// *************************************************************************** *
// *                                                                           *
// * Description:         CANDB File                                           *
// * Generated at:        2025-01-24 12:56                                     *
// * System:              SDB22436                                             *
// * Variant:             L946_ADCU9_ZCUDM                                     *
// * Network:             BodyExposedCAN                                       *
// *                                                                           *
// *************************************************************************** *
VERSION "BodyExposedCAN"

NS_ :

BS_ :

BU_ :  ETC HCML HCMR ZCUD

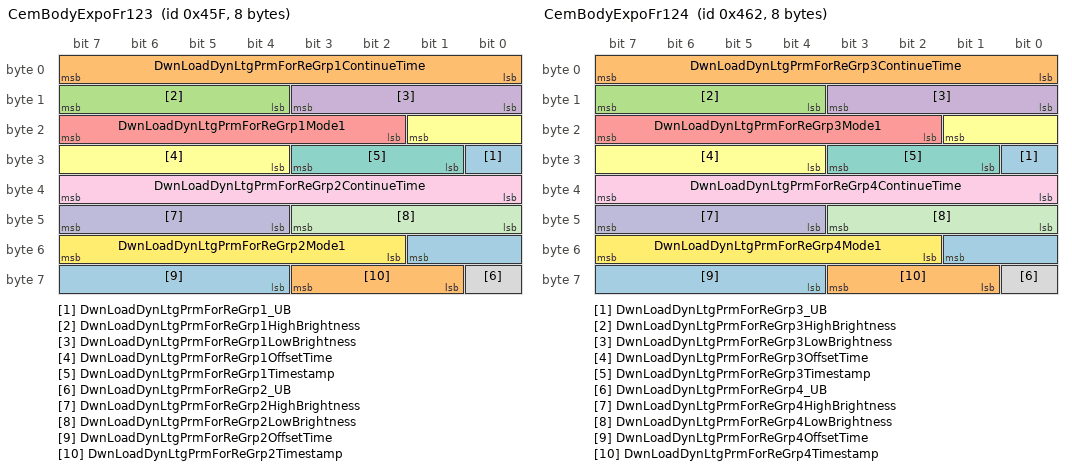
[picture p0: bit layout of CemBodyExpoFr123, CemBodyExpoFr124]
BO_ 1119 CemBodyExpoFr123 : 8 ZCUD
 SG_ DwnLoadDynLtgPrmForReGrp1_UB : 24|1@0+ (1,0) [0|1] "" Vector__XXX
 SG_ DwnLoadDynLtgPrmForReGrp1ContinueTime : 7|8@0+ (1.0,0.0) [0.0|255.0] "Unitless" Vector__XXX
 SG_ DwnLoadDynLtgPrmForReGrp1HighBrightness : 15|4@0+ (1.0,0.0) [0.0|10.0] "Unitless" Vector__XXX
 SG_ DwnLoadDynLtgPrmForReGrp1LowBrightness : 11|4@0+ (1.0,0.0) [0.0|10.0] "Unitless" Vector__XXX
 SG_ DwnLoadDynLtgPrmForReGrp1Mode1 : 23|6@0+ (1,0) [0|63] "" Vector__XXX
 SG_ DwnLoadDynLtgPrmForReGrp1OffsetTime : 17|6@0+ (1.0,0.0) [0.0|63.0] "Unitless" Vector__XXX
 SG_ DwnLoadDynLtgPrmForReGrp1Timestamp : 27|3@0+ (1.0,0.0) [0.0|7.0] "Unitless" Vector__XXX
 SG_ DwnLoadDynLtgPrmForReGrp2_UB : 56|1@0+ (1,0) [0|1] "" Vector__XXX
 SG_ DwnLoadDynLtgPrmForReGrp2ContinueTime : 39|8@0+ (1.0,0.0) [0.0|255.0] "Unitless" Vector__XXX
 SG_ DwnLoadDynLtgPrmForReGrp2HighBrightness : 47|4@0+ (1.0,0.0) [0.0|10.0] "Unitless" Vector__XXX
 SG_ DwnLoadDynLtgPrmForReGrp2LowBrightness : 43|4@0+ (1.0,0.0) [0.0|10.0] "Unitless" Vector__XXX
 SG_ DwnLoadDynLtgPrmForReGrp2Mode1 : 55|6@0+ (1,0) [0|63] "" Vector__XXX
 SG_ DwnLoadDynLtgPrmForReGrp2OffsetTime : 49|6@0+ (1.0,0.0) [0.0|63.0] "Unitless" Vector__XXX
 SG_ DwnLoadDynLtgPrmForReGrp2Timestamp : 59|3@0+ (1.0,0.0) [0.0|7.0] "Unitless" Vector__XXX

BO_ 1122 CemBodyExpoFr124 : 8 ZCUD
 SG_ DwnLoadDynLtgPrmForReGrp3_UB : 24|1@0+ (1,0) [0|1] "" Vector__XXX
 SG_ DwnLoadDynLtgPrmForReGrp3ContinueTime : 7|8@0+ (1.0,0.0) [0.0|255.0] "Unitless" Vector__XXX
 SG_ DwnLoadDynLtgPrmForReGrp3HighBrightness : 15|4@0+ (1.0,0.0) [0.0|10.0] "Unitless" Vector__XXX
 SG_ DwnLoadDynLtgPrmForReGrp3LowBrightness : 11|4@0+ (1.0,0.0) [0.0|10.0] "Unitless" Vector__XXX
 SG_ DwnLoadDynLtgPrmForReGrp3Mode1 : 23|6@0+ (1,0) [0|63] "" Vector__XXX
 SG_ DwnLoadDynLtgPrmForReGrp3OffsetTime : 17|6@0+ (1.0,0.0) [0.0|63.0] "Unitless" Vector__XXX
 SG_ DwnLoadDynLtgPrmForReGrp3Timestamp : 27|3@0+ (1.0,0.0) [0.0|7.0] "Unitless" Vector__XXX
 SG_ DwnLoadDynLtgPrmForReGrp4_UB : 56|1@0+ (1,0) [0|1] "" Vector__XXX
 SG_ DwnLoadDynLtgPrmForReGrp4ContinueTime : 39|8@0+ (1.0,0.0) [0.0|255.0] "Unitless" Vector__XXX
 SG_ DwnLoadDynLtgPrmForReGrp4HighBrightness : 47|4@0+ (1.0,0.0) [0.0|10.0] "Unitless" Vector__XXX
 SG_ DwnLoadDynLtgPrmForReGrp4LowBrightness : 43|4@0+ (1.0,0.0) [0.0|10.0] "Unitless" Vector__XXX
 SG_ DwnLoadDynLtgPrmForReGrp4Mode1 : 55|6@0+ (1,0) [0|63] "" Vector__XXX
 SG_ DwnLoadDynLtgPrmForReGrp4OffsetTime : 49|6@0+ (1.0,0.0) [0.0|63.0] "Unitless" Vector__XXX
 SG_ DwnLoadDynLtgPrmForReGrp4Timestamp : 59|3@0+ (1.0,0.0) [0.0|7.0] "Unitless" Vector__XXX

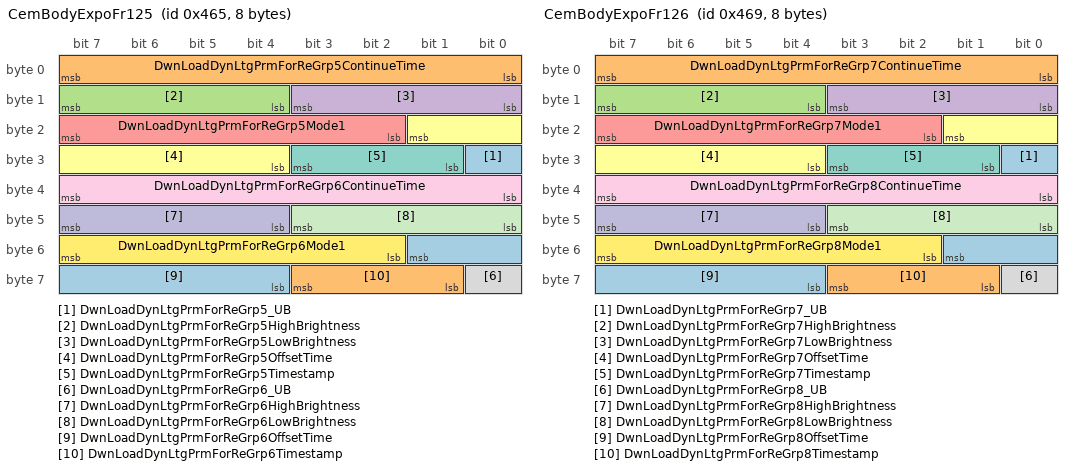
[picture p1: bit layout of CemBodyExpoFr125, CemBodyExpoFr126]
BO_ 1125 CemBodyExpoFr125 : 8 ZCUD
 SG_ DwnLoadDynLtgPrmForReGrp5_UB : 24|1@0+ (1,0) [0|1] "" Vector__XXX
 SG_ DwnLoadDynLtgPrmForReGrp5ContinueTime : 7|8@0+ (1.0,0.0) [0.0|255.0] "Unitless" Vector__XXX
 SG_ DwnLoadDynLtgPrmForReGrp5HighBrightness : 15|4@0+ (1.0,0.0) [0.0|10.0] "Unitless" Vector__XXX
 SG_ DwnLoadDynLtgPrmForReGrp5LowBrightness : 11|4@0+ (1.0,0.0) [0.0|10.0] "Unitless" Vector__XXX
 SG_ DwnLoadDynLtgPrmForReGrp5Mode1 : 23|6@0+ (1,0) [0|63] "" Vector__XXX
 SG_ DwnLoadDynLtgPrmForReGrp5OffsetTime : 17|6@0+ (1.0,0.0) [0.0|63.0] "Unitless" Vector__XXX
 SG_ DwnLoadDynLtgPrmForReGrp5Timestamp : 27|3@0+ (1.0,0.0) [0.0|7.0] "Unitless" Vector__XXX
 SG_ DwnLoadDynLtgPrmForReGrp6_UB : 56|1@0+ (1,0) [0|1] "" Vector__XXX
 SG_ DwnLoadDynLtgPrmForReGrp6ContinueTime : 39|8@0+ (1.0,0.0) [0.0|255.0] "Unitless" Vector__XXX
 SG_ DwnLoadDynLtgPrmForReGrp6HighBrightness : 47|4@0+ (1.0,0.0) [0.0|10.0] "Unitless" Vector__XXX
 SG_ DwnLoadDynLtgPrmForReGrp6LowBrightness : 43|4@0+ (1.0,0.0) [0.0|10.0] "Unitless" Vector__XXX
 SG_ DwnLoadDynLtgPrmForReGrp6Mode1 : 55|6@0+ (1,0) [0|63] "" Vector__XXX
 SG_ DwnLoadDynLtgPrmForReGrp6OffsetTime : 49|6@0+ (1.0,0.0) [0.0|63.0] "Unitless" Vector__XXX
 SG_ DwnLoadDynLtgPrmForReGrp6Timestamp : 59|3@0+ (1.0,0.0) [0.0|7.0] "Unitless" Vector__XXX

BO_ 1129 CemBodyExpoFr126 : 8 ZCUD
 SG_ DwnLoadDynLtgPrmForReGrp7_UB : 24|1@0+ (1,0) [0|1] "" Vector__XXX
 SG_ DwnLoadDynLtgPrmForReGrp7ContinueTime : 7|8@0+ (1.0,0.0) [0.0|255.0] "Unitless" Vector__XXX
 SG_ DwnLoadDynLtgPrmForReGrp7HighBrightness : 15|4@0+ (1.0,0.0) [0.0|10.0] "Unitless" Vector__XXX
 SG_ DwnLoadDynLtgPrmForReGrp7LowBrightness : 11|4@0+ (1.0,0.0) [0.0|10.0] "Unitless" Vector__XXX
 SG_ DwnLoadDynLtgPrmForReGrp7Mode1 : 23|6@0+ (1,0) [0|63] "" Vector__XXX
 SG_ DwnLoadDynLtgPrmForReGrp7OffsetTime : 17|6@0+ (1.0,0.0) [0.0|63.0] "Unitless" Vector__XXX
 SG_ DwnLoadDynLtgPrmForReGrp7Timestamp : 27|3@0+ (1.0,0.0) [0.0|7.0] "Unitless" Vector__XXX
 SG_ DwnLoadDynLtgPrmForReGrp8_UB : 56|1@0+ (1,0) [0|1] "" Vector__XXX
 SG_ DwnLoadDynLtgPrmForReGrp8ContinueTime : 39|8@0+ (1.0,0.0) [0.0|255.0] "Unitless" Vector__XXX
 SG_ DwnLoadDynLtgPrmForReGrp8HighBrightness : 47|4@0+ (1.0,0.0) [0.0|10.0] "Unitless" Vector__XXX
 SG_ DwnLoadDynLtgPrmForReGrp8LowBrightness : 43|4@0+ (1.0,0.0) [0.0|10.0] "Unitless" Vector__XXX
 SG_ DwnLoadDynLtgPrmForReGrp8Mode1 : 55|6@0+ (1,0) [0|63] "" Vector__XXX
 SG_ DwnLoadDynLtgPrmForReGrp8OffsetTime : 49|6@0+ (1.0,0.0) [0.0|63.0] "Unitless" Vector__XXX
 SG_ DwnLoadDynLtgPrmForReGrp8Timestamp : 59|3@0+ (1.0,0.0) [0.0|7.0] "Unitless" Vector__XXX

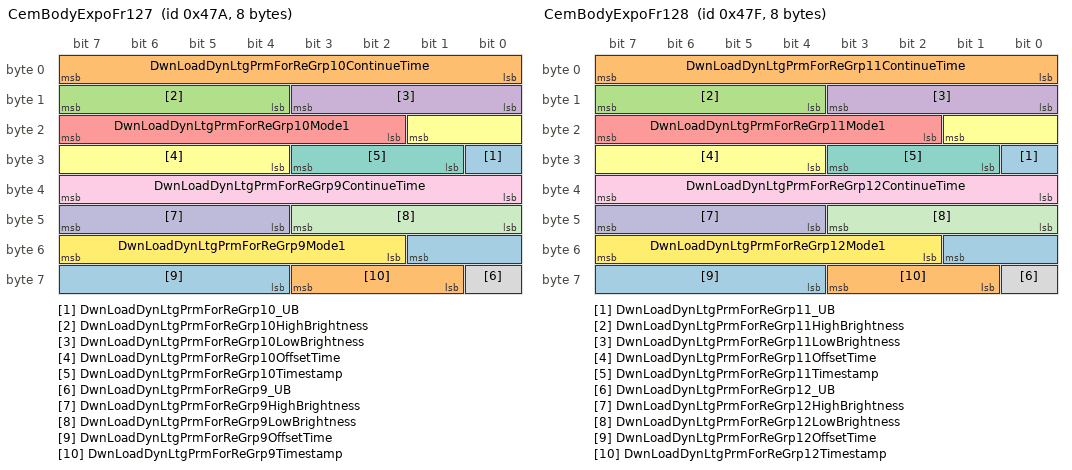
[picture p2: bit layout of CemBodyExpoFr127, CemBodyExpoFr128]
BO_ 1146 CemBodyExpoFr127 : 8 ZCUD
 SG_ DwnLoadDynLtgPrmForReGrp10_UB : 24|1@0+ (1,0) [0|1] "" Vector__XXX
 SG_ DwnLoadDynLtgPrmForReGrp10ContinueTime : 7|8@0+ (1.0,0.0) [0.0|255.0] "Unitless" Vector__XXX
 SG_ DwnLoadDynLtgPrmForReGrp10HighBrightness : 15|4@0+ (1.0,0.0) [0.0|10.0] "Unitless" Vector__XXX
 SG_ DwnLoadDynLtgPrmForReGrp10LowBrightness : 11|4@0+ (1.0,0.0) [0.0|10.0] "Unitless" Vector__XXX
 SG_ DwnLoadDynLtgPrmForReGrp10Mode1 : 23|6@0+ (1,0) [0|63] "" Vector__XXX
 SG_ DwnLoadDynLtgPrmForReGrp10OffsetTime : 17|6@0+ (1.0,0.0) [0.0|63.0] "Unitless" Vector__XXX
 SG_ DwnLoadDynLtgPrmForReGrp10Timestamp : 27|3@0+ (1.0,0.0) [0.0|7.0] "Unitless" Vector__XXX
 SG_ DwnLoadDynLtgPrmForReGrp9_UB : 56|1@0+ (1,0) [0|1] "" Vector__XXX
 SG_ DwnLoadDynLtgPrmForReGrp9ContinueTime : 39|8@0+ (1.0,0.0) [0.0|255.0] "Unitless" Vector__XXX
 SG_ DwnLoadDynLtgPrmForReGrp9HighBrightness : 47|4@0+ (1.0,0.0) [0.0|10.0] "Unitless" Vector__XXX
 SG_ DwnLoadDynLtgPrmForReGrp9LowBrightness : 43|4@0+ (1.0,0.0) [0.0|10.0] "Unitless" Vector__XXX
 SG_ DwnLoadDynLtgPrmForReGrp9Mode1 : 55|6@0+ (1,0) [0|63] "" Vector__XXX
 SG_ DwnLoadDynLtgPrmForReGrp9OffsetTime : 49|6@0+ (1.0,0.0) [0.0|63.0] "Unitless" Vector__XXX
 SG_ DwnLoadDynLtgPrmForReGrp9Timestamp : 59|3@0+ (1.0,0.0) [0.0|7.0] "Unitless" Vector__XXX

BO_ 1151 CemBodyExpoFr128 : 8 ZCUD
 SG_ DwnLoadDynLtgPrmForReGrp11_UB : 24|1@0+ (1,0) [0|1] "" Vector__XXX
 SG_ DwnLoadDynLtgPrmForReGrp11ContinueTime : 7|8@0+ (1.0,0.0) [0.0|255.0] "Unitless" Vector__XXX
 SG_ DwnLoadDynLtgPrmForReGrp11HighBrightness : 15|4@0+ (1.0,0.0) [0.0|10.0] "Unitless" Vector__XXX
 SG_ DwnLoadDynLtgPrmForReGrp11LowBrightness : 11|4@0+ (1.0,0.0) [0.0|10.0] "Unitless" Vector__XXX
 SG_ DwnLoadDynLtgPrmForReGrp11Mode1 : 23|6@0+ (1,0) [0|63] "" Vector__XXX
 SG_ DwnLoadDynLtgPrmForReGrp11OffsetTime : 17|6@0+ (1.0,0.0) [0.0|63.0] "Unitless" Vector__XXX
 SG_ DwnLoadDynLtgPrmForReGrp11Timestamp : 27|3@0+ (1.0,0.0) [0.0|7.0] "Unitless" Vector__XXX
 SG_ DwnLoadDynLtgPrmForReGrp12_UB : 56|1@0+ (1,0) [0|1] "" Vector__XXX
 SG_ DwnLoadDynLtgPrmForReGrp12ContinueTime : 39|8@0+ (1.0,0.0) [0.0|255.0] "Unitless" Vector__XXX
 SG_ DwnLoadDynLtgPrmForReGrp12HighBrightness : 47|4@0+ (1.0,0.0) [0.0|10.0] "Unitless" Vector__XXX
 SG_ DwnLoadDynLtgPrmForReGrp12LowBrightness : 43|4@0+ (1.0,0.0) [0.0|10.0] "Unitless" Vector__XXX
 SG_ DwnLoadDynLtgPrmForReGrp12Mode1 : 55|6@0+ (1,0) [0|63] "" Vector__XXX
 SG_ DwnLoadDynLtgPrmForReGrp12OffsetTime : 49|6@0+ (1.0,0.0) [0.0|63.0] "Unitless" Vector__XXX
 SG_ DwnLoadDynLtgPrmForReGrp12Timestamp : 59|3@0+ (1.0,0.0) [0.0|7.0] "Unitless" Vector__XXX

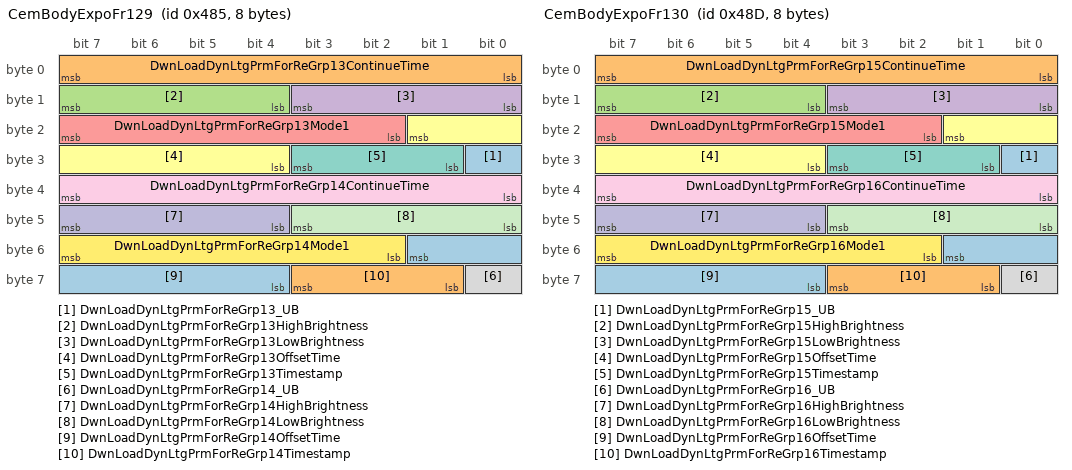
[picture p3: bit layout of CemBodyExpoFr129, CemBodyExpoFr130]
BO_ 1157 CemBodyExpoFr129 : 8 ZCUD
 SG_ DwnLoadDynLtgPrmForReGrp13_UB : 24|1@0+ (1,0) [0|1] "" Vector__XXX
 SG_ DwnLoadDynLtgPrmForReGrp13ContinueTime : 7|8@0+ (1.0,0.0) [0.0|255.0] "Unitless" Vector__XXX
 SG_ DwnLoadDynLtgPrmForReGrp13HighBrightness : 15|4@0+ (1.0,0.0) [0.0|10.0] "Unitless" Vector__XXX
 SG_ DwnLoadDynLtgPrmForReGrp13LowBrightness : 11|4@0+ (1.0,0.0) [0.0|10.0] "Unitless" Vector__XXX
 SG_ DwnLoadDynLtgPrmForReGrp13Mode1 : 23|6@0+ (1,0) [0|63] "" Vector__XXX
 SG_ DwnLoadDynLtgPrmForReGrp13OffsetTime : 17|6@0+ (1.0,0.0) [0.0|63.0] "Unitless" Vector__XXX
 SG_ DwnLoadDynLtgPrmForReGrp13Timestamp : 27|3@0+ (1.0,0.0) [0.0|7.0] "Unitless" Vector__XXX
 SG_ DwnLoadDynLtgPrmForReGrp14_UB : 56|1@0+ (1,0) [0|1] "" Vector__XXX
 SG_ DwnLoadDynLtgPrmForReGrp14ContinueTime : 39|8@0+ (1.0,0.0) [0.0|255.0] "Unitless" Vector__XXX
 SG_ DwnLoadDynLtgPrmForReGrp14HighBrightness : 47|4@0+ (1.0,0.0) [0.0|10.0] "Unitless" Vector__XXX
 SG_ DwnLoadDynLtgPrmForReGrp14LowBrightness : 43|4@0+ (1.0,0.0) [0.0|10.0] "Unitless" Vector__XXX
 SG_ DwnLoadDynLtgPrmForReGrp14Mode1 : 55|6@0+ (1,0) [0|63] "" Vector__XXX
 SG_ DwnLoadDynLtgPrmForReGrp14OffsetTime : 49|6@0+ (1.0,0.0) [0.0|63.0] "Unitless" Vector__XXX
 SG_ DwnLoadDynLtgPrmForReGrp14Timestamp : 59|3@0+ (1.0,0.0) [0.0|7.0] "Unitless" Vector__XXX

BO_ 1165 CemBodyExpoFr130 : 8 ZCUD
 SG_ DwnLoadDynLtgPrmForReGrp15_UB : 24|1@0+ (1,0) [0|1] "" Vector__XXX
 SG_ DwnLoadDynLtgPrmForReGrp15ContinueTime : 7|8@0+ (1.0,0.0) [0.0|255.0] "Unitless" Vector__XXX
 SG_ DwnLoadDynLtgPrmForReGrp15HighBrightness : 15|4@0+ (1.0,0.0) [0.0|10.0] "Unitless" Vector__XXX
 SG_ DwnLoadDynLtgPrmForReGrp15LowBrightness : 11|4@0+ (1.0,0.0) [0.0|10.0] "Unitless" Vector__XXX
 SG_ DwnLoadDynLtgPrmForReGrp15Mode1 : 23|6@0+ (1,0) [0|63] "" Vector__XXX
 SG_ DwnLoadDynLtgPrmForReGrp15OffsetTime : 17|6@0+ (1.0,0.0) [0.0|63.0] "Unitless" Vector__XXX
 SG_ DwnLoadDynLtgPrmForReGrp15Timestamp : 27|3@0+ (1.0,0.0) [0.0|7.0] "Unitless" Vector__XXX
 SG_ DwnLoadDynLtgPrmForReGrp16_UB : 56|1@0+ (1,0) [0|1] "" Vector__XXX
 SG_ DwnLoadDynLtgPrmForReGrp16ContinueTime : 39|8@0+ (1.0,0.0) [0.0|255.0] "Unitless" Vector__XXX
 SG_ DwnLoadDynLtgPrmForReGrp16HighBrightness : 47|4@0+ (1.0,0.0) [0.0|10.0] "Unitless" Vector__XXX
 SG_ DwnLoadDynLtgPrmForReGrp16LowBrightness : 43|4@0+ (1.0,0.0) [0.0|10.0] "Unitless" Vector__XXX
 SG_ DwnLoadDynLtgPrmForReGrp16Mode1 : 55|6@0+ (1,0) [0|63] "" Vector__XXX
 SG_ DwnLoadDynLtgPrmForReGrp16OffsetTime : 49|6@0+ (1.0,0.0) [0.0|63.0] "Unitless" Vector__XXX
 SG_ DwnLoadDynLtgPrmForReGrp16Timestamp : 59|3@0+ (1.0,0.0) [0.0|7.0] "Unitless" Vector__XXX

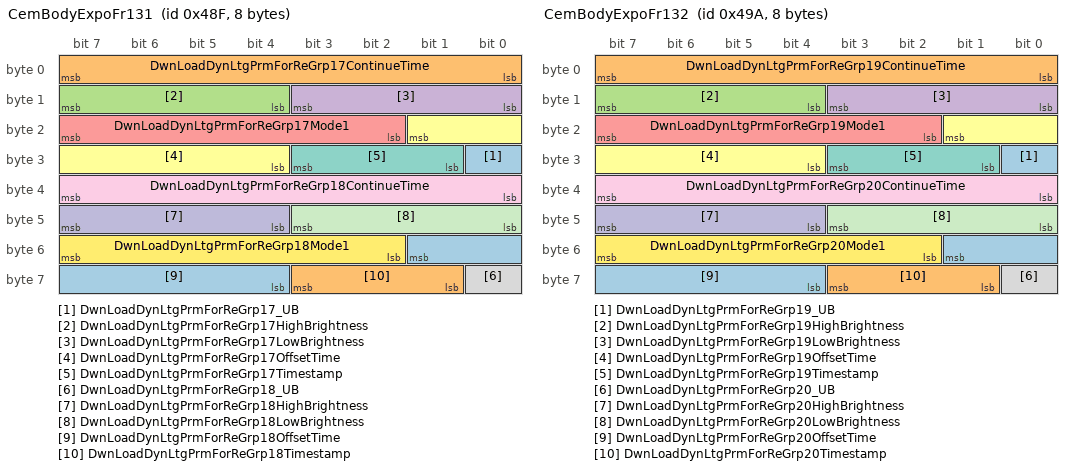
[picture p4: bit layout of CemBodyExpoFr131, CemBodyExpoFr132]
BO_ 1167 CemBodyExpoFr131 : 8 ZCUD
 SG_ DwnLoadDynLtgPrmForReGrp17_UB : 24|1@0+ (1,0) [0|1] "" Vector__XXX
 SG_ DwnLoadDynLtgPrmForReGrp17ContinueTime : 7|8@0+ (1.0,0.0) [0.0|255.0] "Unitless" Vector__XXX
 SG_ DwnLoadDynLtgPrmForReGrp17HighBrightness : 15|4@0+ (1.0,0.0) [0.0|10.0] "Unitless" Vector__XXX
 SG_ DwnLoadDynLtgPrmForReGrp17LowBrightness : 11|4@0+ (1.0,0.0) [0.0|10.0] "Unitless" Vector__XXX
 SG_ DwnLoadDynLtgPrmForReGrp17Mode1 : 23|6@0+ (1,0) [0|63] "" Vector__XXX
 SG_ DwnLoadDynLtgPrmForReGrp17OffsetTime : 17|6@0+ (1.0,0.0) [0.0|63.0] "Unitless" Vector__XXX
 SG_ DwnLoadDynLtgPrmForReGrp17Timestamp : 27|3@0+ (1.0,0.0) [0.0|7.0] "Unitless" Vector__XXX
 SG_ DwnLoadDynLtgPrmForReGrp18_UB : 56|1@0+ (1,0) [0|1] "" Vector__XXX
 SG_ DwnLoadDynLtgPrmForReGrp18ContinueTime : 39|8@0+ (1.0,0.0) [0.0|255.0] "Unitless" Vector__XXX
 SG_ DwnLoadDynLtgPrmForReGrp18HighBrightness : 47|4@0+ (1.0,0.0) [0.0|10.0] "Unitless" Vector__XXX
 SG_ DwnLoadDynLtgPrmForReGrp18LowBrightness : 43|4@0+ (1.0,0.0) [0.0|10.0] "Unitless" Vector__XXX
 SG_ DwnLoadDynLtgPrmForReGrp18Mode1 : 55|6@0+ (1,0) [0|63] "" Vector__XXX
 SG_ DwnLoadDynLtgPrmForReGrp18OffsetTime : 49|6@0+ (1.0,0.0) [0.0|63.0] "Unitless" Vector__XXX
 SG_ DwnLoadDynLtgPrmForReGrp18Timestamp : 59|3@0+ (1.0,0.0) [0.0|7.0] "Unitless" Vector__XXX

BO_ 1178 CemBodyExpoFr132 : 8 ZCUD
 SG_ DwnLoadDynLtgPrmForReGrp19_UB : 24|1@0+ (1,0) [0|1] "" Vector__XXX
 SG_ DwnLoadDynLtgPrmForReGrp19ContinueTime : 7|8@0+ (1.0,0.0) [0.0|255.0] "Unitless" Vector__XXX
 SG_ DwnLoadDynLtgPrmForReGrp19HighBrightness : 15|4@0+ (1.0,0.0) [0.0|10.0] "Unitless" Vector__XXX
 SG_ DwnLoadDynLtgPrmForReGrp19LowBrightness : 11|4@0+ (1.0,0.0) [0.0|10.0] "Unitless" Vector__XXX
 SG_ DwnLoadDynLtgPrmForReGrp19Mode1 : 23|6@0+ (1,0) [0|63] "" Vector__XXX
 SG_ DwnLoadDynLtgPrmForReGrp19OffsetTime : 17|6@0+ (1.0,0.0) [0.0|63.0] "Unitless" Vector__XXX
 SG_ DwnLoadDynLtgPrmForReGrp19Timestamp : 27|3@0+ (1.0,0.0) [0.0|7.0] "Unitless" Vector__XXX
 SG_ DwnLoadDynLtgPrmForReGrp20_UB : 56|1@0+ (1,0) [0|1] "" Vector__XXX
 SG_ DwnLoadDynLtgPrmForReGrp20ContinueTime : 39|8@0+ (1.0,0.0) [0.0|255.0] "Unitless" Vector__XXX
 SG_ DwnLoadDynLtgPrmForReGrp20HighBrightness : 47|4@0+ (1.0,0.0) [0.0|10.0] "Unitless" Vector__XXX
 SG_ DwnLoadDynLtgPrmForReGrp20LowBrightness : 43|4@0+ (1.0,0.0) [0.0|10.0] "Unitless" Vector__XXX
 SG_ DwnLoadDynLtgPrmForReGrp20Mode1 : 55|6@0+ (1,0) [0|63] "" Vector__XXX
 SG_ DwnLoadDynLtgPrmForReGrp20OffsetTime : 49|6@0+ (1.0,0.0) [0.0|63.0] "Unitless" Vector__XXX
 SG_ DwnLoadDynLtgPrmForReGrp20Timestamp : 59|3@0+ (1.0,0.0) [0.0|7.0] "Unitless" Vector__XXX

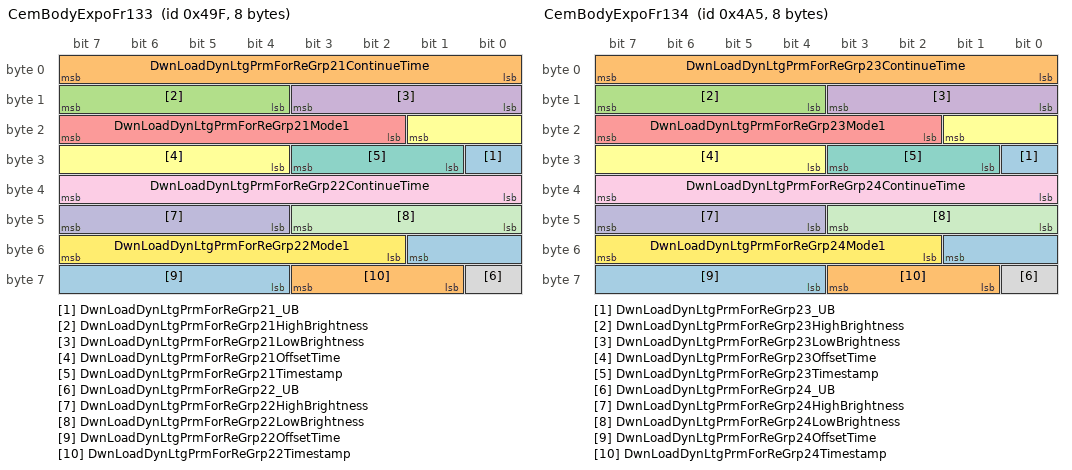
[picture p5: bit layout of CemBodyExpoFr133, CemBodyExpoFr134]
BO_ 1183 CemBodyExpoFr133 : 8 ZCUD
 SG_ DwnLoadDynLtgPrmForReGrp21_UB : 24|1@0+ (1,0) [0|1] "" Vector__XXX
 SG_ DwnLoadDynLtgPrmForReGrp21ContinueTime : 7|8@0+ (1.0,0.0) [0.0|255.0] "Unitless" Vector__XXX
 SG_ DwnLoadDynLtgPrmForReGrp21HighBrightness : 15|4@0+ (1.0,0.0) [0.0|10.0] "Unitless" Vector__XXX
 SG_ DwnLoadDynLtgPrmForReGrp21LowBrightness : 11|4@0+ (1.0,0.0) [0.0|10.0] "Unitless" Vector__XXX
 SG_ DwnLoadDynLtgPrmForReGrp21Mode1 : 23|6@0+ (1,0) [0|63] "" Vector__XXX
 SG_ DwnLoadDynLtgPrmForReGrp21OffsetTime : 17|6@0+ (1.0,0.0) [0.0|63.0] "Unitless" Vector__XXX
 SG_ DwnLoadDynLtgPrmForReGrp21Timestamp : 27|3@0+ (1.0,0.0) [0.0|7.0] "Unitless" Vector__XXX
 SG_ DwnLoadDynLtgPrmForReGrp22_UB : 56|1@0+ (1,0) [0|1] "" Vector__XXX
 SG_ DwnLoadDynLtgPrmForReGrp22ContinueTime : 39|8@0+ (1.0,0.0) [0.0|255.0] "Unitless" Vector__XXX
 SG_ DwnLoadDynLtgPrmForReGrp22HighBrightness : 47|4@0+ (1.0,0.0) [0.0|10.0] "Unitless" Vector__XXX
 SG_ DwnLoadDynLtgPrmForReGrp22LowBrightness : 43|4@0+ (1.0,0.0) [0.0|10.0] "Unitless" Vector__XXX
 SG_ DwnLoadDynLtgPrmForReGrp22Mode1 : 55|6@0+ (1,0) [0|63] "" Vector__XXX
 SG_ DwnLoadDynLtgPrmForReGrp22OffsetTime : 49|6@0+ (1.0,0.0) [0.0|63.0] "Unitless" Vector__XXX
 SG_ DwnLoadDynLtgPrmForReGrp22Timestamp : 59|3@0+ (1.0,0.0) [0.0|7.0] "Unitless" Vector__XXX

BO_ 1189 CemBodyExpoFr134 : 8 ZCUD
 SG_ DwnLoadDynLtgPrmForReGrp23_UB : 24|1@0+ (1,0) [0|1] "" Vector__XXX
 SG_ DwnLoadDynLtgPrmForReGrp23ContinueTime : 7|8@0+ (1.0,0.0) [0.0|255.0] "Unitless" Vector__XXX
 SG_ DwnLoadDynLtgPrmForReGrp23HighBrightness : 15|4@0+ (1.0,0.0) [0.0|10.0] "Unitless" Vector__XXX
 SG_ DwnLoadDynLtgPrmForReGrp23LowBrightness : 11|4@0+ (1.0,0.0) [0.0|10.0] "Unitless" Vector__XXX
 SG_ DwnLoadDynLtgPrmForReGrp23Mode1 : 23|6@0+ (1,0) [0|63] "" Vector__XXX
 SG_ DwnLoadDynLtgPrmForReGrp23OffsetTime : 17|6@0+ (1.0,0.0) [0.0|63.0] "Unitless" Vector__XXX
 SG_ DwnLoadDynLtgPrmForReGrp23Timestamp : 27|3@0+ (1.0,0.0) [0.0|7.0] "Unitless" Vector__XXX
 SG_ DwnLoadDynLtgPrmForReGrp24_UB : 56|1@0+ (1,0) [0|1] "" Vector__XXX
 SG_ DwnLoadDynLtgPrmForReGrp24ContinueTime : 39|8@0+ (1.0,0.0) [0.0|255.0] "Unitless" Vector__XXX
 SG_ DwnLoadDynLtgPrmForReGrp24HighBrightness : 47|4@0+ (1.0,0.0) [0.0|10.0] "Unitless" Vector__XXX
 SG_ DwnLoadDynLtgPrmForReGrp24LowBrightness : 43|4@0+ (1.0,0.0) [0.0|10.0] "Unitless" Vector__XXX
 SG_ DwnLoadDynLtgPrmForReGrp24Mode1 : 55|6@0+ (1,0) [0|63] "" Vector__XXX
 SG_ DwnLoadDynLtgPrmForReGrp24OffsetTime : 49|6@0+ (1.0,0.0) [0.0|63.0] "Unitless" Vector__XXX
 SG_ DwnLoadDynLtgPrmForReGrp24Timestamp : 59|3@0+ (1.0,0.0) [0.0|7.0] "Unitless" Vector__XXX

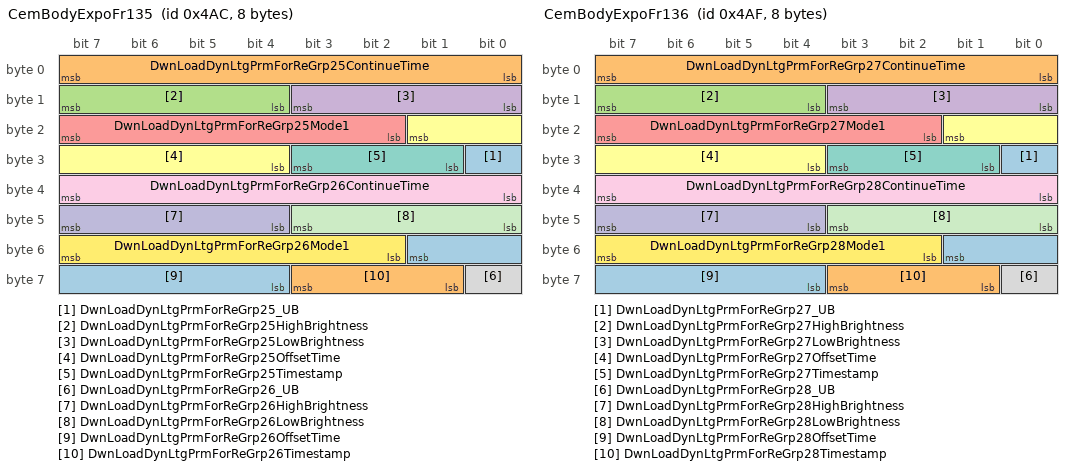
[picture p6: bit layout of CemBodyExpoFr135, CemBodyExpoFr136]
BO_ 1196 CemBodyExpoFr135 : 8 ZCUD
 SG_ DwnLoadDynLtgPrmForReGrp25_UB : 24|1@0+ (1,0) [0|1] "" Vector__XXX
 SG_ DwnLoadDynLtgPrmForReGrp25ContinueTime : 7|8@0+ (1.0,0.0) [0.0|255.0] "Unitless" Vector__XXX
 SG_ DwnLoadDynLtgPrmForReGrp25HighBrightness : 15|4@0+ (1.0,0.0) [0.0|10.0] "Unitless" Vector__XXX
 SG_ DwnLoadDynLtgPrmForReGrp25LowBrightness : 11|4@0+ (1.0,0.0) [0.0|10.0] "Unitless" Vector__XXX
 SG_ DwnLoadDynLtgPrmForReGrp25Mode1 : 23|6@0+ (1,0) [0|63] "" Vector__XXX
 SG_ DwnLoadDynLtgPrmForReGrp25OffsetTime : 17|6@0+ (1.0,0.0) [0.0|63.0] "Unitless" Vector__XXX
 SG_ DwnLoadDynLtgPrmForReGrp25Timestamp : 27|3@0+ (1.0,0.0) [0.0|7.0] "Unitless" Vector__XXX
 SG_ DwnLoadDynLtgPrmForReGrp26_UB : 56|1@0+ (1,0) [0|1] "" Vector__XXX
 SG_ DwnLoadDynLtgPrmForReGrp26ContinueTime : 39|8@0+ (1.0,0.0) [0.0|255.0] "Unitless" Vector__XXX
 SG_ DwnLoadDynLtgPrmForReGrp26HighBrightness : 47|4@0+ (1.0,0.0) [0.0|10.0] "Unitless" Vector__XXX
 SG_ DwnLoadDynLtgPrmForReGrp26LowBrightness : 43|4@0+ (1.0,0.0) [0.0|10.0] "Unitless" Vector__XXX
 SG_ DwnLoadDynLtgPrmForReGrp26Mode1 : 55|6@0+ (1,0) [0|63] "" Vector__XXX
 SG_ DwnLoadDynLtgPrmForReGrp26OffsetTime : 49|6@0+ (1.0,0.0) [0.0|63.0] "Unitless" Vector__XXX
 SG_ DwnLoadDynLtgPrmForReGrp26Timestamp : 59|3@0+ (1.0,0.0) [0.0|7.0] "Unitless" Vector__XXX

BO_ 1199 CemBodyExpoFr136 : 8 ZCUD
 SG_ DwnLoadDynLtgPrmForReGrp27_UB : 24|1@0+ (1,0) [0|1] "" Vector__XXX
 SG_ DwnLoadDynLtgPrmForReGrp27ContinueTime : 7|8@0+ (1.0,0.0) [0.0|255.0] "Unitless" Vector__XXX
 SG_ DwnLoadDynLtgPrmForReGrp27HighBrightness : 15|4@0+ (1.0,0.0) [0.0|10.0] "Unitless" Vector__XXX
 SG_ DwnLoadDynLtgPrmForReGrp27LowBrightness : 11|4@0+ (1.0,0.0) [0.0|10.0] "Unitless" Vector__XXX
 SG_ DwnLoadDynLtgPrmForReGrp27Mode1 : 23|6@0+ (1,0) [0|63] "" Vector__XXX
 SG_ DwnLoadDynLtgPrmForReGrp27OffsetTime : 17|6@0+ (1.0,0.0) [0.0|63.0] "Unitless" Vector__XXX
 SG_ DwnLoadDynLtgPrmForReGrp27Timestamp : 27|3@0+ (1.0,0.0) [0.0|7.0] "Unitless" Vector__XXX
 SG_ DwnLoadDynLtgPrmForReGrp28_UB : 56|1@0+ (1,0) [0|1] "" Vector__XXX
 SG_ DwnLoadDynLtgPrmForReGrp28ContinueTime : 39|8@0+ (1.0,0.0) [0.0|255.0] "Unitless" Vector__XXX
 SG_ DwnLoadDynLtgPrmForReGrp28HighBrightness : 47|4@0+ (1.0,0.0) [0.0|10.0] "Unitless" Vector__XXX
 SG_ DwnLoadDynLtgPrmForReGrp28LowBrightness : 43|4@0+ (1.0,0.0) [0.0|10.0] "Unitless" Vector__XXX
 SG_ DwnLoadDynLtgPrmForReGrp28Mode1 : 55|6@0+ (1,0) [0|63] "" Vector__XXX
 SG_ DwnLoadDynLtgPrmForReGrp28OffsetTime : 49|6@0+ (1.0,0.0) [0.0|63.0] "Unitless" Vector__XXX
 SG_ DwnLoadDynLtgPrmForReGrp28Timestamp : 59|3@0+ (1.0,0.0) [0.0|7.0] "Unitless" Vector__XXX

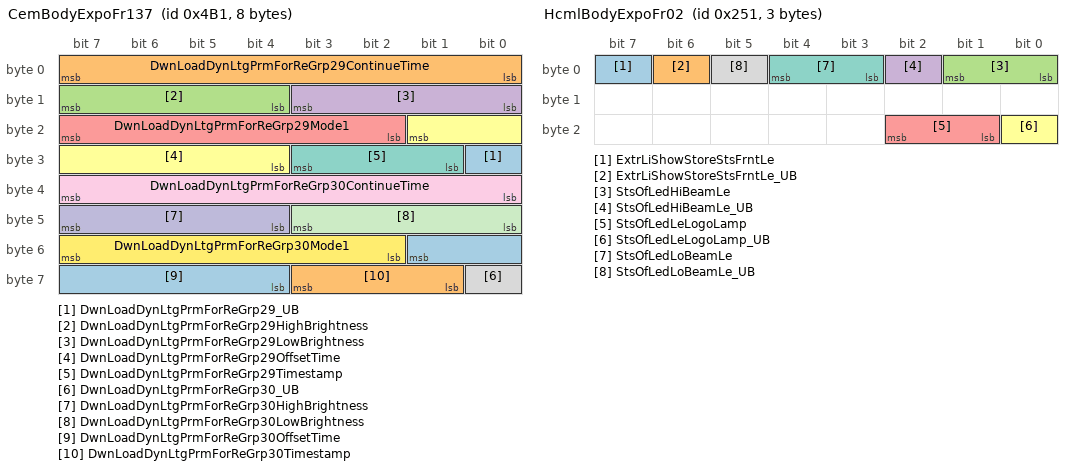
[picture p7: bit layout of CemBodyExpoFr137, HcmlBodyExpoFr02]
BO_ 1201 CemBodyExpoFr137 : 8 ZCUD
 SG_ DwnLoadDynLtgPrmForReGrp29_UB : 24|1@0+ (1,0) [0|1] "" Vector__XXX
 SG_ DwnLoadDynLtgPrmForReGrp29ContinueTime : 7|8@0+ (1.0,0.0) [0.0|255.0] "Unitless" Vector__XXX
 SG_ DwnLoadDynLtgPrmForReGrp29HighBrightness : 15|4@0+ (1.0,0.0) [0.0|10.0] "Unitless" Vector__XXX
 SG_ DwnLoadDynLtgPrmForReGrp29LowBrightness : 11|4@0+ (1.0,0.0) [0.0|10.0] "Unitless" Vector__XXX
 SG_ DwnLoadDynLtgPrmForReGrp29Mode1 : 23|6@0+ (1,0) [0|63] "" Vector__XXX
 SG_ DwnLoadDynLtgPrmForReGrp29OffsetTime : 17|6@0+ (1.0,0.0) [0.0|63.0] "Unitless" Vector__XXX
 SG_ DwnLoadDynLtgPrmForReGrp29Timestamp : 27|3@0+ (1.0,0.0) [0.0|7.0] "Unitless" Vector__XXX
 SG_ DwnLoadDynLtgPrmForReGrp30_UB : 56|1@0+ (1,0) [0|1] "" Vector__XXX
 SG_ DwnLoadDynLtgPrmForReGrp30ContinueTime : 39|8@0+ (1.0,0.0) [0.0|255.0] "Unitless" Vector__XXX
 SG_ DwnLoadDynLtgPrmForReGrp30HighBrightness : 47|4@0+ (1.0,0.0) [0.0|10.0] "Unitless" Vector__XXX
 SG_ DwnLoadDynLtgPrmForReGrp30LowBrightness : 43|4@0+ (1.0,0.0) [0.0|10.0] "Unitless" Vector__XXX
 SG_ DwnLoadDynLtgPrmForReGrp30Mode1 : 55|6@0+ (1,0) [0|63] "" Vector__XXX
 SG_ DwnLoadDynLtgPrmForReGrp30OffsetTime : 49|6@0+ (1.0,0.0) [0.0|63.0] "Unitless" Vector__XXX
 SG_ DwnLoadDynLtgPrmForReGrp30Timestamp : 59|3@0+ (1.0,0.0) [0.0|7.0] "Unitless" Vector__XXX

BO_ 1969 CemToDpod2BodyCanExposedDiagReqFrame : 8 ZCUD

BO_ 1968 CemToLpod2BodyCanExposedDiagReqFrame : 8 ZCUD

BO_ 1980 CemToPpod2BodyCanExposedDiagReqFrame : 8 ZCUD

BO_ 1979 CemToRpod2BodyCanExposedDiagReqFrame : 8 ZCUD

BO_ 1430 EtctoHcmlXCPFr01 : 8 ETC

BO_ 1428 EtctoHcmrXCPFr01 : 8 ETC

BO_ 593 HcmlBodyExpoFr02 : 3 HCML
 SG_ ExtrLiShowStoreStsFrntLe : 7|1@0+ (1,0) [0|1] "" ZCUD
 SG_ ExtrLiShowStoreStsFrntLe_UB : 6|1@0+ (1,0) [0|1] "" ZCUD
 SG_ StsOfLedHiBeamLe : 1|2@0+ (1,0) [0|3] "" ZCUD
 SG_ StsOfLedHiBeamLe_UB : 2|1@0+ (1,0) [0|1] "" ZCUD
 SG_ StsOfLedLeLogoLamp : 18|2@0+ (1,0) [0|3] "" ZCUD
 SG_ StsOfLedLeLogoLamp_UB : 16|1@0+ (1,0) [0|1] "" ZCUD
 SG_ StsOfLedLoBeamLe : 4|2@0+ (1,0) [0|3] "" ZCUD
 SG_ StsOfLedLoBeamLe_UB : 5|1@0+ (1,0) [0|1] "" ZCUD

BO_ 124 HcmlBodyExpoFr04 : 8 HCML
 SG_ DwnLoadStsFbOfHdlampLe : 5|2@0+ (1,0) [0|3] "" ZCUD
 SG_ DwnLoadStsFbOfHdlampLe_UB : 39|1@0+ (1,0) [0|1] "" ZCUD
 SG_ DwnLoadStsFbOfLogoLampLe : 57|2@0+ (1,0) [0|3] "" ZCUD
 SG_ DwnLoadStsFbOfLogoLampLe_UB : 21|1@0+ (1,0) [0|1] "" ZCUD
 SG_ ExtrLiShowActvnFrntLeFb : 28|2@0+ (1,0) [0|3] "" ZCUD
 SG_ ExtrLiShowActvnFrntLeFb_UB : 20|1@0+ (1,0) [0|1] "" ZCUD
 SG_ ExtrLiShowActvnLeLogoFb : 59|2@0+ (1,0) [0|3] "" ZCUD
 SG_ ExtrLiShowActvnLeLogoFb_UB : 22|1@0+ (1,0) [0|1] "" ZCUD
 SG_ HdlampLeInpSts1 : 49|1@0+ (1,0) [0|1] "" ZCUD
 SG_ HdlampLeInpSts1_UB : 48|1@0+ (1,0) [0|1] "" ZCUD
 SG_ HdlampLeInpSts2 : 63|1@0+ (1,0) [0|1] "" ZCUD
 SG_ HdlampLeInpSts2_UB : 62|1@0+ (1,0) [0|1] "" ZCUD
 SG_ StsOfAfsLe : 1|2@0+ (1,0) [0|3] "" ZCUD
 SG_ StsOfAfsLe_UB : 38|1@0+ (1,0) [0|1] "" ZCUD
 SG_ StsOfAhbcLe : 3|2@0+ (1,0) [0|3] "" ZCUD
 SG_ StsOfAhbcLe_UB : 37|1@0+ (1,0) [0|1] "" ZCUD
 SG_ StsOfFrntSideMkrLampLe2 : 9|2@0+ (1,0) [0|3] "" ZCUD
 SG_ StsOfFrntSideMkrLampLe2_UB : 34|1@0+ (1,0) [0|1] "" ZCUD
 SG_ StsOfLedCornrgLampLe : 11|2@0+ (1,0) [0|3] "" ZCUD
 SG_ StsOfLedCornrgLampLe_UB : 33|1@0+ (1,0) [0|1] "" ZCUD
 SG_ StsOfLedDaytiRunngLampLe : 13|2@0+ (1,0) [0|3] "" ZCUD
 SG_ StsOfLedDaytiRunngLampLe_UB : 32|1@0+ (1,0) [0|1] "" ZCUD
 SG_ StsOfLedFrntFogLampLe : 15|2@0+ (1,0) [0|3] "" ZCUD
 SG_ StsOfLedFrntFogLampLe_UB : 31|1@0+ (1,0) [0|1] "" ZCUD
 SG_ StsOfLedFrntPosnLampLe : 17|2@0+ (1,0) [0|3] "" ZCUD
 SG_ StsOfLedFrntPosnLampLe_UB : 30|1@0+ (1,0) [0|1] "" ZCUD
 SG_ StsOfLedFrntTurnIndcrLe : 19|2@0+ (1,0) [0|3] "" ZCUD
 SG_ StsOfLedFrntTurnIndcrLe_UB : 29|1@0+ (1,0) [0|1] "" ZCUD
 SG_ StsOfLvlgLe_UB : 36|1@0+ (1,0) [0|1] "" ZCUD
 SG_ StsOfLvlgLeChks : 47|8@0+ (1.0,0.0) [0.0|255.0] "Unitless" ZCUD
 SG_ StsOfLvlgLeCntr : 55|4@0+ (1.0,0.0) [0.0|15.0] "Unitless" ZCUD
 SG_ StsOfLvlgLeStsOfLvlgLe : 51|2@0+ (1,0) [0|3] "" ZCUD
 SG_ StsOfSwvlgLe : 7|2@0+ (1,0) [0|3] "" ZCUD
 SG_ StsOfSwvlgLe_UB : 35|1@0+ (1,0) [0|1] "" ZCUD
 SG_ StsOfTouristModLe : 25|2@0+ (1,0) [0|3] "" ZCUD
 SG_ StsOfTouristModLe_UB : 26|1@0+ (1,0) [0|1] "" ZCUD
 SG_ StsOfWelGbyFrntLe : 61|1@0+ (1,0) [0|1] "" ZCUD
 SG_ StsOfWelGbyFrntLe_UB : 60|1@0+ (1,0) [0|1] "" ZCUD

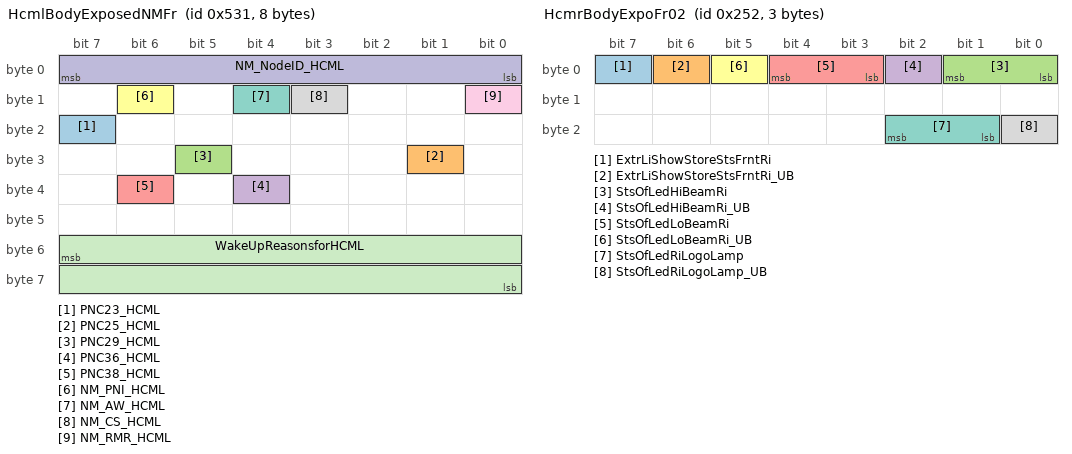
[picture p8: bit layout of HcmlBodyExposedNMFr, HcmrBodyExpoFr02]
BO_ 1329 HcmlBodyExposedNMFr : 8 HCML
 SG_ PNC23_HCML : 23|1@0+ (1,0) [0|0] "" Vector__XXX
 SG_ PNC25_HCML : 25|1@0+ (1,0) [0|0] "" Vector__XXX
 SG_ PNC29_HCML : 29|1@0+ (1,0) [0|0] "" Vector__XXX
 SG_ PNC36_HCML : 36|1@0+ (1,0) [0|0] "" Vector__XXX
 SG_ PNC38_HCML : 38|1@0+ (1,0) [0|0] "" Vector__XXX
 SG_ NM_PNI_HCML : 14|1@0+ (1,0) [0|0] "" Vector__XXX
 SG_ NM_AW_HCML : 12|1@0+ (1,0) [0|0] "" Vector__XXX
 SG_ NM_CS_HCML : 11|1@0+ (1,0) [0|0] "" Vector__XXX
 SG_ NM_RMR_HCML : 8|1@0+ (1,0) [0|0] "" Vector__XXX
 SG_ NM_NodeID_HCML : 7|8@0+ (1,0) [0|0] "" Vector__XXX

 SG_ WakeUpReasonsforHCML : 55|16@0+ (1,0) [0|65535] "" Vector__XXX

BO_ 1424 HcmltoEtcXCPFr01 : 8 HCML

BO_ 1715 HcmlToZcudBodyCanExposedDiagResFrame : 8 HCML

BO_ 594 HcmrBodyExpoFr02 : 3 HCMR
 SG_ ExtrLiShowStoreStsFrntRi : 7|1@0+ (1,0) [0|1] "" ZCUD
 SG_ ExtrLiShowStoreStsFrntRi_UB : 6|1@0+ (1,0) [0|1] "" ZCUD
 SG_ StsOfLedHiBeamRi : 1|2@0+ (1,0) [0|3] "" ZCUD
 SG_ StsOfLedHiBeamRi_UB : 2|1@0+ (1,0) [0|1] "" ZCUD
 SG_ StsOfLedLoBeamRi : 4|2@0+ (1,0) [0|3] "" ZCUD
 SG_ StsOfLedLoBeamRi_UB : 5|1@0+ (1,0) [0|1] "" ZCUD
 SG_ StsOfLedRiLogoLamp : 18|2@0+ (1,0) [0|3] "" ZCUD
 SG_ StsOfLedRiLogoLamp_UB : 16|1@0+ (1,0) [0|1] "" ZCUD

BO_ 127 HcmrBodyExpoFr04 : 8 HCMR
 SG_ DwnLoadStsFbOfHdlampRi : 5|2@0+ (1,0) [0|3] "" ZCUD
 SG_ DwnLoadStsFbOfHdlampRi_UB : 39|1@0+ (1,0) [0|1] "" ZCUD
 SG_ DwnLoadStsFbOfLogoLampRi : 57|2@0+ (1,0) [0|3] "" ZCUD
 SG_ DwnLoadStsFbOfLogoLampRi_UB : 21|1@0+ (1,0) [0|1] "" ZCUD
 SG_ ExtrLiShowActvnFrntRiFb : 28|2@0+ (1,0) [0|3] "" ZCUD
 SG_ ExtrLiShowActvnFrntRiFb_UB : 20|1@0+ (1,0) [0|1] "" ZCUD
 SG_ ExtrLiShowActvnRiLogoFb : 59|2@0+ (1,0) [0|3] "" ZCUD
 SG_ ExtrLiShowActvnRiLogoFb_UB : 22|1@0+ (1,0) [0|1] "" ZCUD
 SG_ HdlampRiInpSts1 : 49|1@0+ (1,0) [0|1] "" ZCUD
 SG_ HdlampRiInpSts1_UB : 48|1@0+ (1,0) [0|1] "" ZCUD
 SG_ HdlampRiInpSts2 : 63|1@0+ (1,0) [0|1] "" ZCUD
 SG_ HdlampRiInpSts2_UB : 62|1@0+ (1,0) [0|1] "" ZCUD
 SG_ StsOfAfsRi : 1|2@0+ (1,0) [0|3] "" ZCUD
 SG_ StsOfAfsRi_UB : 38|1@0+ (1,0) [0|1] "" ZCUD
 SG_ StsOfAhbcRi : 3|2@0+ (1,0) [0|3] "" ZCUD
 SG_ StsOfAhbcRi_UB : 37|1@0+ (1,0) [0|1] "" ZCUD
 SG_ StsOfFrntSideMkrLampRi2 : 9|2@0+ (1,0) [0|3] "" ZCUD
 SG_ StsOfFrntSideMkrLampRi2_UB : 34|1@0+ (1,0) [0|1] "" ZCUD
 SG_ StsOfLedCornrgLampRi : 11|2@0+ (1,0) [0|3] "" ZCUD
 SG_ StsOfLedCornrgLampRi_UB : 33|1@0+ (1,0) [0|1] "" ZCUD
 SG_ StsOfLedDaytiRunngLampRi : 13|2@0+ (1,0) [0|3] "" ZCUD
 SG_ StsOfLedDaytiRunngLampRi_UB : 32|1@0+ (1,0) [0|1] "" ZCUD
 SG_ StsOfLedFrntFogLampRi : 15|2@0+ (1,0) [0|3] "" ZCUD
 SG_ StsOfLedFrntFogLampRi_UB : 31|1@0+ (1,0) [0|1] "" ZCUD
 SG_ StsOfLedFrntPosnLampRi : 17|2@0+ (1,0) [0|3] "" ZCUD
 SG_ StsOfLedFrntPosnLampRi_UB : 30|1@0+ (1,0) [0|1] "" ZCUD
 SG_ StsOfLedFrntTurnIndcrRi : 19|2@0+ (1,0) [0|3] "" ZCUD
 SG_ StsOfLedFrntTurnIndcrRi_UB : 29|1@0+ (1,0) [0|1] "" ZCUD
 SG_ StsOfLvlgRi_UB : 36|1@0+ (1,0) [0|1] "" ZCUD
 SG_ StsOfLvlgRiChks : 47|8@0+ (1.0,0.0) [0.0|255.0] "Unitless" ZCUD
 SG_ StsOfLvlgRiCntr : 55|4@0+ (1.0,0.0) [0.0|15.0] "Unitless" ZCUD
 SG_ StsOfLvlgRiStsOfLvlgRi : 51|2@0+ (1,0) [0|3] "" ZCUD
 SG_ StsOfSwvlgRi : 7|2@0+ (1,0) [0|3] "" ZCUD
 SG_ StsOfSwvlgRi_UB : 35|1@0+ (1,0) [0|1] "" ZCUD
 SG_ StsOfTouristModRi : 25|2@0+ (1,0) [0|3] "" ZCUD
 SG_ StsOfTouristModRi_UB : 26|1@0+ (1,0) [0|1] "" ZCUD
 SG_ StsOfWelGbyFrntRi : 61|1@0+ (1,0) [0|1] "" ZCUD
 SG_ StsOfWelGbyFrntRi_UB : 60|1@0+ (1,0) [0|1] "" ZCUD

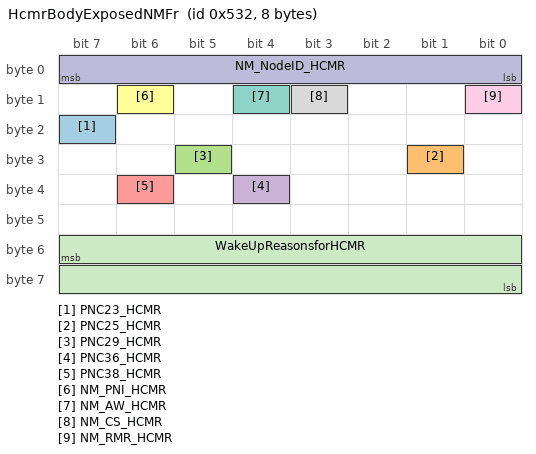
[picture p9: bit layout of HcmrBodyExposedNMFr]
BO_ 1330 HcmrBodyExposedNMFr : 8 HCMR
 SG_ PNC23_HCMR : 23|1@0+ (1,0) [0|0] "" Vector__XXX
 SG_ PNC25_HCMR : 25|1@0+ (1,0) [0|0] "" Vector__XXX
 SG_ PNC29_HCMR : 29|1@0+ (1,0) [0|0] "" Vector__XXX
 SG_ PNC36_HCMR : 36|1@0+ (1,0) [0|0] "" Vector__XXX
 SG_ PNC38_HCMR : 38|1@0+ (1,0) [0|0] "" Vector__XXX
 SG_ NM_PNI_HCMR : 14|1@0+ (1,0) [0|0] "" Vector__XXX
 SG_ NM_AW_HCMR : 12|1@0+ (1,0) [0|0] "" Vector__XXX
 SG_ NM_CS_HCMR : 11|1@0+ (1,0) [0|0] "" Vector__XXX
 SG_ NM_RMR_HCMR : 8|1@0+ (1,0) [0|0] "" Vector__XXX
 SG_ NM_NodeID_HCMR : 7|8@0+ (1,0) [0|0] "" Vector__XXX

 SG_ WakeUpReasonsforHCMR : 55|16@0+ (1,0) [0|65535] "" Vector__XXX

BO_ 1426 HcmrtoEtcXCPFr01 : 8 HCMR

BO_ 1716 HcmrToZcudBodyCanExposedDiagResFrame : 8 HCMR

BO_ 1346 ZCUDBodyExpoCANVFCVectorFr : 8 ZCUD
 SG_ VFCVectorZCUDMBlockID : 1|2@0+ (1.0,0.0) [0.0|3.0] "Unitless" Vector__XXX
 SG_ VFCVectorZCUDMVFCid0 : 2|1@0+ (1,0) [0|1] "" Vector__XXX
 SG_ VFCVectorZCUDMVFCid1 : 3|1@0+ (1,0) [0|1] "" Vector__XXX
 SG_ VFCVectorZCUDMVFCid10 : 12|1@0+ (1,0) [0|1] "" Vector__XXX
 SG_ VFCVectorZCUDMVFCid11 : 13|1@0+ (1,0) [0|1] "" Vector__XXX
 SG_ VFCVectorZCUDMVFCid12 : 14|1@0+ (1,0) [0|1] "" Vector__XXX
 SG_ VFCVectorZCUDMVFCid13 : 15|1@0+ (1,0) [0|1] "" Vector__XXX
 SG_ VFCVectorZCUDMVFCid14 : 16|1@0+ (1,0) [0|1] "" Vector__XXX
 SG_ VFCVectorZCUDMVFCid15 : 17|1@0+ (1,0) [0|1] "" Vector__XXX
 SG_ VFCVectorZCUDMVFCid16 : 18|1@0+ (1,0) [0|1] "" Vector__XXX
 SG_ VFCVectorZCUDMVFCid17 : 19|1@0+ (1,0) [0|1] "" Vector__XXX
 SG_ VFCVectorZCUDMVFCid18 : 20|1@0+ (1,0) [0|1] "" Vector__XXX
 SG_ VFCVectorZCUDMVFCid19 : 21|1@0+ (1,0) [0|1] "" Vector__XXX
 SG_ VFCVectorZCUDMVFCid2 : 4|1@0+ (1,0) [0|1] "" Vector__XXX
 SG_ VFCVectorZCUDMVFCid20 : 22|1@0+ (1,0) [0|1] "" Vector__XXX
 SG_ VFCVectorZCUDMVFCid21 : 23|1@0+ (1,0) [0|1] "" Vector__XXX
 SG_ VFCVectorZCUDMVFCid22 : 24|1@0+ (1,0) [0|1] "" Vector__XXX
 SG_ VFCVectorZCUDMVFCid23 : 25|1@0+ (1,0) [0|1] "" Vector__XXX
 SG_ VFCVectorZCUDMVFCid24 : 26|1@0+ (1,0) [0|1] "" Vector__XXX
 SG_ VFCVectorZCUDMVFCid25 : 27|1@0+ (1,0) [0|1] "" Vector__XXX
 SG_ VFCVectorZCUDMVFCid26 : 28|1@0+ (1,0) [0|1] "" Vector__XXX
 SG_ VFCVectorZCUDMVFCid27 : 29|1@0+ (1,0) [0|1] "" Vector__XXX
 SG_ VFCVectorZCUDMVFCid28 : 30|1@0+ (1,0) [0|1] "" Vector__XXX
 SG_ VFCVectorZCUDMVFCid29 : 31|1@0+ (1,0) [0|1] "" Vector__XXX
 SG_ VFCVectorZCUDMVFCid3 : 5|1@0+ (1,0) [0|1] "" Vector__XXX
 SG_ VFCVectorZCUDMVFCid30 : 32|1@0+ (1,0) [0|1] "" Vector__XXX
 SG_ VFCVectorZCUDMVFCid31 : 33|1@0+ (1,0) [0|1] "" Vector__XXX
 SG_ VFCVectorZCUDMVFCid32 : 34|1@0+ (1,0) [0|1] "" Vector__XXX
 SG_ VFCVectorZCUDMVFCid33 : 35|1@0+ (1,0) [0|1] "" Vector__XXX
 SG_ VFCVectorZCUDMVFCid34 : 36|1@0+ (1,0) [0|1] "" Vector__XXX
 SG_ VFCVectorZCUDMVFCid35 : 37|1@0+ (1,0) [0|1] "" Vector__XXX
 SG_ VFCVectorZCUDMVFCid36 : 38|1@0+ (1,0) [0|1] "" Vector__XXX
 SG_ VFCVectorZCUDMVFCid37 : 39|1@0+ (1,0) [0|1] "" Vector__XXX
 SG_ VFCVectorZCUDMVFCid38 : 40|1@0+ (1,0) [0|1] "" Vector__XXX
 SG_ VFCVectorZCUDMVFCid39 : 41|1@0+ (1,0) [0|1] "" Vector__XXX
 SG_ VFCVectorZCUDMVFCid4 : 6|1@0+ (1,0) [0|1] "" Vector__XXX
 SG_ VFCVectorZCUDMVFCid40 : 42|1@0+ (1,0) [0|1] "" Vector__XXX
 SG_ VFCVectorZCUDMVFCid41 : 43|1@0+ (1,0) [0|1] "" Vector__XXX
 SG_ VFCVectorZCUDMVFCid42 : 44|1@0+ (1,0) [0|1] "" Vector__XXX
 SG_ VFCVectorZCUDMVFCid43 : 45|1@0+ (1,0) [0|1] "" Vector__XXX
 SG_ VFCVectorZCUDMVFCid44 : 46|1@0+ (1,0) [0|1] "" Vector__XXX
 SG_ VFCVectorZCUDMVFCid45 : 47|1@0+ (1,0) [0|1] "" Vector__XXX
 SG_ VFCVectorZCUDMVFCid46 : 48|1@0+ (1,0) [0|1] "" Vector__XXX
 SG_ VFCVectorZCUDMVFCid47 : 49|1@0+ (1,0) [0|1] "" Vector__XXX
 SG_ VFCVectorZCUDMVFCid48 : 50|1@0+ (1,0) [0|1] "" Vector__XXX
 SG_ VFCVectorZCUDMVFCid49 : 51|1@0+ (1,0) [0|1] "" Vector__XXX
 SG_ VFCVectorZCUDMVFCid5 : 7|1@0+ (1,0) [0|1] "" Vector__XXX
 SG_ VFCVectorZCUDMVFCid50 : 52|1@0+ (1,0) [0|1] "" Vector__XXX
 SG_ VFCVectorZCUDMVFCid51 : 53|1@0+ (1,0) [0|1] "" Vector__XXX
 SG_ VFCVectorZCUDMVFCid52 : 54|1@0+ (1,0) [0|1] "" Vector__XXX
 SG_ VFCVectorZCUDMVFCid53 : 55|1@0+ (1,0) [0|1] "" Vector__XXX
 SG_ VFCVectorZCUDMVFCid54 : 56|1@0+ (1,0) [0|1] "" Vector__XXX
 SG_ VFCVectorZCUDMVFCid55 : 57|1@0+ (1,0) [0|1] "" Vector__XXX
 SG_ VFCVectorZCUDMVFCid56 : 58|1@0+ (1,0) [0|1] "" Vector__XXX
 SG_ VFCVectorZCUDMVFCid57 : 59|1@0+ (1,0) [0|1] "" Vector__XXX
 SG_ VFCVectorZCUDMVFCid58 : 60|1@0+ (1,0) [0|1] "" Vector__XXX
 SG_ VFCVectorZCUDMVFCid59 : 61|1@0+ (1,0) [0|1] "" Vector__XXX
 SG_ VFCVectorZCUDMVFCid6 : 8|1@0+ (1,0) [0|1] "" Vector__XXX
 SG_ VFCVectorZCUDMVFCid60 : 62|1@0+ (1,0) [0|1] "" Vector__XXX
 SG_ VFCVectorZCUDMVFCid61 : 63|1@0+ (1,0) [0|1] "" Vector__XXX
 SG_ VFCVectorZCUDMVFCid7 : 9|1@0+ (1,0) [0|1] "" Vector__XXX
 SG_ VFCVectorZCUDMVFCid8 : 10|1@0+ (1,0) [0|1] "" Vector__XXX
 SG_ VFCVectorZCUDMVFCid9 : 11|1@0+ (1,0) [0|1] "" Vector__XXX

// Node Comments
CM_ BU_ ETC "External Tester Connector";
CM_ BU_ HCML "Headlamp Control Module Left";
CM_ BU_ HCMR "Headlamp Control Module Right";

// Signal Comments
CM_ SG_ 1119 DwnLoadDynLtgPrmForReGrp1ContinueTime "Light Show Continue Time Parameter 3";
CM_ SG_ 1119 DwnLoadDynLtgPrmForReGrp1HighBrightness "Light Show Upper Brightness Parameter 3";
CM_ SG_ 1119 DwnLoadDynLtgPrmForReGrp1LowBrightness "Light Show Lower Brightness Parameter 3";
CM_ SG_ 1119 DwnLoadDynLtgPrmForReGrp1Mode1 "Light Show Mode Parameter 3";
CM_ SG_ 1119 DwnLoadDynLtgPrmForReGrp1OffsetTime "Light Show Offset Time Parameter 3";
CM_ SG_ 1119 DwnLoadDynLtgPrmForReGrp1Timestamp "Light Show time stamp 3";
CM_ SG_ 1119 DwnLoadDynLtgPrmForReGrp2ContinueTime "Light Show Continue Time Parameter 3";
CM_ SG_ 1119 DwnLoadDynLtgPrmForReGrp2HighBrightness "Light Show Upper Brightness Parameter 3";
CM_ SG_ 1119 DwnLoadDynLtgPrmForReGrp2LowBrightness "Light Show Lower Brightness Parameter 3";
CM_ SG_ 1119 DwnLoadDynLtgPrmForReGrp2Mode1 "Light Show Mode Parameter 3";
CM_ SG_ 1119 DwnLoadDynLtgPrmForReGrp2OffsetTime "Light Show Offset Time Parameter 3";
CM_ SG_ 1119 DwnLoadDynLtgPrmForReGrp2Timestamp "Light Show time stamp 3";
CM_ SG_ 1122 DwnLoadDynLtgPrmForReGrp3ContinueTime "Light Show Continue Time Parameter 3";
CM_ SG_ 1122 DwnLoadDynLtgPrmForReGrp3HighBrightness "Light Show Upper Brightness Parameter 3";
CM_ SG_ 1122 DwnLoadDynLtgPrmForReGrp3LowBrightness "Light Show Lower Brightness Parameter 3";
CM_ SG_ 1122 DwnLoadDynLtgPrmForReGrp3Mode1 "Light Show Mode Parameter 3";
CM_ SG_ 1122 DwnLoadDynLtgPrmForReGrp3OffsetTime "Light Show Offset Time Parameter 3";
CM_ SG_ 1122 DwnLoadDynLtgPrmForReGrp3Timestamp "Light Show time stamp 3";
CM_ SG_ 1122 DwnLoadDynLtgPrmForReGrp4ContinueTime "Light Show Continue Time Parameter 3";
CM_ SG_ 1122 DwnLoadDynLtgPrmForReGrp4HighBrightness "Light Show Upper Brightness Parameter 3";
CM_ SG_ 1122 DwnLoadDynLtgPrmForReGrp4LowBrightness "Light Show Lower Brightness Parameter 3";
CM_ SG_ 1122 DwnLoadDynLtgPrmForReGrp4Mode1 "Light Show Mode Parameter 3";
CM_ SG_ 1122 DwnLoadDynLtgPrmForReGrp4OffsetTime "Light Show Offset Time Parameter 3";
CM_ SG_ 1122 DwnLoadDynLtgPrmForReGrp4Timestamp "Light Show time stamp 3";
CM_ SG_ 1125 DwnLoadDynLtgPrmForReGrp5ContinueTime "Light Show Continue Time Parameter 3";
CM_ SG_ 1125 DwnLoadDynLtgPrmForReGrp5HighBrightness "Light Show Upper Brightness Parameter 3";
CM_ SG_ 1125 DwnLoadDynLtgPrmForReGrp5LowBrightness "Light Show Lower Brightness Parameter 3";
CM_ SG_ 1125 DwnLoadDynLtgPrmForReGrp5Mode1 "Light Show Mode Parameter 3";
CM_ SG_ 1125 DwnLoadDynLtgPrmForReGrp5OffsetTime "Light Show Offset Time Parameter 3 ";
CM_ SG_ 1125 DwnLoadDynLtgPrmForReGrp5Timestamp "Light Show time stamp 3";
CM_ SG_ 1125 DwnLoadDynLtgPrmForReGrp6ContinueTime "Light Show Continue Time Parameter 3";
CM_ SG_ 1125 DwnLoadDynLtgPrmForReGrp6HighBrightness "Light Show Upper Brightness Parameter 3";
CM_ SG_ 1125 DwnLoadDynLtgPrmForReGrp6LowBrightness "Light Show Lower Brightness Parameter 3";
CM_ SG_ 1125 DwnLoadDynLtgPrmForReGrp6Mode1 "Light Show Mode Parameter 3";
CM_ SG_ 1125 DwnLoadDynLtgPrmForReGrp6OffsetTime "Light Show Offset Time Parameter 3";
CM_ SG_ 1125 DwnLoadDynLtgPrmForReGrp6Timestamp "Light Show time stamp 3";
CM_ SG_ 1129 DwnLoadDynLtgPrmForReGrp7ContinueTime "Light Show Continue Time Parameter 3";
CM_ SG_ 1129 DwnLoadDynLtgPrmForReGrp7HighBrightness "Light Show Upper Brightness Parameter 3";
CM_ SG_ 1129 DwnLoadDynLtgPrmForReGrp7LowBrightness "Light Show Lower Brightness Parameter 3";
CM_ SG_ 1129 DwnLoadDynLtgPrmForReGrp7Mode1 "Light Show Mode Parameter 3";
CM_ SG_ 1129 DwnLoadDynLtgPrmForReGrp7OffsetTime "Light Show Offset Time Parameter 3";
CM_ SG_ 1129 DwnLoadDynLtgPrmForReGrp7Timestamp "Light Show time stamp 3";
CM_ SG_ 1129 DwnLoadDynLtgPrmForReGrp8ContinueTime "Light Show Continue Time Parameter 3";
CM_ SG_ 1129 DwnLoadDynLtgPrmForReGrp8HighBrightness "Light Show Upper Brightness Parameter 3";
CM_ SG_ 1129 DwnLoadDynLtgPrmForReGrp8LowBrightness "Light Show Lower Brightness Parameter 3";
CM_ SG_ 1129 DwnLoadDynLtgPrmForReGrp8Mode1 "Light Show Mode Parameter 3";
CM_ SG_ 1129 DwnLoadDynLtgPrmForReGrp8OffsetTime "Light Show Offset Time Parameter 3";
CM_ SG_ 1129 DwnLoadDynLtgPrmForReGrp8Timestamp "Light Show time stamp 3";
CM_ SG_ 1146 DwnLoadDynLtgPrmForReGrp10ContinueTime "Light Show Continue Time Parameter 3";
CM_ SG_ 1146 DwnLoadDynLtgPrmForReGrp10HighBrightness "Light Show Upper Brightness Parameter 3";
CM_ SG_ 1146 DwnLoadDynLtgPrmForReGrp10LowBrightness "Light Show Lower Brightness Parameter 3";
CM_ SG_ 1146 DwnLoadDynLtgPrmForReGrp10Mode1 "Light Show Mode Parameter 3";
CM_ SG_ 1146 DwnLoadDynLtgPrmForReGrp10OffsetTime "Light Show Offset Time Parameter 3";
CM_ SG_ 1146 DwnLoadDynLtgPrmForReGrp10Timestamp "Light Show time stamp 3";
CM_ SG_ 1146 DwnLoadDynLtgPrmForReGrp9ContinueTime "Light Show Continue Time Parameter 3";
CM_ SG_ 1146 DwnLoadDynLtgPrmForReGrp9HighBrightness "Light Show Upper Brightness Parameter 3";
CM_ SG_ 1146 DwnLoadDynLtgPrmForReGrp9LowBrightness "Light Show Lower Brightness Parameter 3";
CM_ SG_ 1146 DwnLoadDynLtgPrmForReGrp9Mode1 "Light Show Mode Parameter 3";
CM_ SG_ 1146 DwnLoadDynLtgPrmForReGrp9OffsetTime "Light Show Offset Time Parameter 3";
CM_ SG_ 1146 DwnLoadDynLtgPrmForReGrp9Timestamp "Light Show time stamp 3";
CM_ SG_ 1151 DwnLoadDynLtgPrmForReGrp11ContinueTime "Light Show Continue Time Parameter 3";
CM_ SG_ 1151 DwnLoadDynLtgPrmForReGrp11HighBrightness "Light Show Upper Brightness Parameter 3";
CM_ SG_ 1151 DwnLoadDynLtgPrmForReGrp11LowBrightness "Light Show Lower Brightness Parameter 3";
CM_ SG_ 1151 DwnLoadDynLtgPrmForReGrp11Mode1 "Light Show Mode Parameter 3";
CM_ SG_ 1151 DwnLoadDynLtgPrmForReGrp11OffsetTime "Light Show Offset Time Parameter 3";
CM_ SG_ 1151 DwnLoadDynLtgPrmForReGrp11Timestamp "Light Show time stamp 3";
CM_ SG_ 1151 DwnLoadDynLtgPrmForReGrp12ContinueTime "Light Show Continue Time Parameter 3";
CM_ SG_ 1151 DwnLoadDynLtgPrmForReGrp12HighBrightness "Light Show Upper Brightness Parameter 3";
CM_ SG_ 1151 DwnLoadDynLtgPrmForReGrp12LowBrightness "Light Show Lower Brightness Parameter 3";
CM_ SG_ 1151 DwnLoadDynLtgPrmForReGrp12Mode1 "Light Show Mode Parameter 3";
CM_ SG_ 1151 DwnLoadDynLtgPrmForReGrp12OffsetTime "Light Show Offset Time Parameter 3";
CM_ SG_ 1151 DwnLoadDynLtgPrmForReGrp12Timestamp "Light Show time stamp 3";
CM_ SG_ 1157 DwnLoadDynLtgPrmForReGrp13ContinueTime "Light Show Continue Time Parameter 3";
CM_ SG_ 1157 DwnLoadDynLtgPrmForReGrp13HighBrightness "Light Show Upper Brightness Parameter 3";
CM_ SG_ 1157 DwnLoadDynLtgPrmForReGrp13LowBrightness "Light Show Lower Brightness Parameter 3";
CM_ SG_ 1157 DwnLoadDynLtgPrmForReGrp13Mode1 "Light Show Mode Parameter 3";
CM_ SG_ 1157 DwnLoadDynLtgPrmForReGrp13OffsetTime "Light Show Offset Time Parameter 3";
CM_ SG_ 1157 DwnLoadDynLtgPrmForReGrp13Timestamp "Light Show time stamp 3";
CM_ SG_ 1157 DwnLoadDynLtgPrmForReGrp14ContinueTime "Light Show Continue Time Parameter 3";
CM_ SG_ 1157 DwnLoadDynLtgPrmForReGrp14HighBrightness "Light Show Upper Brightness Parameter 3";
CM_ SG_ 1157 DwnLoadDynLtgPrmForReGrp14LowBrightness "Light Show Lower Brightness Parameter 3";
CM_ SG_ 1157 DwnLoadDynLtgPrmForReGrp14Mode1 "Light Show Mode Parameter 3";
CM_ SG_ 1157 DwnLoadDynLtgPrmForReGrp14OffsetTime "Light Show Offset Time Parameter 3 ";
CM_ SG_ 1157 DwnLoadDynLtgPrmForReGrp14Timestamp "Light Show time stamp 3";
CM_ SG_ 1165 DwnLoadDynLtgPrmForReGrp15ContinueTime "Light Show Continue Time Parameter 3";
CM_ SG_ 1165 DwnLoadDynLtgPrmForReGrp15HighBrightness "Light Show Upper Brightness Parameter 3";
CM_ SG_ 1165 DwnLoadDynLtgPrmForReGrp15LowBrightness "Light Show Lower Brightness Parameter 3";
CM_ SG_ 1165 DwnLoadDynLtgPrmForReGrp15Mode1 "Light Show Mode Parameter 3";
CM_ SG_ 1165 DwnLoadDynLtgPrmForReGrp15OffsetTime "Light Show Offset Time Parameter 3";
CM_ SG_ 1165 DwnLoadDynLtgPrmForReGrp15Timestamp "Light Show time stamp 3";
CM_ SG_ 1165 DwnLoadDynLtgPrmForReGrp16ContinueTime "Light Show Continue Time Parameter 3";
CM_ SG_ 1165 DwnLoadDynLtgPrmForReGrp16HighBrightness "Light Show Upper Brightness Parameter 3";
CM_ SG_ 1165 DwnLoadDynLtgPrmForReGrp16LowBrightness "Light Show Lower Brightness Parameter 3";
CM_ SG_ 1165 DwnLoadDynLtgPrmForReGrp16Mode1 "Light Show Mode Parameter 3";
CM_ SG_ 1165 DwnLoadDynLtgPrmForReGrp16OffsetTime "Light Show Offset Time Parameter 3";
CM_ SG_ 1165 DwnLoadDynLtgPrmForReGrp16Timestamp "Light Show time stamp 3";
CM_ SG_ 1167 DwnLoadDynLtgPrmForReGrp17ContinueTime "Light Show Continue Time Parameter 3";
CM_ SG_ 1167 DwnLoadDynLtgPrmForReGrp17HighBrightness "Light Show Upper Brightness Parameter 3";
CM_ SG_ 1167 DwnLoadDynLtgPrmForReGrp17LowBrightness "Light Show Lower Brightness Parameter 3";
CM_ SG_ 1167 DwnLoadDynLtgPrmForReGrp17Mode1 "Light Show Mode Parameter 3";
CM_ SG_ 1167 DwnLoadDynLtgPrmForReGrp17OffsetTime "Light Show Offset Time Parameter 3";
CM_ SG_ 1167 DwnLoadDynLtgPrmForReGrp17Timestamp "Light Show time stamp 3";
CM_ SG_ 1167 DwnLoadDynLtgPrmForReGrp18ContinueTime "Light Show Continue Time Parameter 3";
CM_ SG_ 1167 DwnLoadDynLtgPrmForReGrp18HighBrightness "Light Show Upper Brightness Parameter 3";
CM_ SG_ 1167 DwnLoadDynLtgPrmForReGrp18LowBrightness "Light Show Lower Brightness Parameter 3";
CM_ SG_ 1167 DwnLoadDynLtgPrmForReGrp18Mode1 "Light Show Mode Parameter 3";
CM_ SG_ 1167 DwnLoadDynLtgPrmForReGrp18OffsetTime "Light Show Offset Time Parameter 3";
CM_ SG_ 1167 DwnLoadDynLtgPrmForReGrp18Timestamp "Light Show time stamp 3";
CM_ SG_ 1178 DwnLoadDynLtgPrmForReGrp19ContinueTime "Light Show Continue Time Parameter 3";
CM_ SG_ 1178 DwnLoadDynLtgPrmForReGrp19HighBrightness "Light Show Upper Brightness Parameter 3";
CM_ SG_ 1178 DwnLoadDynLtgPrmForReGrp19LowBrightness "Light Show Lower Brightness Parameter 3";
CM_ SG_ 1178 DwnLoadDynLtgPrmForReGrp19Mode1 "Light Show Mode Parameter 3";
CM_ SG_ 1178 DwnLoadDynLtgPrmForReGrp19OffsetTime "Light Show Offset Time Parameter 3";
CM_ SG_ 1178 DwnLoadDynLtgPrmForReGrp19Timestamp "Light Show time stamp 3";
CM_ SG_ 1178 DwnLoadDynLtgPrmForReGrp20ContinueTime "Light Show Continue Time Parameter 3";
CM_ SG_ 1178 DwnLoadDynLtgPrmForReGrp20HighBrightness "Light Show Upper Brightness Parameter 3";
CM_ SG_ 1178 DwnLoadDynLtgPrmForReGrp20LowBrightness "Light Show Lower Brightness Parameter 3";
CM_ SG_ 1178 DwnLoadDynLtgPrmForReGrp20Mode1 "Light Show Mode Parameter 3";
CM_ SG_ 1178 DwnLoadDynLtgPrmForReGrp20OffsetTime "Light Show Offset Time Parameter 3";
CM_ SG_ 1178 DwnLoadDynLtgPrmForReGrp20Timestamp "Light Show time stamp 3";
CM_ SG_ 1183 DwnLoadDynLtgPrmForReGrp21ContinueTime "Light Show Continue Time Parameter 3";
CM_ SG_ 1183 DwnLoadDynLtgPrmForReGrp21HighBrightness "Light Show Upper Brightness Parameter 3";
CM_ SG_ 1183 DwnLoadDynLtgPrmForReGrp21LowBrightness "Light Show Lower Brightness Parameter 3";
CM_ SG_ 1183 DwnLoadDynLtgPrmForReGrp21Mode1 "Light Show Mode Parameter 3";
CM_ SG_ 1183 DwnLoadDynLtgPrmForReGrp21OffsetTime "Light Show Offset Time Parameter 3";
CM_ SG_ 1183 DwnLoadDynLtgPrmForReGrp21Timestamp "Light Show time stamp 3";
CM_ SG_ 1183 DwnLoadDynLtgPrmForReGrp22ContinueTime "Light Show Continue Time Parameter 3";
CM_ SG_ 1183 DwnLoadDynLtgPrmForReGrp22HighBrightness "Light Show Upper Brightness Parameter 3";
CM_ SG_ 1183 DwnLoadDynLtgPrmForReGrp22LowBrightness "Light Show Lower Brightness Parameter 3";
CM_ SG_ 1183 DwnLoadDynLtgPrmForReGrp22Mode1 "Light Show Mode Parameter 3";
CM_ SG_ 1183 DwnLoadDynLtgPrmForReGrp22OffsetTime "Light Show Offset Time Parameter 3";
CM_ SG_ 1183 DwnLoadDynLtgPrmForReGrp22Timestamp "Light Show time stamp 3";
CM_ SG_ 1189 DwnLoadDynLtgPrmForReGrp23ContinueTime "Light Show Continue Time Parameter 3";
CM_ SG_ 1189 DwnLoadDynLtgPrmForReGrp23HighBrightness "Light Show Upper Brightness Parameter 3";
CM_ SG_ 1189 DwnLoadDynLtgPrmForReGrp23LowBrightness "Light Show Lower Brightness Parameter 3";
CM_ SG_ 1189 DwnLoadDynLtgPrmForReGrp23Mode1 "Light Show Mode Parameter 3";
CM_ SG_ 1189 DwnLoadDynLtgPrmForReGrp23OffsetTime "Light Show Offset Time Parameter 3";
CM_ SG_ 1189 DwnLoadDynLtgPrmForReGrp23Timestamp "Light Show time stamp 3";
CM_ SG_ 1189 DwnLoadDynLtgPrmForReGrp24ContinueTime "Light Show Continue Time Parameter 3";
CM_ SG_ 1189 DwnLoadDynLtgPrmForReGrp24HighBrightness "Light Show Upper Brightness Parameter 3";
CM_ SG_ 1189 DwnLoadDynLtgPrmForReGrp24LowBrightness "Light Show Lower Brightness Parameter 3";
CM_ SG_ 1189 DwnLoadDynLtgPrmForReGrp24Mode1 "Light Show Mode Parameter 3";
CM_ SG_ 1189 DwnLoadDynLtgPrmForReGrp24OffsetTime "Light Show Offset Time Parameter 3";
CM_ SG_ 1189 DwnLoadDynLtgPrmForReGrp24Timestamp "Light Show time stamp 3";
CM_ SG_ 1196 DwnLoadDynLtgPrmForReGrp25ContinueTime "Light Show Continue Time Parameter 3";
CM_ SG_ 1196 DwnLoadDynLtgPrmForReGrp25HighBrightness "Light Show Upper Brightness Parameter 3";
CM_ SG_ 1196 DwnLoadDynLtgPrmForReGrp25LowBrightness "Light Show Lower Brightness Parameter 3";
CM_ SG_ 1196 DwnLoadDynLtgPrmForReGrp25Mode1 "Light Show Mode Parameter 3";
CM_ SG_ 1196 DwnLoadDynLtgPrmForReGrp25OffsetTime "Light Show Offset Time Parameter 3";
CM_ SG_ 1196 DwnLoadDynLtgPrmForReGrp25Timestamp "Light Show time stamp 3";
CM_ SG_ 1196 DwnLoadDynLtgPrmForReGrp26ContinueTime "Light Show Continue Time Parameter 3";
CM_ SG_ 1196 DwnLoadDynLtgPrmForReGrp26HighBrightness "Light Show Upper Brightness Parameter 3";
CM_ SG_ 1196 DwnLoadDynLtgPrmForReGrp26LowBrightness "Light Show Lower Brightness Parameter 3";
CM_ SG_ 1196 DwnLoadDynLtgPrmForReGrp26Mode1 "Light Show Mode Parameter 3";
CM_ SG_ 1196 DwnLoadDynLtgPrmForReGrp26OffsetTime "Light Show Offset Time Parameter 3";
CM_ SG_ 1196 DwnLoadDynLtgPrmForReGrp26Timestamp "Light Show time stamp 3";
CM_ SG_ 1199 DwnLoadDynLtgPrmForReGrp27ContinueTime "Light Show Continue Time Parameter 3";
CM_ SG_ 1199 DwnLoadDynLtgPrmForReGrp27HighBrightness "Light Show Upper Brightness Parameter 3";
CM_ SG_ 1199 DwnLoadDynLtgPrmForReGrp27LowBrightness "Light Show Lower Brightness Parameter 3";
CM_ SG_ 1199 DwnLoadDynLtgPrmForReGrp27Mode1 "Light Show Mode Parameter 3";
CM_ SG_ 1199 DwnLoadDynLtgPrmForReGrp27OffsetTime "Light Show Offset Time Parameter 3 ";
CM_ SG_ 1199 DwnLoadDynLtgPrmForReGrp27Timestamp "Light Show time stamp 3";
CM_ SG_ 1199 DwnLoadDynLtgPrmForReGrp28ContinueTime "Light Show Continue Time Parameter 3";
CM_ SG_ 1199 DwnLoadDynLtgPrmForReGrp28HighBrightness "Light Show Upper Brightness Parameter 3";
CM_ SG_ 1199 DwnLoadDynLtgPrmForReGrp28LowBrightness "Light Show Lower Brightness Parameter 3";
CM_ SG_ 1199 DwnLoadDynLtgPrmForReGrp28Mode1 "Light Show Mode Parameter 3";
CM_ SG_ 1199 DwnLoadDynLtgPrmForReGrp28OffsetTime "Light Show Offset Time Parameter 3";
CM_ SG_ 1199 DwnLoadDynLtgPrmForReGrp28Timestamp "Light Show time stamp 3";
CM_ SG_ 1201 DwnLoadDynLtgPrmForReGrp29ContinueTime "Light Show Continue Time Parameter 3";
CM_ SG_ 1201 DwnLoadDynLtgPrmForReGrp29HighBrightness "Light Show Upper Brightness Parameter 3";
CM_ SG_ 1201 DwnLoadDynLtgPrmForReGrp29LowBrightness "Light Show Lower Brightness Parameter 3";
CM_ SG_ 1201 DwnLoadDynLtgPrmForReGrp29Mode1 "Light Show Mode Parameter 3";
CM_ SG_ 1201 DwnLoadDynLtgPrmForReGrp29OffsetTime "Light Show Offset Time Parameter 3";
CM_ SG_ 1201 DwnLoadDynLtgPrmForReGrp29Timestamp "Light Show time stamp 3";
CM_ SG_ 1201 DwnLoadDynLtgPrmForReGrp30ContinueTime "Light Show Continue Time Parameter 3";
CM_ SG_ 1201 DwnLoadDynLtgPrmForReGrp30HighBrightness "Light Show Upper Brightness Parameter 3";
CM_ SG_ 1201 DwnLoadDynLtgPrmForReGrp30LowBrightness "Light Show Lower Brightness Parameter 3";
CM_ SG_ 1201 DwnLoadDynLtgPrmForReGrp30Mode1 "Light Show Mode Parameter 3";
CM_ SG_ 1201 DwnLoadDynLtgPrmForReGrp30OffsetTime "Light Show Offset Time Parameter 3";
CM_ SG_ 1201 DwnLoadDynLtgPrmForReGrp30Timestamp "Light Show time stamp 3";
CM_ SG_ 593 ExtrLiShowStoreStsFrntLe "ExtrLiShowStoreStsFrntLe";
CM_ SG_ 593 StsOfLedHiBeamLe "Status of Led High Beam Left.";
CM_ SG_ 593 StsOfLedLeLogoLamp "Status of Led Left Logo Light Lamp";
CM_ SG_ 593 StsOfLedLoBeamLe "Status of Led Low Beam Left.";
CM_ SG_ 124 DwnLoadStsFbOfHdlampLe "Download of Dynamic light sequence Feedback signal.";
CM_ SG_ 124 DwnLoadStsFbOfLogoLampLe "Download status feedback of Left Logo Light lamp.";
CM_ SG_ 124 ExtrLiShowActvnFrntLeFb "Activation of Exterior Light Show Feedback Frong Left Head Lamp";
CM_ SG_ 124 ExtrLiShowActvnLeLogoFb "Activation of Exterior Light Show Feedback from Left Logo Light Lamp";
CM_ SG_ 124 HdlampLeInpSts1 "Ext. Light relay input driver warning and fault tracing";
CM_ SG_ 124 HdlampLeInpSts2 "Ignition relay input driver warning and fault tracing";
CM_ SG_ 124 StsOfAfsLe "Status of AFS light distribution Left.";
CM_ SG_ 124 StsOfAhbcLe "Status of Auto High Beam Control Left.";
CM_ SG_ 124 StsOfFrntSideMkrLampLe2 "Status of Front Side Marker Lamp Left 2.";
CM_ SG_ 124 StsOfLedCornrgLampLe "Status of Led Cornering Lamp Left.";
CM_ SG_ 124 StsOfLedDaytiRunngLampLe "Status of Led Day Time Running Lamp Left.";
CM_ SG_ 124 StsOfLedFrntFogLampLe "Status of Led Front Fog Light Left.";
CM_ SG_ 124 StsOfLedFrntPosnLampLe "Status of Led Front Position Lamp Left.";
CM_ SG_ 124 StsOfLedFrntTurnIndcrLe "Status of Led Front Turn Indicator Left.";
CM_ SG_ 124 StsOfLvlgLeChks "Status of Head Lamp Leveling Motor Check Sum";
CM_ SG_ 124 StsOfLvlgLeCntr "Status of Head Lamp Leveling Motor Counter";
CM_ SG_ 124 StsOfLvlgLeStsOfLvlgLe "Status of Head Lamp Leveling Motor";
CM_ SG_ 124 StsOfSwvlgLe "Status of Bending Light Left.";
CM_ SG_ 124 StsOfTouristModLe "Status of Tourist Mode Left.";
CM_ SG_ 124 StsOfWelGbyFrntLe "status of welcome and goodbye light from HCML";
CM_ SG_ 1329 WakeUpReasonsforHCML "WakeUpReasons";
CM_ SG_ 594 ExtrLiShowStoreStsFrntRi "ExtrLiShowStoreStsFrntRi";
CM_ SG_ 594 StsOfLedHiBeamRi "Status of High Beam Led Right.";
CM_ SG_ 594 StsOfLedLoBeamRi "Status of Low Beam Led Right";
CM_ SG_ 594 StsOfLedRiLogoLamp "Status of Led Right Logo Light Lamp";
CM_ SG_ 127 DwnLoadStsFbOfHdlampRi "Download of Dynamic light sequence Feedback signal.";
CM_ SG_ 127 DwnLoadStsFbOfLogoLampRi "Download status feedback of Right Logo Light lamp.";
CM_ SG_ 127 ExtrLiShowActvnFrntRiFb "Activation of Exterior Light Show Feedback Frong Right Head Lamp";
CM_ SG_ 127 ExtrLiShowActvnRiLogoFb "Activation of Exterior Light Show Feedback from Right Logo Light Lamp";
CM_ SG_ 127 HdlampRiInpSts1 "Ext. Light relay input driver warning and fault tracing";
CM_ SG_ 127 HdlampRiInpSts2 "Ignition relay input driver warning and fault tracing";
CM_ SG_ 127 StsOfAfsRi "Status of AFS light distribution Right.";
CM_ SG_ 127 StsOfAhbcRi "Status of Auto High Beam Control Right.";
CM_ SG_ 127 StsOfFrntSideMkrLampRi2 "Status of Front Side Marker Lamp Right 2.";
CM_ SG_ 127 StsOfLedCornrgLampRi "Status of Led Cornering Lamp Right.";
CM_ SG_ 127 StsOfLedDaytiRunngLampRi "Status of Led Day Time Running Lamp Right.";
CM_ SG_ 127 StsOfLedFrntFogLampRi "Status of Led Front Fog Lamp Right.";
CM_ SG_ 127 StsOfLedFrntPosnLampRi "Status of Led Front Position Lamp Right.";
CM_ SG_ 127 StsOfLedFrntTurnIndcrRi "Status of Front Turn Right Indicator";
CM_ SG_ 127 StsOfLvlgRiChks "Status of Head Lamp Leveling Motor Check Sum";
CM_ SG_ 127 StsOfLvlgRiCntr "Status of Head Lamp Leveling Motor Counter";
CM_ SG_ 127 StsOfLvlgRiStsOfLvlgRi "Status of Head Lamp Leveling Motor";
CM_ SG_ 127 StsOfSwvlgRi "Status of Bending Light Right.";
CM_ SG_ 127 StsOfTouristModRi "Status of Tourist Mode Right.";
CM_ SG_ 127 StsOfWelGbyFrntRi "status of welcome and goodbye light from HCMR";
CM_ SG_ 1330 WakeUpReasonsforHCMR "WakeUpReasons";
CM_ SG_ 1346 VFCVectorZCUDMBlockID "BlockID";
CM_ SG_ 1346 VFCVectorZCUDMVFCid0 "SettingsComfort";
CM_ SG_ 1346 VFCVectorZCUDMVFCid1 "ParkingDrivingClimatization";
CM_ SG_ 1346 VFCVectorZCUDMVFCid10 "ExteriorLighting";
CM_ SG_ 1346 VFCVectorZCUDMVFCid11 "VFC11";
CM_ SG_ 1346 VFCVectorZCUDMVFCid12 "Alarm";
CM_ SG_ 1346 VFCVectorZCUDMVFCid13 "VFC13";
CM_ SG_ 1346 VFCVectorZCUDMVFCid14 "InteriorLighting";
CM_ SG_ 1346 VFCVectorZCUDMVFCid15 "VFC15";
CM_ SG_ 1346 VFCVectorZCUDMVFCid16 "Locking";
CM_ SG_ 1346 VFCVectorZCUDMVFCid17 "RemoteKeyFunctionality";
CM_ SG_ 1346 VFCVectorZCUDMVFCid18 "PropulsionStart";
CM_ SG_ 1346 VFCVectorZCUDMVFCid19 "VFC19";
CM_ SG_ 1346 VFCVectorZCUDMVFCid2 "PostClimatisation";
CM_ SG_ 1346 VFCVectorZCUDMVFCid20 "VFC20";
CM_ SG_ 1346 VFCVectorZCUDMVFCid21 "PowerClosures";
CM_ SG_ 1346 VFCVectorZCUDMVFCid22 "VehicleDriving";
CM_ SG_ 1346 VFCVectorZCUDMVFCid23 "VFC23";
CM_ SG_ 1346 VFCVectorZCUDMVFCid24 "SettingsProfile";
CM_ SG_ 1346 VFCVectorZCUDMVFCid25 "SeatComfortFunctions";
CM_ SG_ 1346 VFCVectorZCUDMVFCid26 "Brake";
CM_ SG_ 1346 VFCVectorZCUDMVFCid27 "InfotainmentPoll";
CM_ SG_ 1346 VFCVectorZCUDMVFCid28 "HVEnergyStorage";
CM_ SG_ 1346 VFCVectorZCUDMVFCid29 "VFC29";
CM_ SG_ 1346 VFCVectorZCUDMVFCid3 "PowertrainParkingClimatization";
CM_ SG_ 1346 VFCVectorZCUDMVFCid30 "TelematicsConnectivity";
CM_ SG_ 1346 VFCVectorZCUDMVFCid31 "VFC31";
CM_ SG_ 1346 VFCVectorZCUDMVFCid32 "VFC32";
CM_ SG_ 1346 VFCVectorZCUDMVFCid33 "Diagnostics";
CM_ SG_ 1346 VFCVectorZCUDMVFCid34 "VehicleModeManagement";
CM_ SG_ 1346 VFCVectorZCUDMVFCid35 "TrailerCaravanFunctions";
CM_ SG_ 1346 VFCVectorZCUDMVFCid36 "Immobilizer";
CM_ SG_ 1346 VFCVectorZCUDMVFCid37 "Windows";
CM_ SG_ 1346 VFCVectorZCUDMVFCid38 "Visibility";
CM_ SG_ 1346 VFCVectorZCUDMVFCid39 "VFC39";
CM_ SG_ 1346 VFCVectorZCUDMVFCid4 "VFC4";
CM_ SG_ 1346 VFCVectorZCUDMVFCid40 "VFC40";
CM_ SG_ 1346 VFCVectorZCUDMVFCid41 "InfotainmentPush";
CM_ SG_ 1346 VFCVectorZCUDMVFCid42 "ChargingHV";
CM_ SG_ 1346 VFCVectorZCUDMVFCid43 "BodyPreClimatisation";
CM_ SG_ 1346 VFCVectorZCUDMVFCid44 "Crash";
CM_ SG_ 1346 VFCVectorZCUDMVFCid45 "GlobalShortDuration";
CM_ SG_ 1346 VFCVectorZCUDMVFCid46 "ExteriorLightsHazard";
CM_ SG_ 1346 VFCVectorZCUDMVFCid47 "VFC47";
CM_ SG_ 1346 VFCVectorZCUDMVFCid48 "DoorOpenWarning";
CM_ SG_ 1346 VFCVectorZCUDMVFCid49 "ChargingLVInit";
CM_ SG_ 1346 VFCVectorZCUDMVFCid5 "VFC5";
CM_ SG_ 1346 VFCVectorZCUDMVFCid50 "VFC50";
CM_ SG_ 1346 VFCVectorZCUDMVFCid51 "VFC51";
CM_ SG_ 1346 VFCVectorZCUDMVFCid52 "HVBatteryThermalEventWarning";
CM_ SG_ 1346 VFCVectorZCUDMVFCid53 "VisualAssist";
CM_ SG_ 1346 VFCVectorZCUDMVFCid54 "PassiveSafety";
CM_ SG_ 1346 VFCVectorZCUDMVFCid55 "LifeDetection";
CM_ SG_ 1346 VFCVectorZCUDMVFCid56 "BackboneFlexray";
CM_ SG_ 1346 VFCVectorZCUDMVFCid57 "Functionmarket";
CM_ SG_ 1346 VFCVectorZCUDMVFCid58 "VFCid58";
CM_ SG_ 1346 VFCVectorZCUDMVFCid59 "VFCid59";
CM_ SG_ 1346 VFCVectorZCUDMVFCid6 "SettingsVehicle";
CM_ SG_ 1346 VFCVectorZCUDMVFCid60 "VFCid60";
CM_ SG_ 1346 VFCVectorZCUDMVFCid61 "VFCid61";
CM_ SG_ 1346 VFCVectorZCUDMVFCid7 "VFC7";
CM_ SG_ 1346 VFCVectorZCUDMVFCid8 "VFC8";
CM_ SG_ 1346 VFCVectorZCUDMVFCid9 "IPWakeup";

// Attribute definitions
BA_DEF_  "Baudrate" INT 1000 1000000; // [bps]
BA_DEF_  "BusType" STRING;
BA_DEF_  "DBName" STRING;
BA_DEF_  "ProtocolType" STRING;
BA_DEF_ BU_ "NmAsrNode" ENUM "No","Yes";
BA_DEF_ BU_ "NmAsrNodeIdentifier" INT 0 255;
BA_DEF_ BO_ "GenMsgCycleTime" INT 0 65536; // [ms]
BA_DEF_ BO_ "GenMsgDelayTime" INT 0 65536; // [ms]
BA_DEF_ BO_ "GenMsgSendType" ENUM "cyclic", "spontaneous", "not-used", "not-used", "not-used", "cyclicAndSpontaneous", "not-used", "cyclicIfActive", "NoMsgSendType"; // [us]
BA_DEF_ BO_ "GenMsgStartDelayTime" INT 0 65536; // [ms]
BA_DEF_ SG_ "GenSigSendType" ENUM "Cyclic","OnWrite","OnWriteWithRepetition","OnChange","OnChangeWithRepetition","IfActive","IfActiveWithRepetition","NoSigSendType";
BA_DEF_ SG_ "GenSigStartValue" HEX 0 80000000;
BA_DEF_ BO_ "GenMsgILSupport" ENUM "No","Yes";
BA_DEF_ BO_ "NmAsrMessage" ENUM "No","Yes";
BA_DEF_  "NmAsrBaseAddress" HEX 0 536870911;
BA_DEF_  "NmAsrMessageCount" INT 0 255;
BA_DEF_ BU_ "NodeLayerModules" STRING;
BA_DEF_ BU_ "ILused" ENUM "No","Yes";
BA_DEF_ SG_ "GenSigFuncType" ENUM "NoFunction","n/a","n/a","n/a","n/a","n/a","n/a","n/a","n/a","n/a","n/a","n/a","n/a","n/a","n/a","CHK","CNTR","n/a","n/a","n/a","CNTR_AR_01","CRC_AR_01_BOTH","CRC_AR_01_ALT","CRC_AR_01_LOW","CRC_AR_01_NIBBLE","CNTR_AR_04","CRC_AR_04A","CNTR_AR_05","CRC_AR_05";
BA_DEF_ SG_ "GenSigDataID" STRING;

BA_DEF_DEF_ "BusType" "";
BA_DEF_DEF_ "DBName" "";
BA_DEF_DEF_ "ProtocolType" "";
BA_DEF_DEF_ "NmAsrNode" "No";
BA_DEF_DEF_ "NmAsrNodeIdentifier" 0;
BA_DEF_DEF_ "GenSigStartValue" 0;
BA_DEF_DEF_ "GenSigSendType" "NoSigSendType";
BA_DEF_DEF_ "GenMsgCycleTime" 0;
BA_DEF_DEF_ "GenMsgDelayTime" 0;
BA_DEF_DEF_ "GenMsgStartDelayTime" 0;
BA_DEF_DEF_ "GenMsgSendType" "NoMsgSendType";
BA_DEF_DEF_ "GenMsgILSupport" "Yes";
BA_DEF_DEF_ "NmAsrMessage" "No";
BA_DEF_DEF_ "NmAsrBaseAddress" 1280;
BA_DEF_DEF_ "NmAsrMessageCount" 64;
BA_DEF_DEF_ "NodeLayerModules" "CANoeILNLSPA.dll";
BA_DEF_DEF_ "ILused" "Yes";
BA_DEF_DEF_ "GenSigFuncType" "NoFunction";
BA_DEF_DEF_ "GenSigDataID" "";

BA_ "Baudrate" 500000;
BA_ "BusType" "CAN";
BA_ "DBName" "BodyExposedCAN";
BA_ "ProtocolType" "CAN";
// Network
// ECU: ETC
BA_ "ILused" BU_ ETC 0;
// ECU: HCML
BA_ "NmAsrNode" BU_ HCML 1;
BA_ "NmAsrNodeIdentifier" BU_ HCML 49;
BA_ "NodeLayerModules" BU_ HCML "CANoeILNLSPA.dll,AsrNM33.dll";
// ECU: HCMR
BA_ "NmAsrNode" BU_ HCMR 1;
BA_ "NmAsrNodeIdentifier" BU_ HCMR 50;
BA_ "NodeLayerModules" BU_ HCMR "CANoeILNLSPA.dll,AsrNM33.dll";
// ECU: ZCUD
BA_ "NmAsrNode" BU_ ZCUD 1;
BA_ "NmAsrNodeIdentifier" BU_ ZCUD 2;
BA_ "NodeLayerModules" BU_ ZCUD "CANoeILNLSPA.dll,AsrNM33.dll";
// Frame: CemBodyExpoFr123
BA_ "GenMsgDelayTime" BO_ 1119 30.000;
BA_ "GenMsgSendType" BO_ 1119 1;
// Frame: CemBodyExpoFr124
BA_ "GenMsgDelayTime" BO_ 1122 30.000;
BA_ "GenMsgSendType" BO_ 1122 1;
// Frame: CemBodyExpoFr125
BA_ "GenMsgDelayTime" BO_ 1125 30.000;
BA_ "GenMsgSendType" BO_ 1125 1;
// Frame: CemBodyExpoFr126
BA_ "GenMsgDelayTime" BO_ 1129 30.000;
BA_ "GenMsgSendType" BO_ 1129 1;
// Frame: CemBodyExpoFr127
BA_ "GenMsgDelayTime" BO_ 1146 30.000;
BA_ "GenMsgSendType" BO_ 1146 1;
// Frame: CemBodyExpoFr128
BA_ "GenMsgDelayTime" BO_ 1151 30.000;
BA_ "GenMsgSendType" BO_ 1151 1;
// Frame: CemBodyExpoFr129
BA_ "GenMsgDelayTime" BO_ 1157 30.000;
BA_ "GenMsgSendType" BO_ 1157 1;
// Frame: CemBodyExpoFr130
BA_ "GenMsgDelayTime" BO_ 1165 30.000;
BA_ "GenMsgSendType" BO_ 1165 1;
// Frame: CemBodyExpoFr131
BA_ "GenMsgDelayTime" BO_ 1167 30.000;
BA_ "GenMsgSendType" BO_ 1167 1;
// Frame: CemBodyExpoFr132
BA_ "GenMsgDelayTime" BO_ 1178 30.000;
BA_ "GenMsgSendType" BO_ 1178 1;
// Frame: CemBodyExpoFr133
BA_ "GenMsgDelayTime" BO_ 1183 30.000;
BA_ "GenMsgSendType" BO_ 1183 1;
// Frame: CemBodyExpoFr134
BA_ "GenMsgDelayTime" BO_ 1189 30.000;
BA_ "GenMsgSendType" BO_ 1189 1;
// Frame: CemBodyExpoFr135
BA_ "GenMsgDelayTime" BO_ 1196 30.000;
BA_ "GenMsgSendType" BO_ 1196 1;
// Frame: CemBodyExpoFr136
BA_ "GenMsgDelayTime" BO_ 1199 30.000;
BA_ "GenMsgSendType" BO_ 1199 1;
// Frame: CemBodyExpoFr137
BA_ "GenMsgDelayTime" BO_ 1201 30.000;
BA_ "GenMsgSendType" BO_ 1201 1;
// Frame: CemToDpod2BodyCanExposedDiagReqFrame
BA_ "GenMsgDelayTime" BO_ 1969 5.000;
BA_ "GenMsgSendType" BO_ 1969 1;
// Frame: CemToLpod2BodyCanExposedDiagReqFrame
BA_ "GenMsgDelayTime" BO_ 1968 5.000;
BA_ "GenMsgSendType" BO_ 1968 1;
// Frame: CemToPpod2BodyCanExposedDiagReqFrame
BA_ "GenMsgDelayTime" BO_ 1980 5.000;
BA_ "GenMsgSendType" BO_ 1980 1;
// Frame: CemToRpod2BodyCanExposedDiagReqFrame
BA_ "GenMsgDelayTime" BO_ 1979 5.000;
BA_ "GenMsgSendType" BO_ 1979 1;
// Frame: EtctoHcmlXCPFr01
BA_ "GenMsgDelayTime" BO_ 1430 10.000;
BA_ "GenMsgSendType" BO_ 1430 1;
// Frame: EtctoHcmrXCPFr01
BA_ "GenMsgDelayTime" BO_ 1428 10.000;
BA_ "GenMsgSendType" BO_ 1428 1;
// Frame: HcmlBodyExpoFr02
BA_ "GenMsgCycleTime" BO_ 593 50.000;
BA_ "GenMsgSendType" BO_ 593 0;
// Frame: HcmlBodyExpoFr04
BA_ "GenMsgCycleTime" BO_ 124 50.000;
BA_ "GenMsgSendType" BO_ 124 0;
// Frame: HcmlBodyExposedNMFr
BA_ "GenMsgDelayTime" BO_ 1329 20.000;
BA_ "GenMsgSendType" BO_ 1329 1;
// Frame: HcmlToZcudBodyCanExposedDiagResFrame
BA_ "GenMsgDelayTime" BO_ 1715 5.000;
BA_ "GenMsgSendType" BO_ 1715 1;
// Frame: HcmltoEtcXCPFr01
BA_ "GenMsgDelayTime" BO_ 1424 10.000;
BA_ "GenMsgSendType" BO_ 1424 1;
// Frame: HcmrBodyExpoFr02
BA_ "GenMsgCycleTime" BO_ 594 50.000;
BA_ "GenMsgSendType" BO_ 594 0;
// Frame: HcmrBodyExpoFr04
BA_ "GenMsgCycleTime" BO_ 127 50.000;
BA_ "GenMsgSendType" BO_ 127 0;
// Frame: HcmrBodyExposedNMFr
BA_ "GenMsgDelayTime" BO_ 1330 20.000;
BA_ "GenMsgSendType" BO_ 1330 1;
// Frame: HcmrToZcudBodyCanExposedDiagResFrame
BA_ "GenMsgDelayTime" BO_ 1716 5.000;
BA_ "GenMsgSendType" BO_ 1716 1;
// Frame: HcmrtoEtcXCPFr01
BA_ "GenMsgDelayTime" BO_ 1426 10.000;
BA_ "GenMsgSendType" BO_ 1426 1;
// Frame: ZCUDBodyExpoCANVFCVectorFr
BA_ "GenMsgCycleTime" BO_ 1346 500.000;
BA_ "GenMsgSendType" BO_ 1346 0;
BA_ "GenMsgILSupport" BO_ 1329 0;
BA_ "GenMsgILSupport" BO_ 1330 0;
BA_ "NmAsrMessage" BO_ 1329 1;
BA_ "NmAsrMessage" BO_ 1330 1;
BA_ "GenSigSendType" SG_ 1146 DwnLoadDynLtgPrmForReGrp10ContinueTime 1;
BA_ "GenSigSendType" SG_ 1146 DwnLoadDynLtgPrmForReGrp10HighBrightness 1;
BA_ "GenSigSendType" SG_ 1146 DwnLoadDynLtgPrmForReGrp10LowBrightness 1;
BA_ "GenSigSendType" SG_ 1146 DwnLoadDynLtgPrmForReGrp10Mode1 1;
BA_ "GenSigSendType" SG_ 1146 DwnLoadDynLtgPrmForReGrp10OffsetTime 1;
BA_ "GenSigSendType" SG_ 1146 DwnLoadDynLtgPrmForReGrp10Timestamp 1;
BA_ "GenSigSendType" SG_ 1151 DwnLoadDynLtgPrmForReGrp11ContinueTime 1;
BA_ "GenSigSendType" SG_ 1151 DwnLoadDynLtgPrmForReGrp11HighBrightness 1;
BA_ "GenSigSendType" SG_ 1151 DwnLoadDynLtgPrmForReGrp11LowBrightness 1;
BA_ "GenSigSendType" SG_ 1151 DwnLoadDynLtgPrmForReGrp11Mode1 1;
BA_ "GenSigSendType" SG_ 1151 DwnLoadDynLtgPrmForReGrp11OffsetTime 1;
BA_ "GenSigSendType" SG_ 1151 DwnLoadDynLtgPrmForReGrp11Timestamp 1;
BA_ "GenSigSendType" SG_ 1151 DwnLoadDynLtgPrmForReGrp12ContinueTime 1;
BA_ "GenSigSendType" SG_ 1151 DwnLoadDynLtgPrmForReGrp12HighBrightness 1;
BA_ "GenSigSendType" SG_ 1151 DwnLoadDynLtgPrmForReGrp12LowBrightness 1;
BA_ "GenSigSendType" SG_ 1151 DwnLoadDynLtgPrmForReGrp12Mode1 1;
BA_ "GenSigSendType" SG_ 1151 DwnLoadDynLtgPrmForReGrp12OffsetTime 1;
BA_ "GenSigSendType" SG_ 1151 DwnLoadDynLtgPrmForReGrp12Timestamp 1;
BA_ "GenSigSendType" SG_ 1157 DwnLoadDynLtgPrmForReGrp13ContinueTime 1;
BA_ "GenSigSendType" SG_ 1157 DwnLoadDynLtgPrmForReGrp13HighBrightness 1;
BA_ "GenSigSendType" SG_ 1157 DwnLoadDynLtgPrmForReGrp13LowBrightness 1;
BA_ "GenSigSendType" SG_ 1157 DwnLoadDynLtgPrmForReGrp13Mode1 1;
BA_ "GenSigSendType" SG_ 1157 DwnLoadDynLtgPrmForReGrp13OffsetTime 1;
BA_ "GenSigSendType" SG_ 1157 DwnLoadDynLtgPrmForReGrp13Timestamp 1;
BA_ "GenSigSendType" SG_ 1157 DwnLoadDynLtgPrmForReGrp14ContinueTime 1;
BA_ "GenSigSendType" SG_ 1157 DwnLoadDynLtgPrmForReGrp14HighBrightness 1;
BA_ "GenSigSendType" SG_ 1157 DwnLoadDynLtgPrmForReGrp14LowBrightness 1;
BA_ "GenSigSendType" SG_ 1157 DwnLoadDynLtgPrmForReGrp14Mode1 1;
BA_ "GenSigSendType" SG_ 1157 DwnLoadDynLtgPrmForReGrp14OffsetTime 1;
BA_ "GenSigSendType" SG_ 1157 DwnLoadDynLtgPrmForReGrp14Timestamp 1;
BA_ "GenSigSendType" SG_ 1165 DwnLoadDynLtgPrmForReGrp15ContinueTime 1;
BA_ "GenSigSendType" SG_ 1165 DwnLoadDynLtgPrmForReGrp15HighBrightness 1;
BA_ "GenSigSendType" SG_ 1165 DwnLoadDynLtgPrmForReGrp15LowBrightness 1;
BA_ "GenSigSendType" SG_ 1165 DwnLoadDynLtgPrmForReGrp15Mode1 1;
BA_ "GenSigSendType" SG_ 1165 DwnLoadDynLtgPrmForReGrp15OffsetTime 1;
BA_ "GenSigSendType" SG_ 1165 DwnLoadDynLtgPrmForReGrp15Timestamp 1;
BA_ "GenSigSendType" SG_ 1165 DwnLoadDynLtgPrmForReGrp16ContinueTime 1;
BA_ "GenSigSendType" SG_ 1165 DwnLoadDynLtgPrmForReGrp16HighBrightness 1;
BA_ "GenSigSendType" SG_ 1165 DwnLoadDynLtgPrmForReGrp16LowBrightness 1;
BA_ "GenSigSendType" SG_ 1165 DwnLoadDynLtgPrmForReGrp16Mode1 1;
BA_ "GenSigSendType" SG_ 1165 DwnLoadDynLtgPrmForReGrp16OffsetTime 1;
BA_ "GenSigSendType" SG_ 1165 DwnLoadDynLtgPrmForReGrp16Timestamp 1;
BA_ "GenSigSendType" SG_ 1167 DwnLoadDynLtgPrmForReGrp17ContinueTime 1;
BA_ "GenSigSendType" SG_ 1167 DwnLoadDynLtgPrmForReGrp17HighBrightness 1;
BA_ "GenSigSendType" SG_ 1167 DwnLoadDynLtgPrmForReGrp17LowBrightness 1;
BA_ "GenSigSendType" SG_ 1167 DwnLoadDynLtgPrmForReGrp17Mode1 1;
BA_ "GenSigSendType" SG_ 1167 DwnLoadDynLtgPrmForReGrp17OffsetTime 1;
BA_ "GenSigSendType" SG_ 1167 DwnLoadDynLtgPrmForReGrp17Timestamp 1;
BA_ "GenSigSendType" SG_ 1167 DwnLoadDynLtgPrmForReGrp18ContinueTime 1;
BA_ "GenSigSendType" SG_ 1167 DwnLoadDynLtgPrmForReGrp18HighBrightness 1;
BA_ "GenSigSendType" SG_ 1167 DwnLoadDynLtgPrmForReGrp18LowBrightness 1;
BA_ "GenSigSendType" SG_ 1167 DwnLoadDynLtgPrmForReGrp18Mode1 1;
BA_ "GenSigSendType" SG_ 1167 DwnLoadDynLtgPrmForReGrp18OffsetTime 1;
BA_ "GenSigSendType" SG_ 1167 DwnLoadDynLtgPrmForReGrp18Timestamp 1;
BA_ "GenSigSendType" SG_ 1178 DwnLoadDynLtgPrmForReGrp19ContinueTime 1;
BA_ "GenSigSendType" SG_ 1178 DwnLoadDynLtgPrmForReGrp19HighBrightness 1;
BA_ "GenSigSendType" SG_ 1178 DwnLoadDynLtgPrmForReGrp19LowBrightness 1;
BA_ "GenSigSendType" SG_ 1178 DwnLoadDynLtgPrmForReGrp19Mode1 1;
BA_ "GenSigSendType" SG_ 1178 DwnLoadDynLtgPrmForReGrp19OffsetTime 1;
BA_ "GenSigSendType" SG_ 1178 DwnLoadDynLtgPrmForReGrp19Timestamp 1;
BA_ "GenSigSendType" SG_ 1119 DwnLoadDynLtgPrmForReGrp1ContinueTime 1;
BA_ "GenSigSendType" SG_ 1119 DwnLoadDynLtgPrmForReGrp1HighBrightness 1;
BA_ "GenSigSendType" SG_ 1119 DwnLoadDynLtgPrmForReGrp1LowBrightness 1;
BA_ "GenSigSendType" SG_ 1119 DwnLoadDynLtgPrmForReGrp1Mode1 1;
BA_ "GenSigSendType" SG_ 1119 DwnLoadDynLtgPrmForReGrp1OffsetTime 1;
BA_ "GenSigSendType" SG_ 1119 DwnLoadDynLtgPrmForReGrp1Timestamp 1;
BA_ "GenSigSendType" SG_ 1178 DwnLoadDynLtgPrmForReGrp20ContinueTime 1;
BA_ "GenSigSendType" SG_ 1178 DwnLoadDynLtgPrmForReGrp20HighBrightness 1;
BA_ "GenSigSendType" SG_ 1178 DwnLoadDynLtgPrmForReGrp20LowBrightness 1;
BA_ "GenSigSendType" SG_ 1178 DwnLoadDynLtgPrmForReGrp20Mode1 1;
BA_ "GenSigSendType" SG_ 1178 DwnLoadDynLtgPrmForReGrp20OffsetTime 1;
BA_ "GenSigSendType" SG_ 1178 DwnLoadDynLtgPrmForReGrp20Timestamp 1;
BA_ "GenSigSendType" SG_ 1183 DwnLoadDynLtgPrmForReGrp21ContinueTime 1;
BA_ "GenSigSendType" SG_ 1183 DwnLoadDynLtgPrmForReGrp21HighBrightness 1;
BA_ "GenSigSendType" SG_ 1183 DwnLoadDynLtgPrmForReGrp21LowBrightness 1;
BA_ "GenSigSendType" SG_ 1183 DwnLoadDynLtgPrmForReGrp21Mode1 1;
BA_ "GenSigSendType" SG_ 1183 DwnLoadDynLtgPrmForReGrp21OffsetTime 1;
BA_ "GenSigSendType" SG_ 1183 DwnLoadDynLtgPrmForReGrp21Timestamp 1;
BA_ "GenSigSendType" SG_ 1183 DwnLoadDynLtgPrmForReGrp22ContinueTime 1;
BA_ "GenSigSendType" SG_ 1183 DwnLoadDynLtgPrmForReGrp22HighBrightness 1;
BA_ "GenSigSendType" SG_ 1183 DwnLoadDynLtgPrmForReGrp22LowBrightness 1;
BA_ "GenSigSendType" SG_ 1183 DwnLoadDynLtgPrmForReGrp22Mode1 1;
BA_ "GenSigSendType" SG_ 1183 DwnLoadDynLtgPrmForReGrp22OffsetTime 1;
BA_ "GenSigSendType" SG_ 1183 DwnLoadDynLtgPrmForReGrp22Timestamp 1;
BA_ "GenSigSendType" SG_ 1189 DwnLoadDynLtgPrmForReGrp23ContinueTime 1;
BA_ "GenSigSendType" SG_ 1189 DwnLoadDynLtgPrmForReGrp23HighBrightness 1;
BA_ "GenSigSendType" SG_ 1189 DwnLoadDynLtgPrmForReGrp23LowBrightness 1;
BA_ "GenSigSendType" SG_ 1189 DwnLoadDynLtgPrmForReGrp23Mode1 1;
BA_ "GenSigSendType" SG_ 1189 DwnLoadDynLtgPrmForReGrp23OffsetTime 1;
BA_ "GenSigSendType" SG_ 1189 DwnLoadDynLtgPrmForReGrp23Timestamp 1;
BA_ "GenSigSendType" SG_ 1189 DwnLoadDynLtgPrmForReGrp24ContinueTime 1;
BA_ "GenSigSendType" SG_ 1189 DwnLoadDynLtgPrmForReGrp24HighBrightness 1;
BA_ "GenSigSendType" SG_ 1189 DwnLoadDynLtgPrmForReGrp24LowBrightness 1;
BA_ "GenSigSendType" SG_ 1189 DwnLoadDynLtgPrmForReGrp24Mode1 1;
BA_ "GenSigSendType" SG_ 1189 DwnLoadDynLtgPrmForReGrp24OffsetTime 1;
BA_ "GenSigSendType" SG_ 1189 DwnLoadDynLtgPrmForReGrp24Timestamp 1;
BA_ "GenSigSendType" SG_ 1196 DwnLoadDynLtgPrmForReGrp25ContinueTime 1;
BA_ "GenSigSendType" SG_ 1196 DwnLoadDynLtgPrmForReGrp25HighBrightness 1;
BA_ "GenSigSendType" SG_ 1196 DwnLoadDynLtgPrmForReGrp25LowBrightness 1;
BA_ "GenSigSendType" SG_ 1196 DwnLoadDynLtgPrmForReGrp25Mode1 1;
BA_ "GenSigSendType" SG_ 1196 DwnLoadDynLtgPrmForReGrp25OffsetTime 1;
BA_ "GenSigSendType" SG_ 1196 DwnLoadDynLtgPrmForReGrp25Timestamp 1;
BA_ "GenSigSendType" SG_ 1196 DwnLoadDynLtgPrmForReGrp26ContinueTime 1;
BA_ "GenSigSendType" SG_ 1196 DwnLoadDynLtgPrmForReGrp26HighBrightness 1;
BA_ "GenSigSendType" SG_ 1196 DwnLoadDynLtgPrmForReGrp26LowBrightness 1;
BA_ "GenSigSendType" SG_ 1196 DwnLoadDynLtgPrmForReGrp26Mode1 1;
BA_ "GenSigSendType" SG_ 1196 DwnLoadDynLtgPrmForReGrp26OffsetTime 1;
BA_ "GenSigSendType" SG_ 1196 DwnLoadDynLtgPrmForReGrp26Timestamp 1;
BA_ "GenSigSendType" SG_ 1199 DwnLoadDynLtgPrmForReGrp27ContinueTime 1;
BA_ "GenSigSendType" SG_ 1199 DwnLoadDynLtgPrmForReGrp27HighBrightness 1;
BA_ "GenSigSendType" SG_ 1199 DwnLoadDynLtgPrmForReGrp27LowBrightness 1;
BA_ "GenSigSendType" SG_ 1199 DwnLoadDynLtgPrmForReGrp27Mode1 1;
BA_ "GenSigSendType" SG_ 1199 DwnLoadDynLtgPrmForReGrp27OffsetTime 1;
BA_ "GenSigSendType" SG_ 1199 DwnLoadDynLtgPrmForReGrp27Timestamp 1;
BA_ "GenSigSendType" SG_ 1199 DwnLoadDynLtgPrmForReGrp28ContinueTime 1;
BA_ "GenSigSendType" SG_ 1199 DwnLoadDynLtgPrmForReGrp28HighBrightness 1;
BA_ "GenSigSendType" SG_ 1199 DwnLoadDynLtgPrmForReGrp28LowBrightness 1;
BA_ "GenSigSendType" SG_ 1199 DwnLoadDynLtgPrmForReGrp28Mode1 1;
BA_ "GenSigSendType" SG_ 1199 DwnLoadDynLtgPrmForReGrp28OffsetTime 1;
BA_ "GenSigSendType" SG_ 1199 DwnLoadDynLtgPrmForReGrp28Timestamp 1;
BA_ "GenSigSendType" SG_ 1201 DwnLoadDynLtgPrmForReGrp29ContinueTime 1;
BA_ "GenSigSendType" SG_ 1201 DwnLoadDynLtgPrmForReGrp29HighBrightness 1;
BA_ "GenSigSendType" SG_ 1201 DwnLoadDynLtgPrmForReGrp29LowBrightness 1;
BA_ "GenSigSendType" SG_ 1201 DwnLoadDynLtgPrmForReGrp29Mode1 1;
BA_ "GenSigSendType" SG_ 1201 DwnLoadDynLtgPrmForReGrp29OffsetTime 1;
BA_ "GenSigSendType" SG_ 1201 DwnLoadDynLtgPrmForReGrp29Timestamp 1;
BA_ "GenSigSendType" SG_ 1119 DwnLoadDynLtgPrmForReGrp2ContinueTime 1;
BA_ "GenSigSendType" SG_ 1119 DwnLoadDynLtgPrmForReGrp2HighBrightness 1;
BA_ "GenSigSendType" SG_ 1119 DwnLoadDynLtgPrmForReGrp2LowBrightness 1;
BA_ "GenSigSendType" SG_ 1119 DwnLoadDynLtgPrmForReGrp2Mode1 1;
BA_ "GenSigSendType" SG_ 1119 DwnLoadDynLtgPrmForReGrp2OffsetTime 1;
BA_ "GenSigSendType" SG_ 1119 DwnLoadDynLtgPrmForReGrp2Timestamp 1;
BA_ "GenSigSendType" SG_ 1201 DwnLoadDynLtgPrmForReGrp30ContinueTime 1;
BA_ "GenSigSendType" SG_ 1201 DwnLoadDynLtgPrmForReGrp30HighBrightness 1;
BA_ "GenSigSendType" SG_ 1201 DwnLoadDynLtgPrmForReGrp30LowBrightness 1;
BA_ "GenSigSendType" SG_ 1201 DwnLoadDynLtgPrmForReGrp30Mode1 1;
BA_ "GenSigSendType" SG_ 1201 DwnLoadDynLtgPrmForReGrp30OffsetTime 1;
BA_ "GenSigSendType" SG_ 1201 DwnLoadDynLtgPrmForReGrp30Timestamp 1;
BA_ "GenSigSendType" SG_ 1122 DwnLoadDynLtgPrmForReGrp3ContinueTime 1;
BA_ "GenSigSendType" SG_ 1122 DwnLoadDynLtgPrmForReGrp3HighBrightness 1;
BA_ "GenSigSendType" SG_ 1122 DwnLoadDynLtgPrmForReGrp3LowBrightness 1;
BA_ "GenSigSendType" SG_ 1122 DwnLoadDynLtgPrmForReGrp3Mode1 1;
BA_ "GenSigSendType" SG_ 1122 DwnLoadDynLtgPrmForReGrp3OffsetTime 1;
BA_ "GenSigSendType" SG_ 1122 DwnLoadDynLtgPrmForReGrp3Timestamp 1;
BA_ "GenSigSendType" SG_ 1122 DwnLoadDynLtgPrmForReGrp4ContinueTime 1;
BA_ "GenSigSendType" SG_ 1122 DwnLoadDynLtgPrmForReGrp4HighBrightness 1;
BA_ "GenSigSendType" SG_ 1122 DwnLoadDynLtgPrmForReGrp4LowBrightness 1;
BA_ "GenSigSendType" SG_ 1122 DwnLoadDynLtgPrmForReGrp4Mode1 1;
BA_ "GenSigSendType" SG_ 1122 DwnLoadDynLtgPrmForReGrp4OffsetTime 1;
BA_ "GenSigSendType" SG_ 1122 DwnLoadDynLtgPrmForReGrp4Timestamp 1;
BA_ "GenSigSendType" SG_ 1125 DwnLoadDynLtgPrmForReGrp5ContinueTime 1;
BA_ "GenSigSendType" SG_ 1125 DwnLoadDynLtgPrmForReGrp5HighBrightness 1;
BA_ "GenSigSendType" SG_ 1125 DwnLoadDynLtgPrmForReGrp5LowBrightness 1;
BA_ "GenSigSendType" SG_ 1125 DwnLoadDynLtgPrmForReGrp5Mode1 1;
BA_ "GenSigSendType" SG_ 1125 DwnLoadDynLtgPrmForReGrp5OffsetTime 1;
BA_ "GenSigSendType" SG_ 1125 DwnLoadDynLtgPrmForReGrp5Timestamp 1;
BA_ "GenSigSendType" SG_ 1125 DwnLoadDynLtgPrmForReGrp6ContinueTime 1;
BA_ "GenSigSendType" SG_ 1125 DwnLoadDynLtgPrmForReGrp6HighBrightness 1;
BA_ "GenSigSendType" SG_ 1125 DwnLoadDynLtgPrmForReGrp6LowBrightness 1;
BA_ "GenSigSendType" SG_ 1125 DwnLoadDynLtgPrmForReGrp6Mode1 1;
BA_ "GenSigSendType" SG_ 1125 DwnLoadDynLtgPrmForReGrp6OffsetTime 1;
BA_ "GenSigSendType" SG_ 1125 DwnLoadDynLtgPrmForReGrp6Timestamp 1;
BA_ "GenSigSendType" SG_ 1129 DwnLoadDynLtgPrmForReGrp7ContinueTime 1;
BA_ "GenSigSendType" SG_ 1129 DwnLoadDynLtgPrmForReGrp7HighBrightness 1;
BA_ "GenSigSendType" SG_ 1129 DwnLoadDynLtgPrmForReGrp7LowBrightness 1;
BA_ "GenSigSendType" SG_ 1129 DwnLoadDynLtgPrmForReGrp7Mode1 1;
BA_ "GenSigSendType" SG_ 1129 DwnLoadDynLtgPrmForReGrp7OffsetTime 1;
BA_ "GenSigSendType" SG_ 1129 DwnLoadDynLtgPrmForReGrp7Timestamp 1;
BA_ "GenSigSendType" SG_ 1129 DwnLoadDynLtgPrmForReGrp8ContinueTime 1;
BA_ "GenSigSendType" SG_ 1129 DwnLoadDynLtgPrmForReGrp8HighBrightness 1;
BA_ "GenSigSendType" SG_ 1129 DwnLoadDynLtgPrmForReGrp8LowBrightness 1;
BA_ "GenSigSendType" SG_ 1129 DwnLoadDynLtgPrmForReGrp8Mode1 1;
BA_ "GenSigSendType" SG_ 1129 DwnLoadDynLtgPrmForReGrp8OffsetTime 1;
BA_ "GenSigSendType" SG_ 1129 DwnLoadDynLtgPrmForReGrp8Timestamp 1;
BA_ "GenSigSendType" SG_ 1146 DwnLoadDynLtgPrmForReGrp9ContinueTime 1;
BA_ "GenSigSendType" SG_ 1146 DwnLoadDynLtgPrmForReGrp9HighBrightness 1;
BA_ "GenSigSendType" SG_ 1146 DwnLoadDynLtgPrmForReGrp9LowBrightness 1;
BA_ "GenSigSendType" SG_ 1146 DwnLoadDynLtgPrmForReGrp9Mode1 1;
BA_ "GenSigSendType" SG_ 1146 DwnLoadDynLtgPrmForReGrp9OffsetTime 1;
BA_ "GenSigSendType" SG_ 1146 DwnLoadDynLtgPrmForReGrp9Timestamp 1;
BA_ "GenSigSendType" SG_ 124 DwnLoadStsFbOfHdlampLe 0;
BA_ "GenSigSendType" SG_ 127 DwnLoadStsFbOfHdlampRi 0;
BA_ "GenSigSendType" SG_ 124 DwnLoadStsFbOfLogoLampLe 0;
BA_ "GenSigSendType" SG_ 127 DwnLoadStsFbOfLogoLampRi 0;
BA_ "GenSigSendType" SG_ 124 ExtrLiShowActvnFrntLeFb 0;
BA_ "GenSigSendType" SG_ 127 ExtrLiShowActvnFrntRiFb 0;
BA_ "GenSigSendType" SG_ 124 ExtrLiShowActvnLeLogoFb 0;
BA_ "GenSigSendType" SG_ 127 ExtrLiShowActvnRiLogoFb 0;
BA_ "GenSigSendType" SG_ 593 ExtrLiShowStoreStsFrntLe 0;
BA_ "GenSigSendType" SG_ 594 ExtrLiShowStoreStsFrntRi 0;
BA_ "GenSigSendType" SG_ 124 HdlampLeInpSts1 0;
BA_ "GenSigSendType" SG_ 124 HdlampLeInpSts2 0;
BA_ "GenSigSendType" SG_ 127 HdlampRiInpSts1 0;
BA_ "GenSigSendType" SG_ 127 HdlampRiInpSts2 0;
BA_ "GenSigSendType" SG_ 124 StsOfAfsLe 0;
BA_ "GenSigSendType" SG_ 127 StsOfAfsRi 0;
BA_ "GenSigSendType" SG_ 124 StsOfAhbcLe 0;
BA_ "GenSigSendType" SG_ 127 StsOfAhbcRi 0;
BA_ "GenSigSendType" SG_ 124 StsOfFrntSideMkrLampLe2 0;
BA_ "GenSigSendType" SG_ 127 StsOfFrntSideMkrLampRi2 0;
BA_ "GenSigSendType" SG_ 124 StsOfLedCornrgLampLe 0;
BA_ "GenSigSendType" SG_ 127 StsOfLedCornrgLampRi 0;
BA_ "GenSigSendType" SG_ 124 StsOfLedDaytiRunngLampLe 0;
BA_ "GenSigSendType" SG_ 127 StsOfLedDaytiRunngLampRi 0;
BA_ "GenSigSendType" SG_ 124 StsOfLedFrntFogLampLe 0;
BA_ "GenSigSendType" SG_ 127 StsOfLedFrntFogLampRi 0;
BA_ "GenSigSendType" SG_ 124 StsOfLedFrntPosnLampLe 0;
BA_ "GenSigSendType" SG_ 127 StsOfLedFrntPosnLampRi 0;
BA_ "GenSigSendType" SG_ 124 StsOfLedFrntTurnIndcrLe 0;
BA_ "GenSigSendType" SG_ 127 StsOfLedFrntTurnIndcrRi 0;
BA_ "GenSigSendType" SG_ 593 StsOfLedHiBeamLe 0;
BA_ "GenSigSendType" SG_ 594 StsOfLedHiBeamRi 0;
BA_ "GenSigSendType" SG_ 593 StsOfLedLeLogoLamp 0;
BA_ "GenSigSendType" SG_ 593 StsOfLedLoBeamLe 0;
BA_ "GenSigSendType" SG_ 594 StsOfLedLoBeamRi 0;
BA_ "GenSigSendType" SG_ 594 StsOfLedRiLogoLamp 0;
BA_ "GenSigSendType" SG_ 124 StsOfLvlgLeChks 0;
BA_ "GenSigSendType" SG_ 124 StsOfLvlgLeCntr 0;
BA_ "GenSigSendType" SG_ 124 StsOfLvlgLeStsOfLvlgLe 0;
BA_ "GenSigSendType" SG_ 127 StsOfLvlgRiChks 0;
BA_ "GenSigSendType" SG_ 127 StsOfLvlgRiCntr 0;
BA_ "GenSigSendType" SG_ 127 StsOfLvlgRiStsOfLvlgRi 0;
BA_ "GenSigSendType" SG_ 124 StsOfSwvlgLe 0;
BA_ "GenSigSendType" SG_ 127 StsOfSwvlgRi 0;
BA_ "GenSigSendType" SG_ 124 StsOfTouristModLe 0;
BA_ "GenSigSendType" SG_ 127 StsOfTouristModRi 0;
BA_ "GenSigSendType" SG_ 124 StsOfWelGbyFrntLe 0;
BA_ "GenSigSendType" SG_ 127 StsOfWelGbyFrntRi 0;
BA_ "GenSigSendType" SG_ 1346 VFCVectorZCUDMBlockID 0;
BA_ "GenSigSendType" SG_ 1346 VFCVectorZCUDMVFCid0 0;
BA_ "GenSigSendType" SG_ 1346 VFCVectorZCUDMVFCid1 0;
BA_ "GenSigSendType" SG_ 1346 VFCVectorZCUDMVFCid10 0;
BA_ "GenSigSendType" SG_ 1346 VFCVectorZCUDMVFCid11 0;
BA_ "GenSigSendType" SG_ 1346 VFCVectorZCUDMVFCid12 0;
BA_ "GenSigSendType" SG_ 1346 VFCVectorZCUDMVFCid13 0;
BA_ "GenSigSendType" SG_ 1346 VFCVectorZCUDMVFCid14 0;
BA_ "GenSigSendType" SG_ 1346 VFCVectorZCUDMVFCid15 0;
BA_ "GenSigSendType" SG_ 1346 VFCVectorZCUDMVFCid16 0;
BA_ "GenSigSendType" SG_ 1346 VFCVectorZCUDMVFCid17 0;
BA_ "GenSigSendType" SG_ 1346 VFCVectorZCUDMVFCid18 0;
BA_ "GenSigSendType" SG_ 1346 VFCVectorZCUDMVFCid19 0;
BA_ "GenSigSendType" SG_ 1346 VFCVectorZCUDMVFCid2 0;
BA_ "GenSigSendType" SG_ 1346 VFCVectorZCUDMVFCid20 0;
BA_ "GenSigSendType" SG_ 1346 VFCVectorZCUDMVFCid21 0;
BA_ "GenSigSendType" SG_ 1346 VFCVectorZCUDMVFCid22 0;
BA_ "GenSigSendType" SG_ 1346 VFCVectorZCUDMVFCid23 0;
BA_ "GenSigSendType" SG_ 1346 VFCVectorZCUDMVFCid24 0;
BA_ "GenSigSendType" SG_ 1346 VFCVectorZCUDMVFCid25 0;
BA_ "GenSigSendType" SG_ 1346 VFCVectorZCUDMVFCid26 0;
BA_ "GenSigSendType" SG_ 1346 VFCVectorZCUDMVFCid27 0;
BA_ "GenSigSendType" SG_ 1346 VFCVectorZCUDMVFCid28 0;
BA_ "GenSigSendType" SG_ 1346 VFCVectorZCUDMVFCid29 0;
BA_ "GenSigSendType" SG_ 1346 VFCVectorZCUDMVFCid3 0;
BA_ "GenSigSendType" SG_ 1346 VFCVectorZCUDMVFCid30 0;
BA_ "GenSigSendType" SG_ 1346 VFCVectorZCUDMVFCid31 0;
BA_ "GenSigSendType" SG_ 1346 VFCVectorZCUDMVFCid32 0;
BA_ "GenSigSendType" SG_ 1346 VFCVectorZCUDMVFCid33 0;
BA_ "GenSigSendType" SG_ 1346 VFCVectorZCUDMVFCid34 0;
BA_ "GenSigSendType" SG_ 1346 VFCVectorZCUDMVFCid35 0;
BA_ "GenSigSendType" SG_ 1346 VFCVectorZCUDMVFCid36 0;
BA_ "GenSigSendType" SG_ 1346 VFCVectorZCUDMVFCid37 0;
BA_ "GenSigSendType" SG_ 1346 VFCVectorZCUDMVFCid38 0;
BA_ "GenSigSendType" SG_ 1346 VFCVectorZCUDMVFCid39 0;
BA_ "GenSigSendType" SG_ 1346 VFCVectorZCUDMVFCid4 0;
BA_ "GenSigSendType" SG_ 1346 VFCVectorZCUDMVFCid40 0;
BA_ "GenSigSendType" SG_ 1346 VFCVectorZCUDMVFCid41 0;
BA_ "GenSigSendType" SG_ 1346 VFCVectorZCUDMVFCid42 0;
BA_ "GenSigSendType" SG_ 1346 VFCVectorZCUDMVFCid43 0;
BA_ "GenSigSendType" SG_ 1346 VFCVectorZCUDMVFCid44 0;
BA_ "GenSigSendType" SG_ 1346 VFCVectorZCUDMVFCid45 0;
BA_ "GenSigSendType" SG_ 1346 VFCVectorZCUDMVFCid46 0;
BA_ "GenSigSendType" SG_ 1346 VFCVectorZCUDMVFCid47 0;
BA_ "GenSigSendType" SG_ 1346 VFCVectorZCUDMVFCid48 0;
BA_ "GenSigSendType" SG_ 1346 VFCVectorZCUDMVFCid49 0;
BA_ "GenSigSendType" SG_ 1346 VFCVectorZCUDMVFCid5 0;
BA_ "GenSigSendType" SG_ 1346 VFCVectorZCUDMVFCid50 0;
BA_ "GenSigSendType" SG_ 1346 VFCVectorZCUDMVFCid51 0;
BA_ "GenSigSendType" SG_ 1346 VFCVectorZCUDMVFCid52 0;
BA_ "GenSigSendType" SG_ 1346 VFCVectorZCUDMVFCid53 0;
BA_ "GenSigSendType" SG_ 1346 VFCVectorZCUDMVFCid54 0;
BA_ "GenSigSendType" SG_ 1346 VFCVectorZCUDMVFCid55 0;
BA_ "GenSigSendType" SG_ 1346 VFCVectorZCUDMVFCid56 0;
BA_ "GenSigSendType" SG_ 1346 VFCVectorZCUDMVFCid57 0;
BA_ "GenSigSendType" SG_ 1346 VFCVectorZCUDMVFCid58 0;
BA_ "GenSigSendType" SG_ 1346 VFCVectorZCUDMVFCid59 0;
BA_ "GenSigSendType" SG_ 1346 VFCVectorZCUDMVFCid6 0;
BA_ "GenSigSendType" SG_ 1346 VFCVectorZCUDMVFCid60 0;
BA_ "GenSigSendType" SG_ 1346 VFCVectorZCUDMVFCid61 0;
BA_ "GenSigSendType" SG_ 1346 VFCVectorZCUDMVFCid7 0;
BA_ "GenSigSendType" SG_ 1346 VFCVectorZCUDMVFCid8 0;
BA_ "GenSigSendType" SG_ 1346 VFCVectorZCUDMVFCid9 0;
BA_ "GenSigSendType" SG_ 1329 WakeUpReasonsforHCML 0;
BA_ "GenSigSendType" SG_ 1330 WakeUpReasonsforHCMR 0;

VAL_ 1119 DwnLoadDynLtgPrmForReGrp1Mode1 0 "Mode6_Off" 1 "Mode6_On" 2 "Mode6_GradualOn" 3 "Mode6_GradualOff" 4 "Mode6_ForwardWipingOn" 5 "Mode6_BackwardWipingOn" 6 "Mode6_OutwardWipingOn" 7 "Mode6_InwardWipingOn" 8 "Mode6_ForwardWipingOff" 9 "Mode6_BackwardWipingOff" 10 "Mode6_OutwardWipingOff" 11 "Mode6_InwardWipingOff" 12 "Mode6_ForwardScanning" 13 "Mode6_BackwardScanning" 14 "Mode6_BreathOn" 15 "Mode6_BreathOff" 16 "Mode6_Spare1" 17 "Mode6_Spare2" 56 "Mode1_Stack" 57 "Mode1_Disappear";
VAL_ 1119 DwnLoadDynLtgPrmForReGrp2Mode1 0 "Mode6_Off" 1 "Mode6_On" 2 "Mode6_GradualOn" 3 "Mode6_GradualOff" 4 "Mode6_ForwardWipingOn" 5 "Mode6_BackwardWipingOn" 6 "Mode6_OutwardWipingOn" 7 "Mode6_InwardWipingOn" 8 "Mode6_ForwardWipingOff" 9 "Mode6_BackwardWipingOff" 10 "Mode6_OutwardWipingOff" 11 "Mode6_InwardWipingOff" 12 "Mode6_ForwardScanning" 13 "Mode6_BackwardScanning" 14 "Mode6_BreathOn" 15 "Mode6_BreathOff" 16 "Mode6_Spare1" 17 "Mode6_Spare2" 56 "Mode1_Stack" 57 "Mode1_Disappear";
VAL_ 1122 DwnLoadDynLtgPrmForReGrp3Mode1 0 "Mode6_Off" 1 "Mode6_On" 2 "Mode6_GradualOn" 3 "Mode6_GradualOff" 4 "Mode6_ForwardWipingOn" 5 "Mode6_BackwardWipingOn" 6 "Mode6_OutwardWipingOn" 7 "Mode6_InwardWipingOn" 8 "Mode6_ForwardWipingOff" 9 "Mode6_BackwardWipingOff" 10 "Mode6_OutwardWipingOff" 11 "Mode6_InwardWipingOff" 12 "Mode6_ForwardScanning" 13 "Mode6_BackwardScanning" 14 "Mode6_BreathOn" 15 "Mode6_BreathOff" 16 "Mode6_Spare1" 17 "Mode6_Spare2" 56 "Mode1_Stack" 57 "Mode1_Disappear";
VAL_ 1122 DwnLoadDynLtgPrmForReGrp4Mode1 0 "Mode6_Off" 1 "Mode6_On" 2 "Mode6_GradualOn" 3 "Mode6_GradualOff" 4 "Mode6_ForwardWipingOn" 5 "Mode6_BackwardWipingOn" 6 "Mode6_OutwardWipingOn" 7 "Mode6_InwardWipingOn" 8 "Mode6_ForwardWipingOff" 9 "Mode6_BackwardWipingOff" 10 "Mode6_OutwardWipingOff" 11 "Mode6_InwardWipingOff" 12 "Mode6_ForwardScanning" 13 "Mode6_BackwardScanning" 14 "Mode6_BreathOn" 15 "Mode6_BreathOff" 16 "Mode6_Spare1" 17 "Mode6_Spare2" 56 "Mode1_Stack" 57 "Mode1_Disappear";
VAL_ 1125 DwnLoadDynLtgPrmForReGrp5Mode1 0 "Mode6_Off" 1 "Mode6_On" 2 "Mode6_GradualOn" 3 "Mode6_GradualOff" 4 "Mode6_ForwardWipingOn" 5 "Mode6_BackwardWipingOn" 6 "Mode6_OutwardWipingOn" 7 "Mode6_InwardWipingOn" 8 "Mode6_ForwardWipingOff" 9 "Mode6_BackwardWipingOff" 10 "Mode6_OutwardWipingOff" 11 "Mode6_InwardWipingOff" 12 "Mode6_ForwardScanning" 13 "Mode6_BackwardScanning" 14 "Mode6_BreathOn" 15 "Mode6_BreathOff" 16 "Mode6_Spare1" 17 "Mode6_Spare2" 56 "Mode1_Stack" 57 "Mode1_Disappear";
VAL_ 1125 DwnLoadDynLtgPrmForReGrp6Mode1 0 "Mode6_Off" 1 "Mode6_On" 2 "Mode6_GradualOn" 3 "Mode6_GradualOff" 4 "Mode6_ForwardWipingOn" 5 "Mode6_BackwardWipingOn" 6 "Mode6_OutwardWipingOn" 7 "Mode6_InwardWipingOn" 8 "Mode6_ForwardWipingOff" 9 "Mode6_BackwardWipingOff" 10 "Mode6_OutwardWipingOff" 11 "Mode6_InwardWipingOff" 12 "Mode6_ForwardScanning" 13 "Mode6_BackwardScanning" 14 "Mode6_BreathOn" 15 "Mode6_BreathOff" 16 "Mode6_Spare1" 17 "Mode6_Spare2" 56 "Mode1_Stack" 57 "Mode1_Disappear";
VAL_ 1129 DwnLoadDynLtgPrmForReGrp7Mode1 0 "Mode6_Off" 1 "Mode6_On" 2 "Mode6_GradualOn" 3 "Mode6_GradualOff" 4 "Mode6_ForwardWipingOn" 5 "Mode6_BackwardWipingOn" 6 "Mode6_OutwardWipingOn" 7 "Mode6_InwardWipingOn" 8 "Mode6_ForwardWipingOff" 9 "Mode6_BackwardWipingOff" 10 "Mode6_OutwardWipingOff" 11 "Mode6_InwardWipingOff" 12 "Mode6_ForwardScanning" 13 "Mode6_BackwardScanning" 14 "Mode6_BreathOn" 15 "Mode6_BreathOff" 16 "Mode6_Spare1" 17 "Mode6_Spare2" 56 "Mode1_Stack" 57 "Mode1_Disappear";
VAL_ 1129 DwnLoadDynLtgPrmForReGrp8Mode1 0 "Mode6_Off" 1 "Mode6_On" 2 "Mode6_GradualOn" 3 "Mode6_GradualOff" 4 "Mode6_ForwardWipingOn" 5 "Mode6_BackwardWipingOn" 6 "Mode6_OutwardWipingOn" 7 "Mode6_InwardWipingOn" 8 "Mode6_ForwardWipingOff" 9 "Mode6_BackwardWipingOff" 10 "Mode6_OutwardWipingOff" 11 "Mode6_InwardWipingOff" 12 "Mode6_ForwardScanning" 13 "Mode6_BackwardScanning" 14 "Mode6_BreathOn" 15 "Mode6_BreathOff" 16 "Mode6_Spare1" 17 "Mode6_Spare2" 56 "Mode1_Stack" 57 "Mode1_Disappear";
VAL_ 1146 DwnLoadDynLtgPrmForReGrp10Mode1 0 "Mode6_Off" 1 "Mode6_On" 2 "Mode6_GradualOn" 3 "Mode6_GradualOff" 4 "Mode6_ForwardWipingOn" 5 "Mode6_BackwardWipingOn" 6 "Mode6_OutwardWipingOn" 7 "Mode6_InwardWipingOn" 8 "Mode6_ForwardWipingOff" 9 "Mode6_BackwardWipingOff" 10 "Mode6_OutwardWipingOff" 11 "Mode6_InwardWipingOff" 12 "Mode6_ForwardScanning" 13 "Mode6_BackwardScanning" 14 "Mode6_BreathOn" 15 "Mode6_BreathOff" 16 "Mode6_Spare1" 17 "Mode6_Spare2" 56 "Mode1_Stack" 57 "Mode1_Disappear";
VAL_ 1146 DwnLoadDynLtgPrmForReGrp9Mode1 0 "Mode6_Off" 1 "Mode6_On" 2 "Mode6_GradualOn" 3 "Mode6_GradualOff" 4 "Mode6_ForwardWipingOn" 5 "Mode6_BackwardWipingOn" 6 "Mode6_OutwardWipingOn" 7 "Mode6_InwardWipingOn" 8 "Mode6_ForwardWipingOff" 9 "Mode6_BackwardWipingOff" 10 "Mode6_OutwardWipingOff" 11 "Mode6_InwardWipingOff" 12 "Mode6_ForwardScanning" 13 "Mode6_BackwardScanning" 14 "Mode6_BreathOn" 15 "Mode6_BreathOff" 16 "Mode6_Spare1" 17 "Mode6_Spare2" 56 "Mode1_Stack" 57 "Mode1_Disappear";
VAL_ 1151 DwnLoadDynLtgPrmForReGrp11Mode1 0 "Mode6_Off" 1 "Mode6_On" 2 "Mode6_GradualOn" 3 "Mode6_GradualOff" 4 "Mode6_ForwardWipingOn" 5 "Mode6_BackwardWipingOn" 6 "Mode6_OutwardWipingOn" 7 "Mode6_InwardWipingOn" 8 "Mode6_ForwardWipingOff" 9 "Mode6_BackwardWipingOff" 10 "Mode6_OutwardWipingOff" 11 "Mode6_InwardWipingOff" 12 "Mode6_ForwardScanning" 13 "Mode6_BackwardScanning" 14 "Mode6_BreathOn" 15 "Mode6_BreathOff" 16 "Mode6_Spare1" 17 "Mode6_Spare2" 56 "Mode1_Stack" 57 "Mode1_Disappear";
VAL_ 1151 DwnLoadDynLtgPrmForReGrp12Mode1 0 "Mode6_Off" 1 "Mode6_On" 2 "Mode6_GradualOn" 3 "Mode6_GradualOff" 4 "Mode6_ForwardWipingOn" 5 "Mode6_BackwardWipingOn" 6 "Mode6_OutwardWipingOn" 7 "Mode6_InwardWipingOn" 8 "Mode6_ForwardWipingOff" 9 "Mode6_BackwardWipingOff" 10 "Mode6_OutwardWipingOff" 11 "Mode6_InwardWipingOff" 12 "Mode6_ForwardScanning" 13 "Mode6_BackwardScanning" 14 "Mode6_BreathOn" 15 "Mode6_BreathOff" 16 "Mode6_Spare1" 17 "Mode6_Spare2" 56 "Mode1_Stack" 57 "Mode1_Disappear";
VAL_ 1157 DwnLoadDynLtgPrmForReGrp13Mode1 0 "Mode6_Off" 1 "Mode6_On" 2 "Mode6_GradualOn" 3 "Mode6_GradualOff" 4 "Mode6_ForwardWipingOn" 5 "Mode6_BackwardWipingOn" 6 "Mode6_OutwardWipingOn" 7 "Mode6_InwardWipingOn" 8 "Mode6_ForwardWipingOff" 9 "Mode6_BackwardWipingOff" 10 "Mode6_OutwardWipingOff" 11 "Mode6_InwardWipingOff" 12 "Mode6_ForwardScanning" 13 "Mode6_BackwardScanning" 14 "Mode6_BreathOn" 15 "Mode6_BreathOff" 16 "Mode6_Spare1" 17 "Mode6_Spare2" 56 "Mode1_Stack" 57 "Mode1_Disappear";
VAL_ 1157 DwnLoadDynLtgPrmForReGrp14Mode1 0 "Mode6_Off" 1 "Mode6_On" 2 "Mode6_GradualOn" 3 "Mode6_GradualOff" 4 "Mode6_ForwardWipingOn" 5 "Mode6_BackwardWipingOn" 6 "Mode6_OutwardWipingOn" 7 "Mode6_InwardWipingOn" 8 "Mode6_ForwardWipingOff" 9 "Mode6_BackwardWipingOff" 10 "Mode6_OutwardWipingOff" 11 "Mode6_InwardWipingOff" 12 "Mode6_ForwardScanning" 13 "Mode6_BackwardScanning" 14 "Mode6_BreathOn" 15 "Mode6_BreathOff" 16 "Mode6_Spare1" 17 "Mode6_Spare2" 56 "Mode1_Stack" 57 "Mode1_Disappear";
VAL_ 1165 DwnLoadDynLtgPrmForReGrp15Mode1 0 "Mode6_Off" 1 "Mode6_On" 2 "Mode6_GradualOn" 3 "Mode6_GradualOff" 4 "Mode6_ForwardWipingOn" 5 "Mode6_BackwardWipingOn" 6 "Mode6_OutwardWipingOn" 7 "Mode6_InwardWipingOn" 8 "Mode6_ForwardWipingOff" 9 "Mode6_BackwardWipingOff" 10 "Mode6_OutwardWipingOff" 11 "Mode6_InwardWipingOff" 12 "Mode6_ForwardScanning" 13 "Mode6_BackwardScanning" 14 "Mode6_BreathOn" 15 "Mode6_BreathOff" 16 "Mode6_Spare1" 17 "Mode6_Spare2" 56 "Mode1_Stack" 57 "Mode1_Disappear";
VAL_ 1165 DwnLoadDynLtgPrmForReGrp16Mode1 0 "Mode6_Off" 1 "Mode6_On" 2 "Mode6_GradualOn" 3 "Mode6_GradualOff" 4 "Mode6_ForwardWipingOn" 5 "Mode6_BackwardWipingOn" 6 "Mode6_OutwardWipingOn" 7 "Mode6_InwardWipingOn" 8 "Mode6_ForwardWipingOff" 9 "Mode6_BackwardWipingOff" 10 "Mode6_OutwardWipingOff" 11 "Mode6_InwardWipingOff" 12 "Mode6_ForwardScanning" 13 "Mode6_BackwardScanning" 14 "Mode6_BreathOn" 15 "Mode6_BreathOff" 16 "Mode6_Spare1" 17 "Mode6_Spare2" 56 "Mode1_Stack" 57 "Mode1_Disappear";
VAL_ 1167 DwnLoadDynLtgPrmForReGrp17Mode1 0 "Mode6_Off" 1 "Mode6_On" 2 "Mode6_GradualOn" 3 "Mode6_GradualOff" 4 "Mode6_ForwardWipingOn" 5 "Mode6_BackwardWipingOn" 6 "Mode6_OutwardWipingOn" 7 "Mode6_InwardWipingOn" 8 "Mode6_ForwardWipingOff" 9 "Mode6_BackwardWipingOff" 10 "Mode6_OutwardWipingOff" 11 "Mode6_InwardWipingOff" 12 "Mode6_ForwardScanning" 13 "Mode6_BackwardScanning" 14 "Mode6_BreathOn" 15 "Mode6_BreathOff" 16 "Mode6_Spare1" 17 "Mode6_Spare2" 56 "Mode1_Stack" 57 "Mode1_Disappear";
VAL_ 1167 DwnLoadDynLtgPrmForReGrp18Mode1 0 "Mode6_Off" 1 "Mode6_On" 2 "Mode6_GradualOn" 3 "Mode6_GradualOff" 4 "Mode6_ForwardWipingOn" 5 "Mode6_BackwardWipingOn" 6 "Mode6_OutwardWipingOn" 7 "Mode6_InwardWipingOn" 8 "Mode6_ForwardWipingOff" 9 "Mode6_BackwardWipingOff" 10 "Mode6_OutwardWipingOff" 11 "Mode6_InwardWipingOff" 12 "Mode6_ForwardScanning" 13 "Mode6_BackwardScanning" 14 "Mode6_BreathOn" 15 "Mode6_BreathOff" 16 "Mode6_Spare1" 17 "Mode6_Spare2" 56 "Mode1_Stack" 57 "Mode1_Disappear";
VAL_ 1178 DwnLoadDynLtgPrmForReGrp19Mode1 0 "Mode6_Off" 1 "Mode6_On" 2 "Mode6_GradualOn" 3 "Mode6_GradualOff" 4 "Mode6_ForwardWipingOn" 5 "Mode6_BackwardWipingOn" 6 "Mode6_OutwardWipingOn" 7 "Mode6_InwardWipingOn" 8 "Mode6_ForwardWipingOff" 9 "Mode6_BackwardWipingOff" 10 "Mode6_OutwardWipingOff" 11 "Mode6_InwardWipingOff" 12 "Mode6_ForwardScanning" 13 "Mode6_BackwardScanning" 14 "Mode6_BreathOn" 15 "Mode6_BreathOff" 16 "Mode6_Spare1" 17 "Mode6_Spare2" 56 "Mode1_Stack" 57 "Mode1_Disappear";
VAL_ 1178 DwnLoadDynLtgPrmForReGrp20Mode1 0 "Mode6_Off" 1 "Mode6_On" 2 "Mode6_GradualOn" 3 "Mode6_GradualOff" 4 "Mode6_ForwardWipingOn" 5 "Mode6_BackwardWipingOn" 6 "Mode6_OutwardWipingOn" 7 "Mode6_InwardWipingOn" 8 "Mode6_ForwardWipingOff" 9 "Mode6_BackwardWipingOff" 10 "Mode6_OutwardWipingOff" 11 "Mode6_InwardWipingOff" 12 "Mode6_ForwardScanning" 13 "Mode6_BackwardScanning" 14 "Mode6_BreathOn" 15 "Mode6_BreathOff" 16 "Mode6_Spare1" 17 "Mode6_Spare2" 56 "Mode1_Stack" 57 "Mode1_Disappear";
VAL_ 1183 DwnLoadDynLtgPrmForReGrp21Mode1 0 "Mode6_Off" 1 "Mode6_On" 2 "Mode6_GradualOn" 3 "Mode6_GradualOff" 4 "Mode6_ForwardWipingOn" 5 "Mode6_BackwardWipingOn" 6 "Mode6_OutwardWipingOn" 7 "Mode6_InwardWipingOn" 8 "Mode6_ForwardWipingOff" 9 "Mode6_BackwardWipingOff" 10 "Mode6_OutwardWipingOff" 11 "Mode6_InwardWipingOff" 12 "Mode6_ForwardScanning" 13 "Mode6_BackwardScanning" 14 "Mode6_BreathOn" 15 "Mode6_BreathOff" 16 "Mode6_Spare1" 17 "Mode6_Spare2" 56 "Mode1_Stack" 57 "Mode1_Disappear";
VAL_ 1183 DwnLoadDynLtgPrmForReGrp22Mode1 0 "Mode6_Off" 1 "Mode6_On" 2 "Mode6_GradualOn" 3 "Mode6_GradualOff" 4 "Mode6_ForwardWipingOn" 5 "Mode6_BackwardWipingOn" 6 "Mode6_OutwardWipingOn" 7 "Mode6_InwardWipingOn" 8 "Mode6_ForwardWipingOff" 9 "Mode6_BackwardWipingOff" 10 "Mode6_OutwardWipingOff" 11 "Mode6_InwardWipingOff" 12 "Mode6_ForwardScanning" 13 "Mode6_BackwardScanning" 14 "Mode6_BreathOn" 15 "Mode6_BreathOff" 16 "Mode6_Spare1" 17 "Mode6_Spare2" 56 "Mode1_Stack" 57 "Mode1_Disappear";
VAL_ 1189 DwnLoadDynLtgPrmForReGrp23Mode1 0 "Mode6_Off" 1 "Mode6_On" 2 "Mode6_GradualOn" 3 "Mode6_GradualOff" 4 "Mode6_ForwardWipingOn" 5 "Mode6_BackwardWipingOn" 6 "Mode6_OutwardWipingOn" 7 "Mode6_InwardWipingOn" 8 "Mode6_ForwardWipingOff" 9 "Mode6_BackwardWipingOff" 10 "Mode6_OutwardWipingOff" 11 "Mode6_InwardWipingOff" 12 "Mode6_ForwardScanning" 13 "Mode6_BackwardScanning" 14 "Mode6_BreathOn" 15 "Mode6_BreathOff" 16 "Mode6_Spare1" 17 "Mode6_Spare2" 56 "Mode1_Stack" 57 "Mode1_Disappear";
VAL_ 1189 DwnLoadDynLtgPrmForReGrp24Mode1 0 "Mode6_Off" 1 "Mode6_On" 2 "Mode6_GradualOn" 3 "Mode6_GradualOff" 4 "Mode6_ForwardWipingOn" 5 "Mode6_BackwardWipingOn" 6 "Mode6_OutwardWipingOn" 7 "Mode6_InwardWipingOn" 8 "Mode6_ForwardWipingOff" 9 "Mode6_BackwardWipingOff" 10 "Mode6_OutwardWipingOff" 11 "Mode6_InwardWipingOff" 12 "Mode6_ForwardScanning" 13 "Mode6_BackwardScanning" 14 "Mode6_BreathOn" 15 "Mode6_BreathOff" 16 "Mode6_Spare1" 17 "Mode6_Spare2" 56 "Mode1_Stack" 57 "Mode1_Disappear";
VAL_ 1196 DwnLoadDynLtgPrmForReGrp25Mode1 0 "Mode6_Off" 1 "Mode6_On" 2 "Mode6_GradualOn" 3 "Mode6_GradualOff" 4 "Mode6_ForwardWipingOn" 5 "Mode6_BackwardWipingOn" 6 "Mode6_OutwardWipingOn" 7 "Mode6_InwardWipingOn" 8 "Mode6_ForwardWipingOff" 9 "Mode6_BackwardWipingOff" 10 "Mode6_OutwardWipingOff" 11 "Mode6_InwardWipingOff" 12 "Mode6_ForwardScanning" 13 "Mode6_BackwardScanning" 14 "Mode6_BreathOn" 15 "Mode6_BreathOff" 16 "Mode6_Spare1" 17 "Mode6_Spare2" 56 "Mode1_Stack" 57 "Mode1_Disappear";
VAL_ 1196 DwnLoadDynLtgPrmForReGrp26Mode1 0 "Mode6_Off" 1 "Mode6_On" 2 "Mode6_GradualOn" 3 "Mode6_GradualOff" 4 "Mode6_ForwardWipingOn" 5 "Mode6_BackwardWipingOn" 6 "Mode6_OutwardWipingOn" 7 "Mode6_InwardWipingOn" 8 "Mode6_ForwardWipingOff" 9 "Mode6_BackwardWipingOff" 10 "Mode6_OutwardWipingOff" 11 "Mode6_InwardWipingOff" 12 "Mode6_ForwardScanning" 13 "Mode6_BackwardScanning" 14 "Mode6_BreathOn" 15 "Mode6_BreathOff" 16 "Mode6_Spare1" 17 "Mode6_Spare2" 56 "Mode1_Stack" 57 "Mode1_Disappear";
VAL_ 1199 DwnLoadDynLtgPrmForReGrp27Mode1 0 "Mode6_Off" 1 "Mode6_On" 2 "Mode6_GradualOn" 3 "Mode6_GradualOff" 4 "Mode6_ForwardWipingOn" 5 "Mode6_BackwardWipingOn" 6 "Mode6_OutwardWipingOn" 7 "Mode6_InwardWipingOn" 8 "Mode6_ForwardWipingOff" 9 "Mode6_BackwardWipingOff" 10 "Mode6_OutwardWipingOff" 11 "Mode6_InwardWipingOff" 12 "Mode6_ForwardScanning" 13 "Mode6_BackwardScanning" 14 "Mode6_BreathOn" 15 "Mode6_BreathOff" 16 "Mode6_Spare1" 17 "Mode6_Spare2" 56 "Mode1_Stack" 57 "Mode1_Disappear";
VAL_ 1199 DwnLoadDynLtgPrmForReGrp28Mode1 0 "Mode6_Off" 1 "Mode6_On" 2 "Mode6_GradualOn" 3 "Mode6_GradualOff" 4 "Mode6_ForwardWipingOn" 5 "Mode6_BackwardWipingOn" 6 "Mode6_OutwardWipingOn" 7 "Mode6_InwardWipingOn" 8 "Mode6_ForwardWipingOff" 9 "Mode6_BackwardWipingOff" 10 "Mode6_OutwardWipingOff" 11 "Mode6_InwardWipingOff" 12 "Mode6_ForwardScanning" 13 "Mode6_BackwardScanning" 14 "Mode6_BreathOn" 15 "Mode6_BreathOff" 16 "Mode6_Spare1" 17 "Mode6_Spare2" 56 "Mode1_Stack" 57 "Mode1_Disappear";
VAL_ 1201 DwnLoadDynLtgPrmForReGrp29Mode1 0 "Mode6_Off" 1 "Mode6_On" 2 "Mode6_GradualOn" 3 "Mode6_GradualOff" 4 "Mode6_ForwardWipingOn" 5 "Mode6_BackwardWipingOn" 6 "Mode6_OutwardWipingOn" 7 "Mode6_InwardWipingOn" 8 "Mode6_ForwardWipingOff" 9 "Mode6_BackwardWipingOff" 10 "Mode6_OutwardWipingOff" 11 "Mode6_InwardWipingOff" 12 "Mode6_ForwardScanning" 13 "Mode6_BackwardScanning" 14 "Mode6_BreathOn" 15 "Mode6_BreathOff" 16 "Mode6_Spare1" 17 "Mode6_Spare2" 56 "Mode1_Stack" 57 "Mode1_Disappear";
VAL_ 1201 DwnLoadDynLtgPrmForReGrp30Mode1 0 "Mode6_Off" 1 "Mode6_On" 2 "Mode6_GradualOn" 3 "Mode6_GradualOff" 4 "Mode6_ForwardWipingOn" 5 "Mode6_BackwardWipingOn" 6 "Mode6_OutwardWipingOn" 7 "Mode6_InwardWipingOn" 8 "Mode6_ForwardWipingOff" 9 "Mode6_BackwardWipingOff" 10 "Mode6_OutwardWipingOff" 11 "Mode6_InwardWipingOff" 12 "Mode6_ForwardScanning" 13 "Mode6_BackwardScanning" 14 "Mode6_BreathOn" 15 "Mode6_BreathOff" 16 "Mode6_Spare1" 17 "Mode6_Spare2" 56 "Mode1_Stack" 57 "Mode1_Disappear";
VAL_ 593 ExtrLiShowStoreStsFrntLe 0 "OnOff1_Off" 1 "OnOff1_On";
VAL_ 593 StsOfLedHiBeamLe 0 "DevSts4_Off" 1 "DevSts4_On" 2 "DevSts4_Err" 3 "DevSts4_Resd";
VAL_ 593 StsOfLedLeLogoLamp 0 "DevSts4_Off" 1 "DevSts4_On" 2 "DevSts4_Err" 3 "DevSts4_Resd";
VAL_ 593 StsOfLedLoBeamLe 0 "DevSts4_Off" 1 "DevSts4_On" 2 "DevSts4_Err" 3 "DevSts4_Resd";
VAL_ 124 DwnLoadStsFbOfHdlampLe 0 "Sts_Resd" 1 "Sts_Err" 2 "Sts_CmplOk" 3 "Sts_InProgs";
VAL_ 124 DwnLoadStsFbOfLogoLampLe 0 "Sts_Resd" 1 "Sts_Err" 2 "Sts_CmplOk" 3 "Sts_InProgs";
VAL_ 124 ExtrLiShowActvnFrntLeFb 0 "Sts_Resd" 1 "Sts_Err" 2 "Sts_CmplOk" 3 "Sts_InProgs";
VAL_ 124 ExtrLiShowActvnLeLogoFb 0 "Sts_Resd" 1 "Sts_Err" 2 "Sts_CmplOk" 3 "Sts_InProgs";
VAL_ 124 HdlampLeInpSts1 0 "Boolean_FALSE" 1 "Boolean_TRUE";
VAL_ 124 HdlampLeInpSts2 0 "Boolean_FALSE" 1 "Boolean_TRUE";
VAL_ 124 StsOfAfsLe 0 "DevSts4_Off" 1 "DevSts4_On" 2 "DevSts4_Err" 3 "DevSts4_Resd";
VAL_ 124 StsOfAhbcLe 0 "DevSts4_Off" 1 "DevSts4_On" 2 "DevSts4_Err" 3 "DevSts4_Resd";
VAL_ 124 StsOfFrntSideMkrLampLe2 0 "DevSts4_Off" 1 "DevSts4_On" 2 "DevSts4_Err" 3 "DevSts4_Resd";
VAL_ 124 StsOfLedCornrgLampLe 0 "DevSts4_Off" 1 "DevSts4_On" 2 "DevSts4_Err" 3 "DevSts4_Resd";
VAL_ 124 StsOfLedDaytiRunngLampLe 0 "DevSts4_Off" 1 "DevSts4_On" 2 "DevSts4_Err" 3 "DevSts4_Resd";
VAL_ 124 StsOfLedFrntFogLampLe 0 "DevSts4_Off" 1 "DevSts4_On" 2 "DevSts4_Err" 3 "DevSts4_Resd";
VAL_ 124 StsOfLedFrntPosnLampLe 0 "DevSts4_Off" 1 "DevSts4_On" 2 "DevSts4_Err" 3 "DevSts4_Resd";
VAL_ 124 StsOfLedFrntTurnIndcrLe 0 "DevSts4_Off" 1 "DevSts4_On" 2 "DevSts4_Err" 3 "DevSts4_Resd";
VAL_ 124 StsOfLvlgLeStsOfLvlgLe 0 "DevSts4_Off" 1 "DevSts4_On" 2 "DevSts4_Err" 3 "DevSts4_Resd";
VAL_ 124 StsOfSwvlgLe 0 "DevSts4_Off" 1 "DevSts4_On" 2 "DevSts4_Err" 3 "DevSts4_Resd";
VAL_ 124 StsOfTouristModLe 0 "DevSts4_Off" 1 "DevSts4_On" 2 "DevSts4_Err" 3 "DevSts4_Resd";
VAL_ 124 StsOfWelGbyFrntLe 0 "OnOff1_Off" 1 "OnOff1_On";
VAL_ 1329 WakeUpReasonsforHCML 0 "WakeupReasons_0" 1 "WakeupReasons_667950" 2 "WakeupReasons_169654" 3 "WakeupReasons_667951" 4 "WakeupReasons_168965" 5 "WakeupReasons_197643" 6 "WakeupReasons_264933" 7 "WakeupReasons_45654" 8 "WakeupReasons_22058" 9 "WakeupReasons_49446" 10 "WakeupReasons_22060" 11 "WakeupReasons_269740" 12 "WakeupReasons_269735" 13 "WakeupReasons_269739" 14 "WakeupReasons_658500" 15 "WakeupReasons_21901" 16 "WakeupReasons_45793" 17 "WakeupReasons_45794" 18 "WakeupReasons_22005" 19 "WakeupReasons_22013" 20 "WakeupReasons_22100" 21 "WakeupReasons_45659" 22 "WakeupReasons_45657" 23 "WakeupReasons_140084" 24 "WakeupReasons_21973" 25 "WakeupReasons_91253" 26 "WakeupReasons_88123" 27 "WakeupReasons_88125" 28 "WakeupReasons_321583" 29 "WakeupReasons_74188" 30 "WakeupReasons_667945" 31 "WakeupReasons_169655" 32 "WakeupReasons_667948" 33 "WakeupReasons_168966" 34 "WakeupReasons_170865" 35 "WakeupReasons_197642" 36 "WakeupReasons_264876" 37 "WakeupReasons_191050" 38 "WakeupReasons_182033" 39 "WakeupReasons_200937" 40 "WakeupReasons_170807" 41 "WakeupReasons_319139" 42 "WakeupReasons_100298" 43 "WakeupReasons_100275" 44 "WakeupReasons_100300" 45 "WakeupReasons_100278" 46 "WakeupReasons_100281" 47 "WakeupReasons_265333" 48 "WakeupReasons_108776" 49 "WakeupReasons_176921" 50 "WakeupReasons_197826" 51 "WakeupReasons_185670" 52 "WakeupReasons_161066" 53 "WakeupReasons_200156" 54 "WakeupReasons_225696" 55 "WakeupReasons_21997" 56 "WakeupReasons_45656" 57 "WakeupReasons_266860" 58 "WakeupReasons_169894" 59 "WakeupReasons_320282" 60 "WakeupReasons_319422" 61 "WakeupReasons_320277" 62 "WakeupReasons_355601" 63 "WakeupReasons_360904" 64 "WakeupReasons_361505" 65 "WakeupReasons_361509" 66 "WakeupReasons_645094" 67 "WakeupReasons_68676" 68 "WakeupReasons_360008" 69 "WakeupReasons_109382" 70 "WakeupReasons_119273" 71 "WakeupReasons_224065" 72 "WakeupReasons_68644" 73 "WakeupReasons_109364" 74 "WakeupReasons_68481" 75 "WakeupReasons_224061" 76 "WakeupReasons_360006" 77 "WakeupReasons_138997" 78 "WakeupReasons_634696" 79 "WakeupReasons_645810" 80 "WakeupReasons_297868" 81 "WakeupReasons_315364" 82 "WakeupReasons_109367" 83 "WakeupReasons_320126" 84 "WakeupReasons_109387" 85 "WakeupReasons_634710" 86 "WakeupReasons_338820" 87 "WakeupReasons_67182" 88 "WakeupReasons_152237" 89 "WakeupReasons_145707" 90 "WakeupReasons_199172" 91 "WakeupReasons_144897" 92 "WakeupReasons_186489" 93 "WakeupReasons_144970" 94 "WakeupReasons_152786" 95 "WakeupReasons_264932" 96 "WakeupReasons_264934" 97 "WakeupReasons_356190" 98 "WakeupReasons_145688" 99 "WakeupReasons_95444" 100 "WakeupReasons_169945" 101 "WakeupReasons_140678" 102 "WakeupReasons_222553" 103 "WakeupReasons_224831" 104 "WakeupReasons_201815" 105 "WakeupReasons_45864" 106 "WakeupReasons_659549" 107 "WakeupReasons_45866" 108 "WakeupReasons_45867" 109 "WakeupReasons_169884" 110 "WakeupReasons_264962" 111 "WakeupReasons_201348" 112 "WakeupReasons_320287" 113 "WakeupReasons_156412" 114 "WakeupReasons_133749" 115 "WakeupReasons_355409" 116 "WakeupReasons_636692" 117 "WakeupReasons_533044" 118 "WakeupReasons_106774" 119 "WakeupReasons_145311" 120 "WakeupReasons_145319" 121 "WakeupReasons_152774" 122 "WakeupReasons_145330" 123 "WakeupReasons_145388" 124 "WakeupReasons_145399" 125 "WakeupReasons_145362" 126 "WakeupReasons_145385" 127 "WakeupReasons_145373" 128 "WakeupReasons_145288" 129 "WakeupReasons_145419" 130 "WakeupReasons_145454" 131 "WakeupReasons_145462" 132 "WakeupReasons_269156" 133 "WakeupReasons_300427" 134 "WakeupReasons_220322" 135 "WakeupReasons_224617" 136 "WakeupReasons_224634" 137 "WakeupReasons_300682" 138 "WakeupReasons_264958" 139 "WakeupReasons_160597" 140 "WakeupReasons_160602" 141 "WakeupReasons_108841" 142 "WakeupReasons_265569" 143 "WakeupReasons_526429" 144 "WakeupReasons_514545" 145 "WakeupReasons_265232" 146 "WakeupReasons_644550" 147 "WakeupReasons_317616" 148 "WakeupReasons_354791" 149 "WakeupReasons_320631" 150 "WakeupReasons_337565" 151 "WakeupReasons_532007" 152 "WakeupReasons_514503" 153 "WakeupReasons_299117" 154 "WakeupReasons_340667" 155 "WakeupReasons_321845" 156 "WakeupReasons_179103" 157 "WakeupReasons_108810" 158 "WakeupReasons_322857" 159 "WakeupReasons_658603" 160 "WakeupReasons_197648" 161 "WakeupReasons_160596" 162 "WakeupReasons_361272" 163 "WakeupReasons_361279" 164 "WakeupReasons_265305" 165 "WakeupReasons_265328" 166 "WakeupReasons_265330" 167 "WakeupReasons_298808" 168 "WakeupReasons_515804" 169 "WakeupReasons_514502" 170 "WakeupReasons_645753" 171 "WakeupReasons_646109" 172 "WakeupReasons_299547" 173 "WakeupReasons_318342" 174 "WakeupReasons_360543" 175 "WakeupReasons_356549" 176 "WakeupReasons_198484" 177 "WakeupReasons_300681" 178 "WakeupReasons_359211" 179 "WakeupReasons_534077" 180 "WakeupReasons_525705" 181 "WakeupReasons_360299" 182 "WakeupReasons_526445" 183 "WakeupReasons_534145" 184 "WakeupReasons_192030" 185 "WakeupReasons_652361" 186 "WakeupReasons_355214" 187 "WakeupReasons_321317" 188 "WakeupReasons_359187" 189 "WakeupReasons_321057" 190 "WakeupReasons_321319" 191 "WakeupReasons_321323" 192 "WakeupReasons_321077" 193 "WakeupReasons_320895" 194 "WakeupReasons_655340" 195 "WakeupReasons_636556" 196 "WakeupReasons_108834" 197 "WakeupReasons_265937" 198 "WakeupReasons_533050" 199 "WakeupReasons_526426" 200 "WakeupReasons_264712" 201 "WakeupReasons_319401" 202 "WakeupReasons_643973" 203 "WakeupReasons_223715" 204 "WakeupReasons_199159" 205 "WakeupReasons_318382" 206 "WakeupReasons_226967" 207 "WakeupReasons_531743" 208 "WakeupReasons_360542" 209 "WakeupReasons_264726" 210 "WakeupReasons_535214" 211 "WakeupReasons_335068" 212 "WakeupReasons_316796" 213 "WakeupReasons_526438" 214 "WakeupReasons_198433" 215 "WakeupReasons_225961" 216 "WakeupReasons_197665" 217 "WakeupReasons_224550" 218 "WakeupReasons_667962" 219 "WakeupReasons_667953" 220 "WakeupReasons_110885" 221 "WakeupReasons_224552" 222 "WakeupReasons_224553" 223 "WakeupReasons_652546" 224 "WakeupReasons_331194" 225 "WakeupReasons_667820" 226 "WakeupReasons_659350" 227 "WakeupReasons_101706" 228 "WakeupReasons_101725" 229 "WakeupReasons_101728" 230 "WakeupReasons_101727" 231 "WakeupReasons_166267" 232 "WakeupReasons_156440" 233 "WakeupReasons_95949" 234 "WakeupReasons_112799" 235 "WakeupReasons_146470" 236 "WakeupReasons_176748" 237 "WakeupReasons_223920" 238 "WakeupReasons_668531" 239 "WakeupReasons_670087" 240 "WakeupReasons_668529" 241 "WakeupReasons_45858" 242 "WakeupReasons_315981" 243 "WakeupReasons_533370" 244 "WakeupReasons_533371" 245 "WakeupReasons_533372" 246 "WakeupReasons_241902" 247 "WakeupReasons_359559" 248 "WakeupReasons_516327" 249 "WakeupReasons_533872" 250 "WakeupReasons_45856" 251 "WakeupReasons_45853" 252 "WakeupReasons_45854" 253 "WakeupReasons_45852" 254 "WakeupReasons_45851" 255 "WakeupReasons_45850" 256 "WakeupReasons_45849" 257 "WakeupReasons_636801" 258 "WakeupReasons_109466" 259 "WakeupReasons_109467" 260 "WakeupReasons_670345" 261 "WakeupReasons_NMPDUReceived" 262 "WakeupReasons_358832" 263 "WakeupReasons_200683" 264 "WakeupReasons_198452" 265 "WakeupReasons_185457" 266 "WakeupReasons_185490" 267 "WakeupReasons_4471" 268 "WakeupReasons_269034" 269 "WakeupReasons_215560" 270 "WakeupReasons_312881" 271 "WakeupReasons_269140" 272 "WakeupReasons_197653" 273 "WakeupReasons_337991" 274 "WakeupReasons_658188" 275 "WakeupReasons_674953" 276 "WakeupReasons_675064" 277 "WakeupReasons_674958" 278 "WakeupReasons_675494" 279 "WakeupReasons_675837" 280 "WakeupReasons_667879" 281 "WakeupReasons_667947" 282 "WakeupReasons_676265" 283 "WakeupReasons_669465" 284 "WakeupReasons_670928" 285 "WakeupReasons_669447" 286 "WakeupReasons_667922" 287 "WakeupReasons_670753" 288 "WakeupReasons_668395" 289 "WakeupReasons_668393" 290 "WakeupReasons_667850" 291 "WakeupReasons_667848" 292 "WakeupReasons_311279" 293 "WakeupReasons_182918" 294 "WakeupReasons_667988" 295 "WakeupReasons_532555" 296 "WakeupReasons_532556" 297 "WakeupReasons_113348" 298 "WakeupReasons_193474" 299 "WakeupReasons_667871" 300 "WakeupReasons_670966" 301 "WakeupReasons_667985" 302 "WakeupReasons_670354" 303 "WakeupReasons_46017" 304 "WakeupReasons_675742" 305 "WakeupReasons_106669" 306 "WakeupReasons_80609" 307 "WakeupReasons_199714" 308 "WakeupReasons_200090" 309 "WakeupReasons_139075" 310 "WakeupReasons_268983" 311 "WakeupReasons_265131" 312 "WakeupReasons_263473" 313 "WakeupReasons_45887" 314 "WakeupReasons_69678" 315 "WakeupReasons_69679" 316 "WakeupReasons_45897" 317 "WakeupReasons_45898" 318 "WakeupReasons_80608" 319 "WakeupReasons_45869" 320 "WakeupReasons_45870" 321 "WakeupReasons_45872" 322 "WakeupReasons_45875" 323 "WakeupReasons_45871" 324 "WakeupReasons_45876" 325 "WakeupReasons_667980" 326 "WakeupReasons_45877" 327 "WakeupReasons_667973" 328 "WakeupReasons_670962" 329 "WakeupReasons_45888" 330 "WakeupReasons_45890" 331 "WakeupReasons_667869" 332 "WakeupReasons_45846" 333 "WakeupReasons_45847" 334 "WakeupReasons_45848" 335 "WakeupReasons_262872" 336 "WakeupReasons_127924" 337 "WakeupReasons_127926" 338 "WakeupReasons_674223" 339 "WakeupReasons_667982" 340 "WakeupReasons_657121" 341 "WakeupReasons_265745" 342 "WakeupReasons_657120" 343 "WakeupReasons_675564" 344 "WakeupReasons_197644" 345 "WakeupReasons_264943" 346 "WakeupReasons_264697" 347 "WakeupReasons_69216" 348 "WakeupReasons_128671" 349 "WakeupReasons_356598" 350 "WakeupReasons_675745" 351 "WakeupReasons_667983" 352 "WakeupReasons_667987" 353 "WakeupReasons_75103" 354 "WakeupReasons_305818" 355 "WakeupReasons_670942" 356 "WakeupReasons_532932" 357 "WakeupReasons_532933" 358 "WakeupReasons_83199" 359 "WakeupReasons_45900" 360 "WakeupReasons_88458" 361 "WakeupReasons_329457" 362 "WakeupReasons_45902" 363 "WakeupReasons_224211" 364 "WakeupReasons_667981" 365 "WakeupReasons_667874" 366 "WakeupReasons_46020" 367 "WakeupReasons_667842" 368 "WakeupReasons_145161" 369 "WakeupReasons_233755" 370 "WakeupReasons_297056" 371 "WakeupReasons_264691" 372 "WakeupReasons_262871" 373 "WakeupReasons_264964" 374 "WakeupReasons_667872" 375 "WakeupReasons_45655" 376 "WakeupReasons_177214" 377 "WakeupReasons_671005" 378 "WakeupReasons_680712" 379 "WakeupReasons_669822" 380 "WakeupReasons_668523" 381 "WakeupReasons_680974" 382 "WakeupReasons_680975" 383 "WakeupReasons_681028" 384 "WakeupReasons_670462" 385 "WakeupReasons_681134" 386 "WakeupReasons_681031" 387 "WakeupReasons_681711" 388 "WakeupReasons_682034" 389 "WakeupReasons_674839" 390 "WakeupReasons_681915" 391 "WakeupReasons_682032" 392 "WakeupReasons_682037" 393 "WakeupReasons_682688" 394 "WakeupReasons_681789" 395 "WakeupReasons_682023" 396 "WakeupReasons_681023" 397 "WakeupReasons_676285" 398 "WakeupReasons_682077" 399 "WakeupReasons_682076" 400 "WakeupReasons_682078" 401 "WakeupReasons_682153" 402 "WakeupReasons_682155" 403 "WakeupReasons_682152" 404 "WakeupReasons_682154" 405 "WakeupReasons_682074" 406 "WakeupReasons_680763" 407 "WakeupReasons_683934" 408 "WakeupReasons_265678" 409 "WakeupReasons_170285" 410 "WakeupReasons_200637" 411 "WakeupReasons_346654" 412 "WakeupReasons_91254" 413 "WakeupReasons_692021" 414 "WakeupReasons_690385" 415 "WakeupReasons_170290" 416 "WakeupReasons_357498" 417 "WakeupReasons_360491" 418 "WakeupReasons_265699" 419 "WakeupReasons_265698" 420 "WakeupReasons_641482" 421 "WakeupReasons_641483" 422 "WakeupReasons_168968" 423 "WakeupReasons_354674" 424 "WakeupReasons_168967" 425 "WakeupReasons_354672" 426 "WakeupReasons_112027" 427 "WakeupReasons_112035" 428 "WakeupReasons_692020" 429 "WakeupReasons_226565" 430 "WakeupReasons_675594" 431 "WakeupReasons_226571" 432 "WakeupReasons_690593" 433 "WakeupReasons_692022" 434 "WakeupReasons_354809" 435 "WakeupReasons_690939" 436 "WakeupReasons_677781" 437 "WakeupReasons_110173" 438 "WakeupReasons_112031" 439 "WakeupReasons_45896" 440 "WakeupReasons_226569" 441 "WakeupReasons_110181" 442 "WakeupReasons_654489" 443 "WakeupReasons_226570" 444 "WakeupReasons_351189" 445 "WakeupReasons_644275" 446 "WakeupReasons_45895" 447 "WakeupReasons_680765" 448 "WakeupReasons_354831" 449 "WakeupReasons_692439" 450 "WakeupReasons_265694" 451 "WakeupReasons_273516" 452 "WakeupReasons_299120" 453 "WakeupReasons_299531" 454 "WakeupReasons_299532" 455 "WakeupReasons_300690" 456 "WakeupReasons_112024" 457 "WakeupReasons_514651" 458 "WakeupReasons_514652" 459 "WakeupReasons_667188" 460 "WakeupReasons_533849" 461 "WakeupReasons_533850" 462 "WakeupReasons_692019" 463 "WakeupReasons_512384" 464 "WakeupReasons_680764" 465 "WakeupReasons_686281" 466 "WakeupReasons_667949" 467 "WakeupReasons_693005" 468 "WakeupReasons_693024" 469 "WakeupReasons_693914" 470 "WakeupReasons_692547" 471 "WakeupReasons_691991" 472 "WakeupReasons_698488" 473 "WakeupReasons_637992" 474 "WakeupReasons_702197" 475 "WakeupReasons_700425" 476 "WakeupReasons_700485" 477 "WakeupReasons_691993" 478 "WakeupReasons_698660" 479 "WakeupReasons_698288" 480 "WakeupReasons_681813" 481 "WakeupReasons_687404" 482 "WakeupReasons_700467" 483 "WakeupReasons_533750" 484 "WakeupReasons_698409" 485 "WakeupReasons_700686" 486 "WakeupReasons_700687" 487 "WakeupReasons_296931" 488 "WakeupReasons_697145" 489 "WakeupReasons_702174" 490 "WakeupReasons_194966" 491 "WakeupReasons_217907" 492 "WakeupReasons_700484" 493 "WakeupReasons_701508" 494 "WakeupReasons_701509" 495 "WakeupReasons_700215" 496 "WakeupReasons_700603" 497 "WakeupReasons_702204" 498 "WakeupReasons_700483" 499 "WakeupReasons_691994" 500 "WakeupReasons_696612" 501 "WakeupReasons_702088" 502 "WakeupReasons_696850" 503 "WakeupReasons_698129" 504 "WakeupReasons_691992" 505 "WakeupReasons_700554" 506 "WakeupReasons_683263" 507 "WakeupReasons_336435" 508 "WakeupReasons_644379" 509 "WakeupReasons_700684" 510 "WakeupReasons_697967" 511 "WakeupReasons_699922" 512 "WakeupReasons_698385" 513 "WakeupReasons_700692" 514 "WakeupReasons_696971" 515 "WakeupReasons_700782" 516 "WakeupReasons_700486" 517 "WakeupReasons_699919" 518 "WakeupReasons_699921" 519 "WakeupReasons_700130" 520 "WakeupReasons_698130" 521 "WakeupReasons_698581" 522 "WakeupReasons_533751" 523 "WakeupReasons_701270" 524 "WakeupReasons_702240" 525 "WakeupReasons_699114" 526 "WakeupReasons_701872" 527 "WakeupReasons_702448" 528 "WakeupReasons_702439" 529 "WakeupReasons_702402" 530 "WakeupReasons_700565" 531 "WakeupReasons_702452" 532 "WakeupReasons_698631" 533 "WakeupReasons_700530" 534 "WakeupReason_713752" 535 "WakeupReason_702478" 536 "WakeupReason_714675" 537 "WakeupReason_713786" 538 "WakeupReason_716243" 539 "WakeupReason_710922" 540 "WakeupReason_714030" 541 "WakeupReason_715842" 542 "WakeupReason_714678" 543 "WakeupReason_714679" 544 "WakeupReason_710807" 545 "WakeupReason_713568" 546 "WakeupReason_706194" 547 "WakeupReason_713799" 548 "WakeupReason_714172" 549 "WakeupReason_714265" 550 "WakeupReason_715529" 551 "WakeupReason_708964" 552 "WakeupReason_710893" 553 "WakeupReason_709196" 554 "WakeupReason_714806" 555 "WakeupReason_714799" 556 "WakeupReason_714697" 557 "WakeupReason_717832" 558 "WakeupReason_838116" 559 "WakeupReason_839473" 560 "WakeupReason_839705" 561 "WakeupReason_837833" 562 "WakeupReason_703140" 563 "WakeupReason_837962" 564 "WakeupReason_702903" 565 "WakeupReason_837760" 566 "WakeupReason_839458" 576 "WakeupReason_840035" 577 "WakeupReason_714677" 578 "WakeupReason_839181" 579 "WakeupReason_839787" 580 "WakeupReason_841275" 581 "WakeupReason_320145" 582 "WakeupReason_322113" 583 "WakeupReason_298032" 584 "WakeupReason_675452" 585 "WakeupReason_675489" 586 "WakeupReason_846372" 587 "WakeupReason_842273" 588 "WakeupReason_845930" 589 "WakeupReason_846002" 590 "WakeupReason_361441" 591 "WakeupReason_361474" 592 "WakeupReason_362462" 593 "WakeupReason_645735" 594 "WakeupReason_667533" 595 "WakeupReason_702420" 596 "WakeupReason_851482" 597 "WakeupReason_851743" 598 "WakeupReason_852010" 599 "WakeupReason_852050" 600 "WakeupReason_852180" 601 "WakeupReason_852184" 602 "WakeupReason_852194" 603 "WakeupReason_852195" 604 "WakeupReason_852200" 605 "WakeupReason_852215" 606 "WakeupReason_852218" 607 "WakeupReason_852219" 608 "WakeupReason_852248" 609 "WakeupReason_852273" 610 "WakeupReason_852298" 611 "WakeupReason_852385" 612 "WakeupReason_852388" 613 "WakeupReason_852537" 614 "WakeupReason_852646" 615 "WakeupReason_852944" 616 "WakeupReason_852947";
VAL_ 594 ExtrLiShowStoreStsFrntRi 0 "OnOff1_Off" 1 "OnOff1_On";
VAL_ 594 StsOfLedHiBeamRi 0 "DevSts4_Off" 1 "DevSts4_On" 2 "DevSts4_Err" 3 "DevSts4_Resd";
VAL_ 594 StsOfLedLoBeamRi 0 "DevSts4_Off" 1 "DevSts4_On" 2 "DevSts4_Err" 3 "DevSts4_Resd";
VAL_ 594 StsOfLedRiLogoLamp 0 "DevSts4_Off" 1 "DevSts4_On" 2 "DevSts4_Err" 3 "DevSts4_Resd";
VAL_ 127 DwnLoadStsFbOfHdlampRi 0 "Sts_Resd" 1 "Sts_Err" 2 "Sts_CmplOk" 3 "Sts_InProgs";
VAL_ 127 DwnLoadStsFbOfLogoLampRi 0 "Sts_Resd" 1 "Sts_Err" 2 "Sts_CmplOk" 3 "Sts_InProgs";
VAL_ 127 ExtrLiShowActvnFrntRiFb 0 "Sts_Resd" 1 "Sts_Err" 2 "Sts_CmplOk" 3 "Sts_InProgs";
VAL_ 127 ExtrLiShowActvnRiLogoFb 0 "Sts_Resd" 1 "Sts_Err" 2 "Sts_CmplOk" 3 "Sts_InProgs";
VAL_ 127 HdlampRiInpSts1 0 "Boolean_FALSE" 1 "Boolean_TRUE";
VAL_ 127 HdlampRiInpSts2 0 "Boolean_FALSE" 1 "Boolean_TRUE";
VAL_ 127 StsOfAfsRi 0 "DevSts4_Off" 1 "DevSts4_On" 2 "DevSts4_Err" 3 "DevSts4_Resd";
VAL_ 127 StsOfAhbcRi 0 "DevSts4_Off" 1 "DevSts4_On" 2 "DevSts4_Err" 3 "DevSts4_Resd";
VAL_ 127 StsOfFrntSideMkrLampRi2 0 "DevSts4_Off" 1 "DevSts4_On" 2 "DevSts4_Err" 3 "DevSts4_Resd";
VAL_ 127 StsOfLedCornrgLampRi 0 "DevSts4_Off" 1 "DevSts4_On" 2 "DevSts4_Err" 3 "DevSts4_Resd";
VAL_ 127 StsOfLedDaytiRunngLampRi 0 "DevSts4_Off" 1 "DevSts4_On" 2 "DevSts4_Err" 3 "DevSts4_Resd";
VAL_ 127 StsOfLedFrntFogLampRi 0 "DevSts4_Off" 1 "DevSts4_On" 2 "DevSts4_Err" 3 "DevSts4_Resd";
VAL_ 127 StsOfLedFrntPosnLampRi 0 "DevSts4_Off" 1 "DevSts4_On" 2 "DevSts4_Err" 3 "DevSts4_Resd";
VAL_ 127 StsOfLedFrntTurnIndcrRi 0 "DevSts4_Off" 1 "DevSts4_On" 2 "DevSts4_Err" 3 "DevSts4_Resd";
VAL_ 127 StsOfLvlgRiStsOfLvlgRi 0 "DevSts4_Off" 1 "DevSts4_On" 2 "DevSts4_Err" 3 "DevSts4_Resd";
VAL_ 127 StsOfSwvlgRi 0 "DevSts4_Off" 1 "DevSts4_On" 2 "DevSts4_Err" 3 "DevSts4_Resd";
VAL_ 127 StsOfTouristModRi 0 "DevSts4_Off" 1 "DevSts4_On" 2 "DevSts4_Err" 3 "DevSts4_Resd";
VAL_ 127 StsOfWelGbyFrntRi 0 "OnOff1_Off" 1 "OnOff1_On";
VAL_ 1330 WakeUpReasonsforHCMR 0 "WakeupReasons_0" 1 "WakeupReasons_667950" 2 "WakeupReasons_169654" 3 "WakeupReasons_667951" 4 "WakeupReasons_168965" 5 "WakeupReasons_197643" 6 "WakeupReasons_264933" 7 "WakeupReasons_45654" 8 "WakeupReasons_22058" 9 "WakeupReasons_49446" 10 "WakeupReasons_22060" 11 "WakeupReasons_269740" 12 "WakeupReasons_269735" 13 "WakeupReasons_269739" 14 "WakeupReasons_658500" 15 "WakeupReasons_21901" 16 "WakeupReasons_45793" 17 "WakeupReasons_45794" 18 "WakeupReasons_22005" 19 "WakeupReasons_22013" 20 "WakeupReasons_22100" 21 "WakeupReasons_45659" 22 "WakeupReasons_45657" 23 "WakeupReasons_140084" 24 "WakeupReasons_21973" 25 "WakeupReasons_91253" 26 "WakeupReasons_88123" 27 "WakeupReasons_88125" 28 "WakeupReasons_321583" 29 "WakeupReasons_74188" 30 "WakeupReasons_667945" 31 "WakeupReasons_169655" 32 "WakeupReasons_667948" 33 "WakeupReasons_168966" 34 "WakeupReasons_170865" 35 "WakeupReasons_197642" 36 "WakeupReasons_264876" 37 "WakeupReasons_191050" 38 "WakeupReasons_182033" 39 "WakeupReasons_200937" 40 "WakeupReasons_170807" 41 "WakeupReasons_319139" 42 "WakeupReasons_100298" 43 "WakeupReasons_100275" 44 "WakeupReasons_100300" 45 "WakeupReasons_100278" 46 "WakeupReasons_100281" 47 "WakeupReasons_265333" 48 "WakeupReasons_108776" 49 "WakeupReasons_176921" 50 "WakeupReasons_197826" 51 "WakeupReasons_185670" 52 "WakeupReasons_161066" 53 "WakeupReasons_200156" 54 "WakeupReasons_225696" 55 "WakeupReasons_21997" 56 "WakeupReasons_45656" 57 "WakeupReasons_266860" 58 "WakeupReasons_169894" 59 "WakeupReasons_320282" 60 "WakeupReasons_319422" 61 "WakeupReasons_320277" 62 "WakeupReasons_355601" 63 "WakeupReasons_360904" 64 "WakeupReasons_361505" 65 "WakeupReasons_361509" 66 "WakeupReasons_645094" 67 "WakeupReasons_68676" 68 "WakeupReasons_360008" 69 "WakeupReasons_109382" 70 "WakeupReasons_119273" 71 "WakeupReasons_224065" 72 "WakeupReasons_68644" 73 "WakeupReasons_109364" 74 "WakeupReasons_68481" 75 "WakeupReasons_224061" 76 "WakeupReasons_360006" 77 "WakeupReasons_138997" 78 "WakeupReasons_634696" 79 "WakeupReasons_645810" 80 "WakeupReasons_297868" 81 "WakeupReasons_315364" 82 "WakeupReasons_109367" 83 "WakeupReasons_320126" 84 "WakeupReasons_109387" 85 "WakeupReasons_634710" 86 "WakeupReasons_338820" 87 "WakeupReasons_67182" 88 "WakeupReasons_152237" 89 "WakeupReasons_145707" 90 "WakeupReasons_199172" 91 "WakeupReasons_144897" 92 "WakeupReasons_186489" 93 "WakeupReasons_144970" 94 "WakeupReasons_152786" 95 "WakeupReasons_264932" 96 "WakeupReasons_264934" 97 "WakeupReasons_356190" 98 "WakeupReasons_145688" 99 "WakeupReasons_95444" 100 "WakeupReasons_169945" 101 "WakeupReasons_140678" 102 "WakeupReasons_222553" 103 "WakeupReasons_224831" 104 "WakeupReasons_201815" 105 "WakeupReasons_45864" 106 "WakeupReasons_659549" 107 "WakeupReasons_45866" 108 "WakeupReasons_45867" 109 "WakeupReasons_169884" 110 "WakeupReasons_264962" 111 "WakeupReasons_201348" 112 "WakeupReasons_320287" 113 "WakeupReasons_156412" 114 "WakeupReasons_133749" 115 "WakeupReasons_355409" 116 "WakeupReasons_636692" 117 "WakeupReasons_533044" 118 "WakeupReasons_106774" 119 "WakeupReasons_145311" 120 "WakeupReasons_145319" 121 "WakeupReasons_152774" 122 "WakeupReasons_145330" 123 "WakeupReasons_145388" 124 "WakeupReasons_145399" 125 "WakeupReasons_145362" 126 "WakeupReasons_145385" 127 "WakeupReasons_145373" 128 "WakeupReasons_145288" 129 "WakeupReasons_145419" 130 "WakeupReasons_145454" 131 "WakeupReasons_145462" 132 "WakeupReasons_269156" 133 "WakeupReasons_300427" 134 "WakeupReasons_220322" 135 "WakeupReasons_224617" 136 "WakeupReasons_224634" 137 "WakeupReasons_300682" 138 "WakeupReasons_264958" 139 "WakeupReasons_160597" 140 "WakeupReasons_160602" 141 "WakeupReasons_108841" 142 "WakeupReasons_265569" 143 "WakeupReasons_526429" 144 "WakeupReasons_514545" 145 "WakeupReasons_265232" 146 "WakeupReasons_644550" 147 "WakeupReasons_317616" 148 "WakeupReasons_354791" 149 "WakeupReasons_320631" 150 "WakeupReasons_337565" 151 "WakeupReasons_532007" 152 "WakeupReasons_514503" 153 "WakeupReasons_299117" 154 "WakeupReasons_340667" 155 "WakeupReasons_321845" 156 "WakeupReasons_179103" 157 "WakeupReasons_108810" 158 "WakeupReasons_322857" 159 "WakeupReasons_658603" 160 "WakeupReasons_197648" 161 "WakeupReasons_160596" 162 "WakeupReasons_361272" 163 "WakeupReasons_361279" 164 "WakeupReasons_265305" 165 "WakeupReasons_265328" 166 "WakeupReasons_265330" 167 "WakeupReasons_298808" 168 "WakeupReasons_515804" 169 "WakeupReasons_514502" 170 "WakeupReasons_645753" 171 "WakeupReasons_646109" 172 "WakeupReasons_299547" 173 "WakeupReasons_318342" 174 "WakeupReasons_360543" 175 "WakeupReasons_356549" 176 "WakeupReasons_198484" 177 "WakeupReasons_300681" 178 "WakeupReasons_359211" 179 "WakeupReasons_534077" 180 "WakeupReasons_525705" 181 "WakeupReasons_360299" 182 "WakeupReasons_526445" 183 "WakeupReasons_534145" 184 "WakeupReasons_192030" 185 "WakeupReasons_652361" 186 "WakeupReasons_355214" 187 "WakeupReasons_321317" 188 "WakeupReasons_359187" 189 "WakeupReasons_321057" 190 "WakeupReasons_321319" 191 "WakeupReasons_321323" 192 "WakeupReasons_321077" 193 "WakeupReasons_320895" 194 "WakeupReasons_655340" 195 "WakeupReasons_636556" 196 "WakeupReasons_108834" 197 "WakeupReasons_265937" 198 "WakeupReasons_533050" 199 "WakeupReasons_526426" 200 "WakeupReasons_264712" 201 "WakeupReasons_319401" 202 "WakeupReasons_643973" 203 "WakeupReasons_223715" 204 "WakeupReasons_199159" 205 "WakeupReasons_318382" 206 "WakeupReasons_226967" 207 "WakeupReasons_531743" 208 "WakeupReasons_360542" 209 "WakeupReasons_264726" 210 "WakeupReasons_535214" 211 "WakeupReasons_335068" 212 "WakeupReasons_316796" 213 "WakeupReasons_526438" 214 "WakeupReasons_198433" 215 "WakeupReasons_225961" 216 "WakeupReasons_197665" 217 "WakeupReasons_224550" 218 "WakeupReasons_667962" 219 "WakeupReasons_667953" 220 "WakeupReasons_110885" 221 "WakeupReasons_224552" 222 "WakeupReasons_224553" 223 "WakeupReasons_652546" 224 "WakeupReasons_331194" 225 "WakeupReasons_667820" 226 "WakeupReasons_659350" 227 "WakeupReasons_101706" 228 "WakeupReasons_101725" 229 "WakeupReasons_101728" 230 "WakeupReasons_101727" 231 "WakeupReasons_166267" 232 "WakeupReasons_156440" 233 "WakeupReasons_95949" 234 "WakeupReasons_112799" 235 "WakeupReasons_146470" 236 "WakeupReasons_176748" 237 "WakeupReasons_223920" 238 "WakeupReasons_668531" 239 "WakeupReasons_670087" 240 "WakeupReasons_668529" 241 "WakeupReasons_45858" 242 "WakeupReasons_315981" 243 "WakeupReasons_533370" 244 "WakeupReasons_533371" 245 "WakeupReasons_533372" 246 "WakeupReasons_241902" 247 "WakeupReasons_359559" 248 "WakeupReasons_516327" 249 "WakeupReasons_533872" 250 "WakeupReasons_45856" 251 "WakeupReasons_45853" 252 "WakeupReasons_45854" 253 "WakeupReasons_45852" 254 "WakeupReasons_45851" 255 "WakeupReasons_45850" 256 "WakeupReasons_45849" 257 "WakeupReasons_636801" 258 "WakeupReasons_109466" 259 "WakeupReasons_109467" 260 "WakeupReasons_670345" 261 "WakeupReasons_NMPDUReceived" 262 "WakeupReasons_358832" 263 "WakeupReasons_200683" 264 "WakeupReasons_198452" 265 "WakeupReasons_185457" 266 "WakeupReasons_185490" 267 "WakeupReasons_4471" 268 "WakeupReasons_269034" 269 "WakeupReasons_215560" 270 "WakeupReasons_312881" 271 "WakeupReasons_269140" 272 "WakeupReasons_197653" 273 "WakeupReasons_337991" 274 "WakeupReasons_658188" 275 "WakeupReasons_674953" 276 "WakeupReasons_675064" 277 "WakeupReasons_674958" 278 "WakeupReasons_675494" 279 "WakeupReasons_675837" 280 "WakeupReasons_667879" 281 "WakeupReasons_667947" 282 "WakeupReasons_676265" 283 "WakeupReasons_669465" 284 "WakeupReasons_670928" 285 "WakeupReasons_669447" 286 "WakeupReasons_667922" 287 "WakeupReasons_670753" 288 "WakeupReasons_668395" 289 "WakeupReasons_668393" 290 "WakeupReasons_667850" 291 "WakeupReasons_667848" 292 "WakeupReasons_311279" 293 "WakeupReasons_182918" 294 "WakeupReasons_667988" 295 "WakeupReasons_532555" 296 "WakeupReasons_532556" 297 "WakeupReasons_113348" 298 "WakeupReasons_193474" 299 "WakeupReasons_667871" 300 "WakeupReasons_670966" 301 "WakeupReasons_667985" 302 "WakeupReasons_670354" 303 "WakeupReasons_46017" 304 "WakeupReasons_675742" 305 "WakeupReasons_106669" 306 "WakeupReasons_80609" 307 "WakeupReasons_199714" 308 "WakeupReasons_200090" 309 "WakeupReasons_139075" 310 "WakeupReasons_268983" 311 "WakeupReasons_265131" 312 "WakeupReasons_263473" 313 "WakeupReasons_45887" 314 "WakeupReasons_69678" 315 "WakeupReasons_69679" 316 "WakeupReasons_45897" 317 "WakeupReasons_45898" 318 "WakeupReasons_80608" 319 "WakeupReasons_45869" 320 "WakeupReasons_45870" 321 "WakeupReasons_45872" 322 "WakeupReasons_45875" 323 "WakeupReasons_45871" 324 "WakeupReasons_45876" 325 "WakeupReasons_667980" 326 "WakeupReasons_45877" 327 "WakeupReasons_667973" 328 "WakeupReasons_670962" 329 "WakeupReasons_45888" 330 "WakeupReasons_45890" 331 "WakeupReasons_667869" 332 "WakeupReasons_45846" 333 "WakeupReasons_45847" 334 "WakeupReasons_45848" 335 "WakeupReasons_262872" 336 "WakeupReasons_127924" 337 "WakeupReasons_127926" 338 "WakeupReasons_674223" 339 "WakeupReasons_667982" 340 "WakeupReasons_657121" 341 "WakeupReasons_265745" 342 "WakeupReasons_657120" 343 "WakeupReasons_675564" 344 "WakeupReasons_197644" 345 "WakeupReasons_264943" 346 "WakeupReasons_264697" 347 "WakeupReasons_69216" 348 "WakeupReasons_128671" 349 "WakeupReasons_356598" 350 "WakeupReasons_675745" 351 "WakeupReasons_667983" 352 "WakeupReasons_667987" 353 "WakeupReasons_75103" 354 "WakeupReasons_305818" 355 "WakeupReasons_670942" 356 "WakeupReasons_532932" 357 "WakeupReasons_532933" 358 "WakeupReasons_83199" 359 "WakeupReasons_45900" 360 "WakeupReasons_88458" 361 "WakeupReasons_329457" 362 "WakeupReasons_45902" 363 "WakeupReasons_224211" 364 "WakeupReasons_667981" 365 "WakeupReasons_667874" 366 "WakeupReasons_46020" 367 "WakeupReasons_667842" 368 "WakeupReasons_145161" 369 "WakeupReasons_233755" 370 "WakeupReasons_297056" 371 "WakeupReasons_264691" 372 "WakeupReasons_262871" 373 "WakeupReasons_264964" 374 "WakeupReasons_667872" 375 "WakeupReasons_45655" 376 "WakeupReasons_177214" 377 "WakeupReasons_671005" 378 "WakeupReasons_680712" 379 "WakeupReasons_669822" 380 "WakeupReasons_668523" 381 "WakeupReasons_680974" 382 "WakeupReasons_680975" 383 "WakeupReasons_681028" 384 "WakeupReasons_670462" 385 "WakeupReasons_681134" 386 "WakeupReasons_681031" 387 "WakeupReasons_681711" 388 "WakeupReasons_682034" 389 "WakeupReasons_674839" 390 "WakeupReasons_681915" 391 "WakeupReasons_682032" 392 "WakeupReasons_682037" 393 "WakeupReasons_682688" 394 "WakeupReasons_681789" 395 "WakeupReasons_682023" 396 "WakeupReasons_681023" 397 "WakeupReasons_676285" 398 "WakeupReasons_682077" 399 "WakeupReasons_682076" 400 "WakeupReasons_682078" 401 "WakeupReasons_682153" 402 "WakeupReasons_682155" 403 "WakeupReasons_682152" 404 "WakeupReasons_682154" 405 "WakeupReasons_682074" 406 "WakeupReasons_680763" 407 "WakeupReasons_683934" 408 "WakeupReasons_265678" 409 "WakeupReasons_170285" 410 "WakeupReasons_200637" 411 "WakeupReasons_346654" 412 "WakeupReasons_91254" 413 "WakeupReasons_692021" 414 "WakeupReasons_690385" 415 "WakeupReasons_170290" 416 "WakeupReasons_357498" 417 "WakeupReasons_360491" 418 "WakeupReasons_265699" 419 "WakeupReasons_265698" 420 "WakeupReasons_641482" 421 "WakeupReasons_641483" 422 "WakeupReasons_168968" 423 "WakeupReasons_354674" 424 "WakeupReasons_168967" 425 "WakeupReasons_354672" 426 "WakeupReasons_112027" 427 "WakeupReasons_112035" 428 "WakeupReasons_692020" 429 "WakeupReasons_226565" 430 "WakeupReasons_675594" 431 "WakeupReasons_226571" 432 "WakeupReasons_690593" 433 "WakeupReasons_692022" 434 "WakeupReasons_354809" 435 "WakeupReasons_690939" 436 "WakeupReasons_677781" 437 "WakeupReasons_110173" 438 "WakeupReasons_112031" 439 "WakeupReasons_45896" 440 "WakeupReasons_226569" 441 "WakeupReasons_110181" 442 "WakeupReasons_654489" 443 "WakeupReasons_226570" 444 "WakeupReasons_351189" 445 "WakeupReasons_644275" 446 "WakeupReasons_45895" 447 "WakeupReasons_680765" 448 "WakeupReasons_354831" 449 "WakeupReasons_692439" 450 "WakeupReasons_265694" 451 "WakeupReasons_273516" 452 "WakeupReasons_299120" 453 "WakeupReasons_299531" 454 "WakeupReasons_299532" 455 "WakeupReasons_300690" 456 "WakeupReasons_112024" 457 "WakeupReasons_514651" 458 "WakeupReasons_514652" 459 "WakeupReasons_667188" 460 "WakeupReasons_533849" 461 "WakeupReasons_533850" 462 "WakeupReasons_692019" 463 "WakeupReasons_512384" 464 "WakeupReasons_680764" 465 "WakeupReasons_686281" 466 "WakeupReasons_667949" 467 "WakeupReasons_693005" 468 "WakeupReasons_693024" 469 "WakeupReasons_693914" 470 "WakeupReasons_692547" 471 "WakeupReasons_691991" 472 "WakeupReasons_698488" 473 "WakeupReasons_637992" 474 "WakeupReasons_702197" 475 "WakeupReasons_700425" 476 "WakeupReasons_700485" 477 "WakeupReasons_691993" 478 "WakeupReasons_698660" 479 "WakeupReasons_698288" 480 "WakeupReasons_681813" 481 "WakeupReasons_687404" 482 "WakeupReasons_700467" 483 "WakeupReasons_533750" 484 "WakeupReasons_698409" 485 "WakeupReasons_700686" 486 "WakeupReasons_700687" 487 "WakeupReasons_296931" 488 "WakeupReasons_697145" 489 "WakeupReasons_702174" 490 "WakeupReasons_194966" 491 "WakeupReasons_217907" 492 "WakeupReasons_700484" 493 "WakeupReasons_701508" 494 "WakeupReasons_701509" 495 "WakeupReasons_700215" 496 "WakeupReasons_700603" 497 "WakeupReasons_702204" 498 "WakeupReasons_700483" 499 "WakeupReasons_691994" 500 "WakeupReasons_696612" 501 "WakeupReasons_702088" 502 "WakeupReasons_696850" 503 "WakeupReasons_698129" 504 "WakeupReasons_691992" 505 "WakeupReasons_700554" 506 "WakeupReasons_683263" 507 "WakeupReasons_336435" 508 "WakeupReasons_644379" 509 "WakeupReasons_700684" 510 "WakeupReasons_697967" 511 "WakeupReasons_699922" 512 "WakeupReasons_698385" 513 "WakeupReasons_700692" 514 "WakeupReasons_696971" 515 "WakeupReasons_700782" 516 "WakeupReasons_700486" 517 "WakeupReasons_699919" 518 "WakeupReasons_699921" 519 "WakeupReasons_700130" 520 "WakeupReasons_698130" 521 "WakeupReasons_698581" 522 "WakeupReasons_533751" 523 "WakeupReasons_701270" 524 "WakeupReasons_702240" 525 "WakeupReasons_699114" 526 "WakeupReasons_701872" 527 "WakeupReasons_702448" 528 "WakeupReasons_702439" 529 "WakeupReasons_702402" 530 "WakeupReasons_700565" 531 "WakeupReasons_702452" 532 "WakeupReasons_698631" 533 "WakeupReasons_700530" 534 "WakeupReason_713752" 535 "WakeupReason_702478" 536 "WakeupReason_714675" 537 "WakeupReason_713786" 538 "WakeupReason_716243" 539 "WakeupReason_710922" 540 "WakeupReason_714030" 541 "WakeupReason_715842" 542 "WakeupReason_714678" 543 "WakeupReason_714679" 544 "WakeupReason_710807" 545 "WakeupReason_713568" 546 "WakeupReason_706194" 547 "WakeupReason_713799" 548 "WakeupReason_714172" 549 "WakeupReason_714265" 550 "WakeupReason_715529" 551 "WakeupReason_708964" 552 "WakeupReason_710893" 553 "WakeupReason_709196" 554 "WakeupReason_714806" 555 "WakeupReason_714799" 556 "WakeupReason_714697" 557 "WakeupReason_717832" 558 "WakeupReason_838116" 559 "WakeupReason_839473" 560 "WakeupReason_839705" 561 "WakeupReason_837833" 562 "WakeupReason_703140" 563 "WakeupReason_837962" 564 "WakeupReason_702903" 565 "WakeupReason_837760" 566 "WakeupReason_839458" 576 "WakeupReason_840035" 577 "WakeupReason_714677" 578 "WakeupReason_839181" 579 "WakeupReason_839787" 580 "WakeupReason_841275" 581 "WakeupReason_320145" 582 "WakeupReason_322113" 583 "WakeupReason_298032" 584 "WakeupReason_675452" 585 "WakeupReason_675489" 586 "WakeupReason_846372" 587 "WakeupReason_842273" 588 "WakeupReason_845930" 589 "WakeupReason_846002" 590 "WakeupReason_361441" 591 "WakeupReason_361474" 592 "WakeupReason_362462" 593 "WakeupReason_645735" 594 "WakeupReason_667533" 595 "WakeupReason_702420" 596 "WakeupReason_851482" 597 "WakeupReason_851743" 598 "WakeupReason_852010" 599 "WakeupReason_852050" 600 "WakeupReason_852180" 601 "WakeupReason_852184" 602 "WakeupReason_852194" 603 "WakeupReason_852195" 604 "WakeupReason_852200" 605 "WakeupReason_852215" 606 "WakeupReason_852218" 607 "WakeupReason_852219" 608 "WakeupReason_852248" 609 "WakeupReason_852273" 610 "WakeupReason_852298" 611 "WakeupReason_852385" 612 "WakeupReason_852388" 613 "WakeupReason_852537" 614 "WakeupReason_852646" 615 "WakeupReason_852944" 616 "WakeupReason_852947";
VAL_ 1346 VFCVectorZCUDMVFCid0 0 "VFCOnOff_Off" 1 "VFCOnOff_On";
VAL_ 1346 VFCVectorZCUDMVFCid1 0 "VFCOnOff_Off" 1 "VFCOnOff_On";
VAL_ 1346 VFCVectorZCUDMVFCid10 0 "VFCOnOff_Off" 1 "VFCOnOff_On";
VAL_ 1346 VFCVectorZCUDMVFCid11 0 "VFCOnOff_Off" 1 "VFCOnOff_On";
VAL_ 1346 VFCVectorZCUDMVFCid12 0 "VFCOnOff_Off" 1 "VFCOnOff_On";
VAL_ 1346 VFCVectorZCUDMVFCid13 0 "VFCOnOff_Off" 1 "VFCOnOff_On";
VAL_ 1346 VFCVectorZCUDMVFCid14 0 "VFCOnOff_Off" 1 "VFCOnOff_On";
VAL_ 1346 VFCVectorZCUDMVFCid15 0 "VFCOnOff_Off" 1 "VFCOnOff_On";
VAL_ 1346 VFCVectorZCUDMVFCid16 0 "VFCOnOff_Off" 1 "VFCOnOff_On";
VAL_ 1346 VFCVectorZCUDMVFCid17 0 "VFCOnOff_Off" 1 "VFCOnOff_On";
VAL_ 1346 VFCVectorZCUDMVFCid18 0 "VFCOnOff_Off" 1 "VFCOnOff_On";
VAL_ 1346 VFCVectorZCUDMVFCid19 0 "VFCOnOff_Off" 1 "VFCOnOff_On";
VAL_ 1346 VFCVectorZCUDMVFCid2 0 "VFCOnOff_Off" 1 "VFCOnOff_On";
VAL_ 1346 VFCVectorZCUDMVFCid20 0 "VFCOnOff_Off" 1 "VFCOnOff_On";
VAL_ 1346 VFCVectorZCUDMVFCid21 0 "VFCOnOff_Off" 1 "VFCOnOff_On";
VAL_ 1346 VFCVectorZCUDMVFCid22 0 "VFCOnOff_Off" 1 "VFCOnOff_On";
VAL_ 1346 VFCVectorZCUDMVFCid23 0 "VFCOnOff_Off" 1 "VFCOnOff_On";
VAL_ 1346 VFCVectorZCUDMVFCid24 0 "VFCOnOff_Off" 1 "VFCOnOff_On";
VAL_ 1346 VFCVectorZCUDMVFCid25 0 "VFCOnOff_Off" 1 "VFCOnOff_On";
VAL_ 1346 VFCVectorZCUDMVFCid26 0 "VFCOnOff_Off" 1 "VFCOnOff_On";
VAL_ 1346 VFCVectorZCUDMVFCid27 0 "VFCOnOff_Off" 1 "VFCOnOff_On";
VAL_ 1346 VFCVectorZCUDMVFCid28 0 "VFCOnOff_Off" 1 "VFCOnOff_On";
VAL_ 1346 VFCVectorZCUDMVFCid29 0 "VFCOnOff_Off" 1 "VFCOnOff_On";
VAL_ 1346 VFCVectorZCUDMVFCid3 0 "VFCOnOff_Off" 1 "VFCOnOff_On";
VAL_ 1346 VFCVectorZCUDMVFCid30 0 "VFCOnOff_Off" 1 "VFCOnOff_On";
VAL_ 1346 VFCVectorZCUDMVFCid31 0 "VFCOnOff_Off" 1 "VFCOnOff_On";
VAL_ 1346 VFCVectorZCUDMVFCid32 0 "VFCOnOff_Off" 1 "VFCOnOff_On";
VAL_ 1346 VFCVectorZCUDMVFCid33 0 "VFCOnOff_Off" 1 "VFCOnOff_On";
VAL_ 1346 VFCVectorZCUDMVFCid34 0 "VFCOnOff_Off" 1 "VFCOnOff_On";
VAL_ 1346 VFCVectorZCUDMVFCid35 0 "VFCOnOff_Off" 1 "VFCOnOff_On";
VAL_ 1346 VFCVectorZCUDMVFCid36 0 "VFCOnOff_Off" 1 "VFCOnOff_On";
VAL_ 1346 VFCVectorZCUDMVFCid37 0 "VFCOnOff_Off" 1 "VFCOnOff_On";
VAL_ 1346 VFCVectorZCUDMVFCid38 0 "VFCOnOff_Off" 1 "VFCOnOff_On";
VAL_ 1346 VFCVectorZCUDMVFCid39 0 "VFCOnOff_Off" 1 "VFCOnOff_On";
VAL_ 1346 VFCVectorZCUDMVFCid4 0 "VFCOnOff_Off" 1 "VFCOnOff_On";
VAL_ 1346 VFCVectorZCUDMVFCid40 0 "VFCOnOff_Off" 1 "VFCOnOff_On";
VAL_ 1346 VFCVectorZCUDMVFCid41 0 "VFCOnOff_Off" 1 "VFCOnOff_On";
VAL_ 1346 VFCVectorZCUDMVFCid42 0 "VFCOnOff_Off" 1 "VFCOnOff_On";
VAL_ 1346 VFCVectorZCUDMVFCid43 0 "VFCOnOff_Off" 1 "VFCOnOff_On";
VAL_ 1346 VFCVectorZCUDMVFCid44 0 "VFCOnOff_Off" 1 "VFCOnOff_On";
VAL_ 1346 VFCVectorZCUDMVFCid45 0 "VFCOnOff_Off" 1 "VFCOnOff_On";
VAL_ 1346 VFCVectorZCUDMVFCid46 0 "VFCOnOff_Off" 1 "VFCOnOff_On";
VAL_ 1346 VFCVectorZCUDMVFCid47 0 "VFCOnOff_Off" 1 "VFCOnOff_On";
VAL_ 1346 VFCVectorZCUDMVFCid48 0 "VFCOnOff_Off" 1 "VFCOnOff_On";
VAL_ 1346 VFCVectorZCUDMVFCid49 0 "VFCOnOff_Off" 1 "VFCOnOff_On";
VAL_ 1346 VFCVectorZCUDMVFCid5 0 "VFCOnOff_Off" 1 "VFCOnOff_On";
VAL_ 1346 VFCVectorZCUDMVFCid50 0 "VFCOnOff_Off" 1 "VFCOnOff_On";
VAL_ 1346 VFCVectorZCUDMVFCid51 0 "VFCOnOff_Off" 1 "VFCOnOff_On";
VAL_ 1346 VFCVectorZCUDMVFCid52 0 "VFCOnOff_Off" 1 "VFCOnOff_On";
VAL_ 1346 VFCVectorZCUDMVFCid53 0 "VFCOnOff_Off" 1 "VFCOnOff_On";
VAL_ 1346 VFCVectorZCUDMVFCid54 0 "VFCOnOff_Off" 1 "VFCOnOff_On";
VAL_ 1346 VFCVectorZCUDMVFCid55 0 "VFCOnOff_Off" 1 "VFCOnOff_On";
VAL_ 1346 VFCVectorZCUDMVFCid56 0 "VFCOnOff_Off" 1 "VFCOnOff_On";
VAL_ 1346 VFCVectorZCUDMVFCid57 0 "VFCOnOff_Off" 1 "VFCOnOff_On";
VAL_ 1346 VFCVectorZCUDMVFCid58 0 "VFCOnOff_Off" 1 "VFCOnOff_On";
VAL_ 1346 VFCVectorZCUDMVFCid59 0 "VFCOnOff_Off" 1 "VFCOnOff_On";
VAL_ 1346 VFCVectorZCUDMVFCid6 0 "VFCOnOff_Off" 1 "VFCOnOff_On";
VAL_ 1346 VFCVectorZCUDMVFCid60 0 "VFCOnOff_Off" 1 "VFCOnOff_On";
VAL_ 1346 VFCVectorZCUDMVFCid61 0 "VFCOnOff_Off" 1 "VFCOnOff_On";
VAL_ 1346 VFCVectorZCUDMVFCid7 0 "VFCOnOff_Off" 1 "VFCOnOff_On";
VAL_ 1346 VFCVectorZCUDMVFCid8 0 "VFCOnOff_Off" 1 "VFCOnOff_On";
VAL_ 1346 VFCVectorZCUDMVFCid9 0 "VFCOnOff_Off" 1 "VFCOnOff_On";
SIG_GROUP_ 1119 DwnLoadDynLtgPrmForReGrp1 1 : DwnLoadDynLtgPrmForReGrp1ContinueTime DwnLoadDynLtgPrmForReGrp1HighBrightness DwnLoadDynLtgPrmForReGrp1LowBrightness DwnLoadDynLtgPrmForReGrp1Mode1 DwnLoadDynLtgPrmForReGrp1OffsetTime DwnLoadDynLtgPrmForReGrp1Timestamp;
SIG_GROUP_ 1146 DwnLoadDynLtgPrmForReGrp10 1 : DwnLoadDynLtgPrmForReGrp10ContinueTime DwnLoadDynLtgPrmForReGrp10HighBrightness DwnLoadDynLtgPrmForReGrp10LowBrightness DwnLoadDynLtgPrmForReGrp10Mode1 DwnLoadDynLtgPrmForReGrp10OffsetTime DwnLoadDynLtgPrmForReGrp10Timestamp;
SIG_GROUP_ 1151 DwnLoadDynLtgPrmForReGrp11 1 : DwnLoadDynLtgPrmForReGrp11ContinueTime DwnLoadDynLtgPrmForReGrp11HighBrightness DwnLoadDynLtgPrmForReGrp11LowBrightness DwnLoadDynLtgPrmForReGrp11Mode1 DwnLoadDynLtgPrmForReGrp11OffsetTime DwnLoadDynLtgPrmForReGrp11Timestamp;
SIG_GROUP_ 1151 DwnLoadDynLtgPrmForReGrp12 1 : DwnLoadDynLtgPrmForReGrp12ContinueTime DwnLoadDynLtgPrmForReGrp12HighBrightness DwnLoadDynLtgPrmForReGrp12LowBrightness DwnLoadDynLtgPrmForReGrp12Mode1 DwnLoadDynLtgPrmForReGrp12OffsetTime DwnLoadDynLtgPrmForReGrp12Timestamp;
SIG_GROUP_ 1157 DwnLoadDynLtgPrmForReGrp13 1 : DwnLoadDynLtgPrmForReGrp13ContinueTime DwnLoadDynLtgPrmForReGrp13HighBrightness DwnLoadDynLtgPrmForReGrp13LowBrightness DwnLoadDynLtgPrmForReGrp13Mode1 DwnLoadDynLtgPrmForReGrp13OffsetTime DwnLoadDynLtgPrmForReGrp13Timestamp;
SIG_GROUP_ 1157 DwnLoadDynLtgPrmForReGrp14 1 : DwnLoadDynLtgPrmForReGrp14ContinueTime DwnLoadDynLtgPrmForReGrp14HighBrightness DwnLoadDynLtgPrmForReGrp14LowBrightness DwnLoadDynLtgPrmForReGrp14Mode1 DwnLoadDynLtgPrmForReGrp14OffsetTime DwnLoadDynLtgPrmForReGrp14Timestamp;
SIG_GROUP_ 1165 DwnLoadDynLtgPrmForReGrp15 1 : DwnLoadDynLtgPrmForReGrp15ContinueTime DwnLoadDynLtgPrmForReGrp15HighBrightness DwnLoadDynLtgPrmForReGrp15LowBrightness DwnLoadDynLtgPrmForReGrp15Mode1 DwnLoadDynLtgPrmForReGrp15OffsetTime DwnLoadDynLtgPrmForReGrp15Timestamp;
SIG_GROUP_ 1165 DwnLoadDynLtgPrmForReGrp16 1 : DwnLoadDynLtgPrmForReGrp16ContinueTime DwnLoadDynLtgPrmForReGrp16HighBrightness DwnLoadDynLtgPrmForReGrp16LowBrightness DwnLoadDynLtgPrmForReGrp16Mode1 DwnLoadDynLtgPrmForReGrp16OffsetTime DwnLoadDynLtgPrmForReGrp16Timestamp;
SIG_GROUP_ 1167 DwnLoadDynLtgPrmForReGrp17 1 : DwnLoadDynLtgPrmForReGrp17ContinueTime DwnLoadDynLtgPrmForReGrp17HighBrightness DwnLoadDynLtgPrmForReGrp17LowBrightness DwnLoadDynLtgPrmForReGrp17Mode1 DwnLoadDynLtgPrmForReGrp17OffsetTime DwnLoadDynLtgPrmForReGrp17Timestamp;
SIG_GROUP_ 1167 DwnLoadDynLtgPrmForReGrp18 1 : DwnLoadDynLtgPrmForReGrp18ContinueTime DwnLoadDynLtgPrmForReGrp18HighBrightness DwnLoadDynLtgPrmForReGrp18LowBrightness DwnLoadDynLtgPrmForReGrp18Mode1 DwnLoadDynLtgPrmForReGrp18OffsetTime DwnLoadDynLtgPrmForReGrp18Timestamp;
SIG_GROUP_ 1178 DwnLoadDynLtgPrmForReGrp19 1 : DwnLoadDynLtgPrmForReGrp19ContinueTime DwnLoadDynLtgPrmForReGrp19HighBrightness DwnLoadDynLtgPrmForReGrp19LowBrightness DwnLoadDynLtgPrmForReGrp19Mode1 DwnLoadDynLtgPrmForReGrp19OffsetTime DwnLoadDynLtgPrmForReGrp19Timestamp;
SIG_GROUP_ 1119 DwnLoadDynLtgPrmForReGrp2 1 : DwnLoadDynLtgPrmForReGrp2ContinueTime DwnLoadDynLtgPrmForReGrp2HighBrightness DwnLoadDynLtgPrmForReGrp2LowBrightness DwnLoadDynLtgPrmForReGrp2Mode1 DwnLoadDynLtgPrmForReGrp2OffsetTime DwnLoadDynLtgPrmForReGrp2Timestamp;
SIG_GROUP_ 1178 DwnLoadDynLtgPrmForReGrp20 1 : DwnLoadDynLtgPrmForReGrp20ContinueTime DwnLoadDynLtgPrmForReGrp20HighBrightness DwnLoadDynLtgPrmForReGrp20LowBrightness DwnLoadDynLtgPrmForReGrp20Mode1 DwnLoadDynLtgPrmForReGrp20OffsetTime DwnLoadDynLtgPrmForReGrp20Timestamp;
SIG_GROUP_ 1183 DwnLoadDynLtgPrmForReGrp21 1 : DwnLoadDynLtgPrmForReGrp21ContinueTime DwnLoadDynLtgPrmForReGrp21HighBrightness DwnLoadDynLtgPrmForReGrp21LowBrightness DwnLoadDynLtgPrmForReGrp21Mode1 DwnLoadDynLtgPrmForReGrp21OffsetTime DwnLoadDynLtgPrmForReGrp21Timestamp;
SIG_GROUP_ 1183 DwnLoadDynLtgPrmForReGrp22 1 : DwnLoadDynLtgPrmForReGrp22ContinueTime DwnLoadDynLtgPrmForReGrp22HighBrightness DwnLoadDynLtgPrmForReGrp22LowBrightness DwnLoadDynLtgPrmForReGrp22Mode1 DwnLoadDynLtgPrmForReGrp22OffsetTime DwnLoadDynLtgPrmForReGrp22Timestamp;
SIG_GROUP_ 1189 DwnLoadDynLtgPrmForReGrp23 1 : DwnLoadDynLtgPrmForReGrp23ContinueTime DwnLoadDynLtgPrmForReGrp23HighBrightness DwnLoadDynLtgPrmForReGrp23LowBrightness DwnLoadDynLtgPrmForReGrp23Mode1 DwnLoadDynLtgPrmForReGrp23OffsetTime DwnLoadDynLtgPrmForReGrp23Timestamp;
SIG_GROUP_ 1189 DwnLoadDynLtgPrmForReGrp24 1 : DwnLoadDynLtgPrmForReGrp24ContinueTime DwnLoadDynLtgPrmForReGrp24HighBrightness DwnLoadDynLtgPrmForReGrp24LowBrightness DwnLoadDynLtgPrmForReGrp24Mode1 DwnLoadDynLtgPrmForReGrp24OffsetTime DwnLoadDynLtgPrmForReGrp24Timestamp;
SIG_GROUP_ 1196 DwnLoadDynLtgPrmForReGrp25 1 : DwnLoadDynLtgPrmForReGrp25ContinueTime DwnLoadDynLtgPrmForReGrp25HighBrightness DwnLoadDynLtgPrmForReGrp25LowBrightness DwnLoadDynLtgPrmForReGrp25Mode1 DwnLoadDynLtgPrmForReGrp25OffsetTime DwnLoadDynLtgPrmForReGrp25Timestamp;
SIG_GROUP_ 1196 DwnLoadDynLtgPrmForReGrp26 1 : DwnLoadDynLtgPrmForReGrp26ContinueTime DwnLoadDynLtgPrmForReGrp26HighBrightness DwnLoadDynLtgPrmForReGrp26LowBrightness DwnLoadDynLtgPrmForReGrp26Mode1 DwnLoadDynLtgPrmForReGrp26OffsetTime DwnLoadDynLtgPrmForReGrp26Timestamp;
SIG_GROUP_ 1199 DwnLoadDynLtgPrmForReGrp27 1 : DwnLoadDynLtgPrmForReGrp27ContinueTime DwnLoadDynLtgPrmForReGrp27HighBrightness DwnLoadDynLtgPrmForReGrp27LowBrightness DwnLoadDynLtgPrmForReGrp27Mode1 DwnLoadDynLtgPrmForReGrp27OffsetTime DwnLoadDynLtgPrmForReGrp27Timestamp;
SIG_GROUP_ 1199 DwnLoadDynLtgPrmForReGrp28 1 : DwnLoadDynLtgPrmForReGrp28ContinueTime DwnLoadDynLtgPrmForReGrp28HighBrightness DwnLoadDynLtgPrmForReGrp28LowBrightness DwnLoadDynLtgPrmForReGrp28Mode1 DwnLoadDynLtgPrmForReGrp28OffsetTime DwnLoadDynLtgPrmForReGrp28Timestamp;
SIG_GROUP_ 1201 DwnLoadDynLtgPrmForReGrp29 1 : DwnLoadDynLtgPrmForReGrp29ContinueTime DwnLoadDynLtgPrmForReGrp29HighBrightness DwnLoadDynLtgPrmForReGrp29LowBrightness DwnLoadDynLtgPrmForReGrp29Mode1 DwnLoadDynLtgPrmForReGrp29OffsetTime DwnLoadDynLtgPrmForReGrp29Timestamp;
SIG_GROUP_ 1122 DwnLoadDynLtgPrmForReGrp3 1 : DwnLoadDynLtgPrmForReGrp3ContinueTime DwnLoadDynLtgPrmForReGrp3HighBrightness DwnLoadDynLtgPrmForReGrp3LowBrightness DwnLoadDynLtgPrmForReGrp3Mode1 DwnLoadDynLtgPrmForReGrp3OffsetTime DwnLoadDynLtgPrmForReGrp3Timestamp;
SIG_GROUP_ 1201 DwnLoadDynLtgPrmForReGrp30 1 : DwnLoadDynLtgPrmForReGrp30ContinueTime DwnLoadDynLtgPrmForReGrp30HighBrightness DwnLoadDynLtgPrmForReGrp30LowBrightness DwnLoadDynLtgPrmForReGrp30Mode1 DwnLoadDynLtgPrmForReGrp30OffsetTime DwnLoadDynLtgPrmForReGrp30Timestamp;
SIG_GROUP_ 1122 DwnLoadDynLtgPrmForReGrp4 1 : DwnLoadDynLtgPrmForReGrp4ContinueTime DwnLoadDynLtgPrmForReGrp4HighBrightness DwnLoadDynLtgPrmForReGrp4LowBrightness DwnLoadDynLtgPrmForReGrp4Mode1 DwnLoadDynLtgPrmForReGrp4OffsetTime DwnLoadDynLtgPrmForReGrp4Timestamp;
SIG_GROUP_ 1125 DwnLoadDynLtgPrmForReGrp5 1 : DwnLoadDynLtgPrmForReGrp5ContinueTime DwnLoadDynLtgPrmForReGrp5HighBrightness DwnLoadDynLtgPrmForReGrp5LowBrightness DwnLoadDynLtgPrmForReGrp5Mode1 DwnLoadDynLtgPrmForReGrp5OffsetTime DwnLoadDynLtgPrmForReGrp5Timestamp;
SIG_GROUP_ 1125 DwnLoadDynLtgPrmForReGrp6 1 : DwnLoadDynLtgPrmForReGrp6ContinueTime DwnLoadDynLtgPrmForReGrp6HighBrightness DwnLoadDynLtgPrmForReGrp6LowBrightness DwnLoadDynLtgPrmForReGrp6Mode1 DwnLoadDynLtgPrmForReGrp6OffsetTime DwnLoadDynLtgPrmForReGrp6Timestamp;
SIG_GROUP_ 1129 DwnLoadDynLtgPrmForReGrp7 1 : DwnLoadDynLtgPrmForReGrp7ContinueTime DwnLoadDynLtgPrmForReGrp7HighBrightness DwnLoadDynLtgPrmForReGrp7LowBrightness DwnLoadDynLtgPrmForReGrp7Mode1 DwnLoadDynLtgPrmForReGrp7OffsetTime DwnLoadDynLtgPrmForReGrp7Timestamp;
SIG_GROUP_ 1129 DwnLoadDynLtgPrmForReGrp8 1 : DwnLoadDynLtgPrmForReGrp8ContinueTime DwnLoadDynLtgPrmForReGrp8HighBrightness DwnLoadDynLtgPrmForReGrp8LowBrightness DwnLoadDynLtgPrmForReGrp8Mode1 DwnLoadDynLtgPrmForReGrp8OffsetTime DwnLoadDynLtgPrmForReGrp8Timestamp;
SIG_GROUP_ 1146 DwnLoadDynLtgPrmForReGrp9 1 : DwnLoadDynLtgPrmForReGrp9ContinueTime DwnLoadDynLtgPrmForReGrp9HighBrightness DwnLoadDynLtgPrmForReGrp9LowBrightness DwnLoadDynLtgPrmForReGrp9Mode1 DwnLoadDynLtgPrmForReGrp9OffsetTime DwnLoadDynLtgPrmForReGrp9Timestamp;
SIG_GROUP_ 124 StsOfLvlgLe 1 : StsOfLvlgLeChks StsOfLvlgLeCntr StsOfLvlgLeStsOfLvlgLe;
SIG_GROUP_ 127 StsOfLvlgRi 1 : StsOfLvlgRiChks StsOfLvlgRiCntr StsOfLvlgRiStsOfLvlgRi;
SIG_GROUP_ 1346 VFCVectorZCUDM 1 : VFCVectorZCUDMBlockID VFCVectorZCUDMVFCid0 VFCVectorZCUDMVFCid1 VFCVectorZCUDMVFCid10 VFCVectorZCUDMVFCid11 VFCVectorZCUDMVFCid12 VFCVectorZCUDMVFCid13 VFCVectorZCUDMVFCid14 VFCVectorZCUDMVFCid15 VFCVectorZCUDMVFCid16 VFCVectorZCUDMVFCid17 VFCVectorZCUDMVFCid18 VFCVectorZCUDMVFCid19 VFCVectorZCUDMVFCid2 VFCVectorZCUDMVFCid20 VFCVectorZCUDMVFCid21 VFCVectorZCUDMVFCid22 VFCVectorZCUDMVFCid23 VFCVectorZCUDMVFCid24 VFCVectorZCUDMVFCid25 VFCVectorZCUDMVFCid26 VFCVectorZCUDMVFCid27 VFCVectorZCUDMVFCid28 VFCVectorZCUDMVFCid29 VFCVectorZCUDMVFCid3 VFCVectorZCUDMVFCid30 VFCVectorZCUDMVFCid31 VFCVectorZCUDMVFCid32 VFCVectorZCUDMVFCid33 VFCVectorZCUDMVFCid34 VFCVectorZCUDMVFCid35 VFCVectorZCUDMVFCid36 VFCVectorZCUDMVFCid37 VFCVectorZCUDMVFCid38 VFCVectorZCUDMVFCid39 VFCVectorZCUDMVFCid4 VFCVectorZCUDMVFCid40 VFCVectorZCUDMVFCid41 VFCVectorZCUDMVFCid42 VFCVectorZCUDMVFCid43 VFCVectorZCUDMVFCid44 VFCVectorZCUDMVFCid45 VFCVectorZCUDMVFCid46 VFCVectorZCUDMVFCid47 VFCVectorZCUDMVFCid48 VFCVectorZCUDMVFCid49 VFCVectorZCUDMVFCid5 VFCVectorZCUDMVFCid50 VFCVectorZCUDMVFCid51 VFCVectorZCUDMVFCid52 VFCVectorZCUDMVFCid53 VFCVectorZCUDMVFCid54 VFCVectorZCUDMVFCid55 VFCVectorZCUDMVFCid56 VFCVectorZCUDMVFCid57 VFCVectorZCUDMVFCid58 VFCVectorZCUDMVFCid59 VFCVectorZCUDMVFCid6 VFCVectorZCUDMVFCid60 VFCVectorZCUDMVFCid61 VFCVectorZCUDMVFCid7 VFCVectorZCUDMVFCid8 VFCVectorZCUDMVFCid9;
